VERSION ""

NS_ :

BS_:

BU_: Skylark_EV

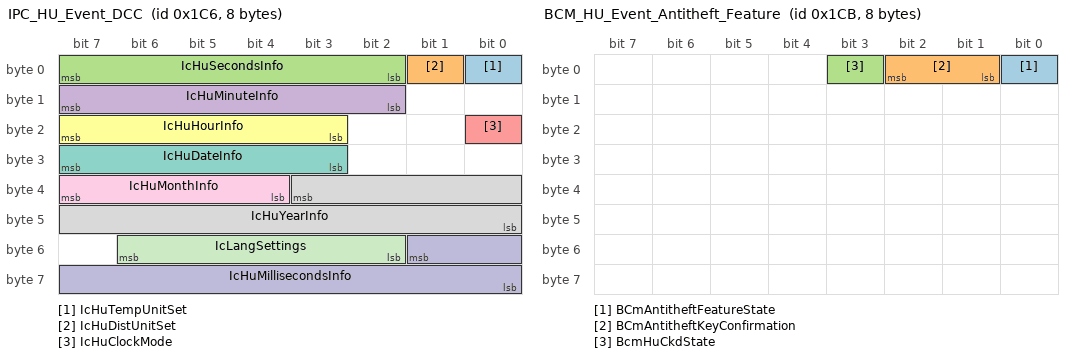
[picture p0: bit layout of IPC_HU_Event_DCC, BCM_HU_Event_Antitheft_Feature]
BO_ 454 IPC_HU_Event_DCC: 8 Vector__XXX
 SG_ IcHuTempUnitSet : 0|1@0+ (1,0) [0|1] ""  Skylark_EV
 SG_ IcHuDistUnitSet : 1|1@0+ (1,0) [0|1] ""  Skylark_EV
 SG_ IcHuSecondsInfo : 7|6@0+ (1,0) [0|59] "sec."  Skylark_EV
 SG_ IcHuMinuteInfo : 15|6@0+ (1,0) [0|59] "min"  Skylark_EV
 SG_ IcHuClockMode : 16|1@0+ (1,0) [0|1] ""  Skylark_EV
 SG_ IcHuHourInfo : 23|5@0+ (1,0) [0|23] "hr"  Skylark_EV
 SG_ IcHuDateInfo : 31|5@0+ (1,0) [0|31] ""  Skylark_EV
 SG_ IcHuYearInfo : 35|12@0+ (1,0) [0|4095] ""  Skylark_EV
 SG_ IcHuMonthInfo : 39|4@0+ (1,0) [0|15] ""  Skylark_EV
 SG_ IcHuMillisecondsInfo : 49|10@0+ (1,0) [0|999] "ms"  Skylark_EV
 SG_ IcLangSettings : 54|5@0+ (1,0) [0|31] ""  Skylark_EV

BO_ 459 BCM_HU_Event_Antitheft_Feature: 8 Vector__XXX
 SG_ BCmAntitheftFeatureState : 0|1@0+ (1,0) [0|1] ""  Skylark_EV
 SG_ BCmAntitheftKeyConfirmation : 2|2@0+ (1,0) [0|3] ""  Skylark_EV
 SG_ BcmHuCkdState : 3|1@0+ (1,0) [0|1] ""  Skylark_EV

BO_ 460 HU_BCM_Event_Antitheft_Feature: 8 Skylark_EV
 SG_ HuAntitheftFeatureState : 0|1@0+ (1,0) [0|1] "" Vector__XXX
 SG_ HuBcmQueryInfo : 2|2@0+ (1,0) [0|3] "" Vector__XXX

BO_ 462 BCM_HU_Event_Antitheft_Seed: 8 Vector__XXX
 SG_ BCmAntitheftSeed : 7|32@0+ (1,0) [0|4294967295] ""  Skylark_EV

BO_ 463 HU_BCM_Event_Antitheftkey: 8 Skylark_EV
 SG_ BCmAntitheftKey : 7|32@0+ (1,0) [0|4294967295] "" Vector__XXX

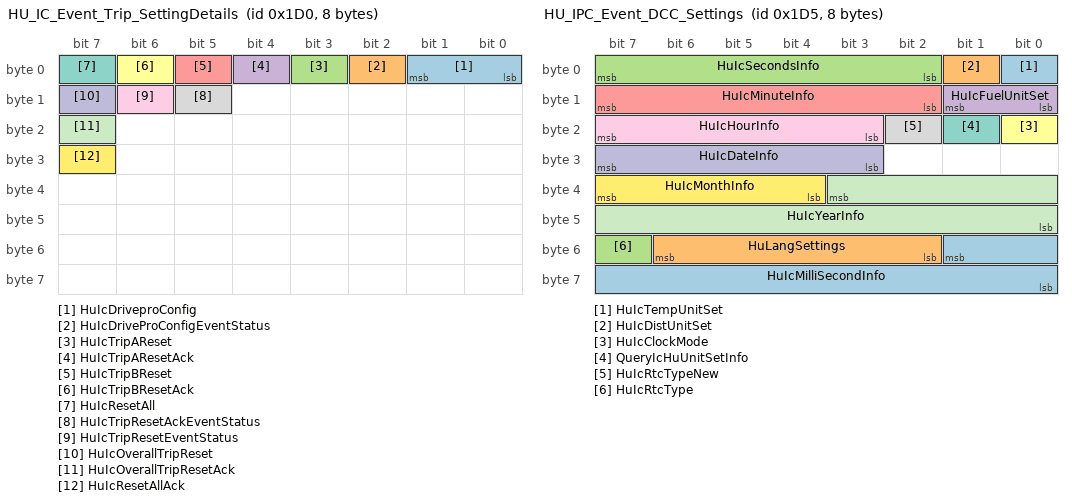
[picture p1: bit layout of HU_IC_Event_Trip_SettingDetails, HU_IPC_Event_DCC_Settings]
BO_ 464 HU_IC_Event_Trip_SettingDetails: 8 Skylark_EV
 SG_ HuIcDriveproConfig : 1|2@0+ (1,0) [0|3] "" Vector__XXX
 SG_ HuIcDriveProConfigEventStatus : 2|1@0+ (1,0) [0|1] "" Vector__XXX
 SG_ HuIcTripAReset : 3|1@0+ (1,0) [0|1] "" Vector__XXX
 SG_ HuIcTripAResetAck : 4|1@0+ (1,0) [0|1] "" Vector__XXX
 SG_ HuIcTripBReset : 5|1@0+ (1,0) [0|1] "" Vector__XXX
 SG_ HuIcTripBResetAck : 6|1@0+ (1,0) [0|1] "" Vector__XXX
 SG_ HuIcResetAll : 7|1@0+ (1,0) [0|1] "" Vector__XXX
 SG_ HuIcTripResetAckEventStatus : 13|1@0+ (1,0) [0|1] "" Vector__XXX
 SG_ HuIcTripResetEventStatus : 14|1@0+ (1,0) [0|1] "" Vector__XXX
 SG_ HuIcOverallTripReset : 15|1@0+ (1,0) [0|1] "" Vector__XXX
 SG_ HuIcOverallTripResetAck : 23|1@0+ (1,0) [0|1] "" Vector__XXX
 SG_ HuIcResetAllAck : 31|1@0+ (1,0) [0|1] "" Vector__XXX

BO_ 466 HU_PDC_Event: 8 Skylark_EV
 SG_ PDcOnDelayTimerReq : 7|8@0+ (1,0) [0|255] "sec" Vector__XXX
 SG_ HuPDcVehicleImageAck : 10|3@0+ (1,0) [0|7] "" Vector__XXX
 SG_ PDcLowSpeedActivationReq : 11|1@0+ (1,0) [0|1] "" Vector__XXX
 SG_ PDcRearToneReq : 15|4@0+ (1,0) [0|15] "" Vector__XXX
 SG_ HuPDcFrontAudioMuteStateAck : 16|1@0+ (1,0) [0|1] "" Vector__XXX
 SG_ HuPDcRearNoOfSensAck : 19|3@0+ (1,0) [0|7] "" Vector__XXX
 SG_ PDcToneVolumeReq : 23|4@0+ (1,0) [1|15] "" Vector__XXX
 SG_ HuPDcOnDelayTimerAck : 31|8@0+ (1,0) [0|255] "sec" Vector__XXX
 SG_ PDcFrontAudioMuteReq : 32|1@0+ (1,0) [0|1] "" Vector__XXX
 SG_ HuPDcReqType : 35|3@0+ (1,0) [0|7] "" Vector__XXX
 SG_ HuPDcRearToneAck : 39|4@0+ (1,0) [0|15] "" Vector__XXX
 SG_ HuPDcFrontToneAck : 43|4@0+ (1,0) [0|15] "" Vector__XXX
 SG_ HuPDcToneVolumeAck : 47|4@0+ (1,0) [0|15] "" Vector__XXX
 SG_ HuPDcFrontNoOfSensAck : 50|3@0+ (1,0) [0|7] "" Vector__XXX
 SG_ PDcFrontToneReq : 54|4@0+ (1,0) [0|15] "" Vector__XXX
 SG_ HuPDCFrontActivationStateAck : 55|1@0+ (1,0) [0|1] "" Vector__XXX
 SG_ PDcFrontActivationStateReq : 56|1@0+ (1,0) [0|1] "" Vector__XXX
 SG_ HuPDCLowSpeedActivationAck : 57|1@0+ (1,0) [0|1] "" Vector__XXX
 SG_ RVcOverlayTypeAck : 58|1@0+ (1,0) [0|1] "" Vector__XXX
 SG_ RVcImageRotationTypeAck : 59|1@0+ (1,0) [0|1] "" Vector__XXX

BO_ 469 HU_IPC_Event_DCC_Settings: 8 Skylark_EV
 SG_ HuIcTempUnitSet : 0|1@0+ (1,0) [0|1] "" Vector__XXX
 SG_ HuIcDistUnitSet : 1|1@0+ (1,0) [0|1] "" Vector__XXX
 SG_ HuIcSecondsInfo : 7|6@0+ (1,0) [0|59] "sec." Vector__XXX
 SG_ HuIcFuelUnitSet : 9|2@0+ (1,0) [0|3] "" Vector__XXX
 SG_ HuIcMinuteInfo : 15|6@0+ (1,0) [0|59] "min" Vector__XXX
 SG_ HuIcClockMode : 16|1@0+ (1,0) [0|1] "" Vector__XXX
 SG_ QueryIcHuUnitSetInfo : 17|1@0+ (1,0) [0|1] "" Vector__XXX
 SG_ HuIcRtcTypeNew : 18|1@0+ (1,0) [0|1] "" Vector__XXX
 SG_ HuIcHourInfo : 23|5@0+ (1,0) [0|23] "hr" Vector__XXX
 SG_ HuIcDateInfo : 31|5@0+ (1,0) [0|31] "" Vector__XXX
 SG_ HuIcYearInfo : 35|12@0+ (1,0) [0|4095] "" Vector__XXX
 SG_ HuIcMonthInfo : 39|4@0+ (1,0) [0|15] "" Vector__XXX
 SG_ HuIcMilliSecondInfo : 49|10@0+ (1,0) [0|999] "ms" Vector__XXX
 SG_ HuLangSettings : 54|5@0+ (1,0) [0|31] "" Vector__XXX
 SG_ HuIcRtcType : 55|1@0+ (1,0) [0|1] "" Vector__XXX

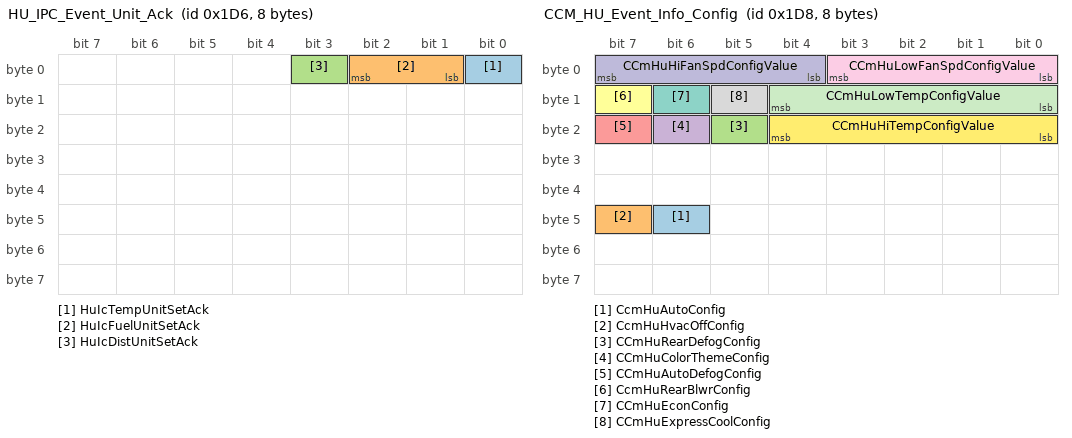
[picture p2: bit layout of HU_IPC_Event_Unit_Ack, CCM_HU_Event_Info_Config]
BO_ 470 HU_IPC_Event_Unit_Ack: 8 Skylark_EV
 SG_ HuIcTempUnitSetAck : 0|1@0+ (1,0) [0|1] "" Vector__XXX
 SG_ HuIcFuelUnitSetAck : 2|2@0+ (1,0) [0|3] "" Vector__XXX
 SG_ HuIcDistUnitSetAck : 3|1@0+ (1,0) [0|1] "" Vector__XXX

BO_ 472 CCM_HU_Event_Info_Config: 8 Vector__XXX
 SG_ CcmHuAutoConfig : 46|1@0+ (1,0) [0|1] ""  Skylark_EV
 SG_ CcmHuHvacOffConfig : 47|1@0+ (1,0) [0|1] ""  Skylark_EV
 SG_ CCmHuRearDefogConfig : 21|1@0+ (1,0) [0|1] ""  Skylark_EV
 SG_ CCmHuColorThemeConfig : 22|1@0+ (1,0) [0|1] ""  Skylark_EV
 SG_ CCmHuAutoDefogConfig : 23|1@0+ (1,0) [0|1] ""  Skylark_EV
 SG_ CcmHuRearBlwrConfig : 15|1@0+ (1,0) [0|1] ""  Skylark_EV
 SG_ CCmHuEconConfig : 14|1@0+ (1,0) [0|1] ""  Skylark_EV
 SG_ CCmHuExpressCoolConfig : 13|1@0+ (1,0) [0|1] ""  Skylark_EV
 SG_ CCmHuLowFanSpdConfigValue : 3|4@0+ (1,0) [0|15] ""  Skylark_EV
 SG_ CCmHuHiFanSpdConfigValue : 7|4@0+ (1,0) [0|15] ""  Skylark_EV
 SG_ CCmHuLowTempConfigValue : 12|5@0+ (0.5,0) [0|31] "Deg "  Skylark_EV
 SG_ CCmHuHiTempConfigValue : 20|5@0+ (0.5,0) [0|31] "Deg "  Skylark_EV

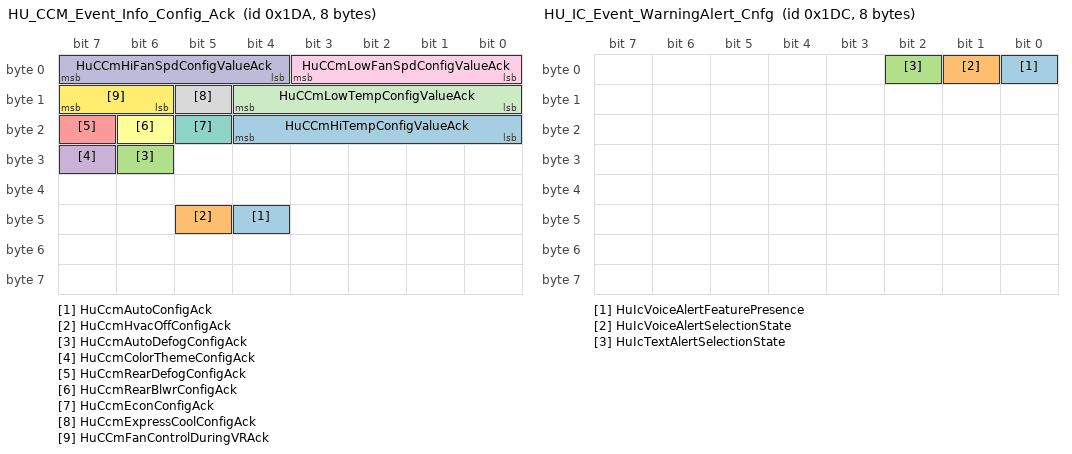
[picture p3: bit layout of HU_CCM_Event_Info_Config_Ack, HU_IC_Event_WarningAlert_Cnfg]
BO_ 474 HU_CCM_Event_Info_Config_Ack: 8 Skylark_EV
 SG_ HuCcmAutoConfigAck : 44|1@0+ (1,0) [0|1] "" Vector__XXX
 SG_ HuCcmHvacOffConfigAck : 45|1@0+ (1,0) [0|1] "" Vector__XXX
 SG_ HuCcmAutoDefogConfigAck : 30|1@0+ (1,0) [0|1] "" Vector__XXX
 SG_ HuCcmColorThemeConfigAck : 31|1@0+ (1,0) [0|1] "" Vector__XXX
 SG_ HuCcmRearDefogConfigAck : 23|1@0+ (1,0) [0|1] "" Vector__XXX
 SG_ HuCcmRearBlwrConfigAck : 22|1@0+ (1,0) [0|1] "" Vector__XXX
 SG_ HuCcmEconConfigAck : 21|1@0+ (1,0) [0|1] "" Vector__XXX
 SG_ HuCcmExpressCoolConfigAck : 13|1@0+ (1,0) [0|1] "" Vector__XXX
 SG_ HuCCmLowFanSpdConfigValueAck : 3|4@0+ (1,0) [0|15] "" Vector__XXX
 SG_ HuCCmHiFanSpdConfigValueAck : 7|4@0+ (1,0) [0|15] "" Vector__XXX
 SG_ HuCCmLowTempConfigValueAck : 12|5@0+ (0.5,0) [0|31] "Deg " Vector__XXX
 SG_ HuCCmFanControlDuringVRAck : 15|2@0+ (1,0) [0|3] "" Vector__XXX
 SG_ HuCCmHiTempConfigValueAck : 20|5@0+ (0.5,0) [0|31] "Deg " Vector__XXX

BO_ 475 HU_IC_Event_WarningAlert_Ack: 8 Skylark_EV
 SG_ HuIcAlertFeatureTypeAck : 5|2@0+ (1,0) [0|3] "" Vector__XXX
 SG_ HuIcAlertFeaturePresenceAck : 7|1@0+ (1,0) [0|1] "" Vector__XXX

BO_ 476 HU_IC_Event_WarningAlert_Cnfg: 8 Skylark_EV
 SG_ HuIcVoiceAlertFeaturePresence : 0|1@0+ (1,0) [0|1] "" Vector__XXX
 SG_ HuIcVoiceAlertSelectionState : 1|1@0+ (1,0) [0|1] "" Vector__XXX
 SG_ HuIcTextAlertSelectionState : 2|1@0+ (1,0) [0|1] "" Vector__XXX

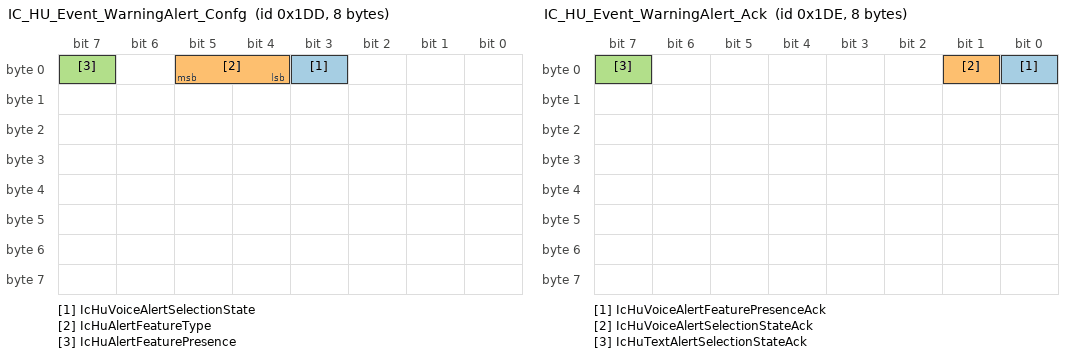
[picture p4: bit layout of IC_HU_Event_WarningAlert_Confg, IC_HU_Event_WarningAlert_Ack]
BO_ 477 IC_HU_Event_WarningAlert_Confg: 8 Vector__XXX
 SG_ IcHuVoiceAlertSelectionState : 3|1@0+ (1,0) [0|1] ""  Skylark_EV
 SG_ IcHuAlertFeatureType : 5|2@0+ (1,0) [0|3] ""  Skylark_EV
 SG_ IcHuAlertFeaturePresence : 7|1@0+ (1,0) [0|1] ""  Skylark_EV

BO_ 478 IC_HU_Event_WarningAlert_Ack: 8 Vector__XXX
 SG_ IcHuVoiceAlertFeaturePresenceAck : 0|1@0+ (1,0) [0|1] ""  Skylark_EV
 SG_ IcHuVoiceAlertSelectionStateAck : 1|1@0+ (1,0) [0|1] ""  Skylark_EV
 SG_ IcHuTextAlertSelectionStateAck : 7|1@0+ (1,0) [0|1] ""  Skylark_EV

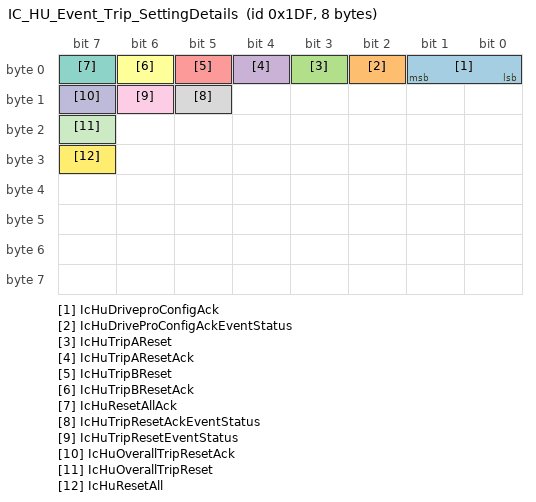
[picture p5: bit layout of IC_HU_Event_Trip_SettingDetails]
BO_ 479 IC_HU_Event_Trip_SettingDetails: 8 Vector__XXX
 SG_ IcHuDriveproConfigAck : 1|2@0+ (1,0) [0|3] ""  Skylark_EV
 SG_ IcHuDriveProConfigAckEventStatus : 2|1@0+ (1,0) [0|1] ""  Skylark_EV
 SG_ IcHuTripAReset : 3|1@0+ (1,0) [0|1] ""  Skylark_EV
 SG_ IcHuTripAResetAck : 4|1@0+ (1,0) [0|1] ""  Skylark_EV
 SG_ IcHuTripBReset : 5|1@0+ (1,0) [0|1] ""  Skylark_EV
 SG_ IcHuTripBResetAck : 6|1@0+ (1,0) [0|1] ""  Skylark_EV
 SG_ IcHuResetAllAck : 7|1@0+ (1,0) [0|1] ""  Skylark_EV
 SG_ IcHuTripResetAckEventStatus : 13|1@0+ (1,0) [0|1] ""  Skylark_EV
 SG_ IcHuTripResetEventStatus : 14|1@0+ (1,0) [0|1] ""  Skylark_EV
 SG_ IcHuOverallTripResetAck : 15|1@0+ (1,0) [0|1] ""  Skylark_EV
 SG_ IcHuOverallTripReset : 23|1@0+ (1,0) [0|1] ""  Skylark_EV
 SG_ IcHuResetAll : 31|1@0+ (1,0) [0|1] ""  Skylark_EV

BO_ 490 PEPSVIdeninfoEvent: 8 Vector__XXX
 SG_ VInInfoToIPC : 7|40@0+ (1,0) [0|0] ""  Skylark_EV

BO_ 497 HU_CCM_Event_Info: 8 Skylark_EV
 SG_ HuCcmRearBlwrOnOffReq : 39|1@0+ (1,0) [0|1] "" Vector__XXX
 SG_ HuCcmExpressCoolSwitchReq : 32|1@0+ (1,0) [0|1] "" Vector__XXX
 SG_ HuCCmFanSpdReq : 3|4@0+ (1,0) [0|15] "" Vector__XXX
 SG_ HuCCmDistribReq : 6|3@0+ (1,0) [0|7] "" Vector__XXX
 SG_ HuCCmDualModeReq : 7|1@0+ (1,0) [0|1] "" Vector__XXX
 SG_ HuCCmTempReqPass : 12|5@0+ (0.5,0) [0|31] "Deg " Vector__XXX
 SG_ HuCCmFreshAirRecircReq : 14|2@0+ (1,0) [0|3] "" Vector__XXX
 SG_ HuCCmAutoReq : 15|1@0+ (1,0) [0|1] "" Vector__XXX
 SG_ HuCCmTempReq : 20|5@0+ (0.5,0) [0|31] "Deg " Vector__XXX
 SG_ HuCCmEconModeReq : 21|1@0+ (1,0) [0|1] "" Vector__XXX
 SG_ HuCCmMaxDefrstReq : 22|1@0+ (1,0) [0|1] "" Vector__XXX
 SG_ HuCCmRearDefogReq : 23|1@0+ (1,0) [0|1] "" Vector__XXX
 SG_ HuCCmTempReqDrvr : 28|5@0+ (0.5,0) [0|31] "Deg " Vector__XXX
 SG_ HuCCmAirConCompReq : 29|1@0+ (1,0) [0|1] "" Vector__XXX
 SG_ HuCCmHVAcOFFReq : 30|1@0+ (1,0) [0|1] "" Vector__XXX
 SG_ HuCCmQueryFlag : 31|1@0+ (1,0) [0|1] "" Vector__XXX
 SG_ HuCCmUserInterventionStatusFlag : 37|5@0+ (1,0) [0|31] "" Vector__XXX

CM_ SG_ 454 IcHuTempUnitSet "Temp unit send by IC to HU.";
CM_ SG_ 454 IcHuDistUnitSet "Distance Unit send by IC to HU.";
CM_ SG_ 454 IcHuSecondsInfo "Status of Seconds Information";
CM_ SG_ 454 IcHuMinuteInfo "Minute Information on HU from IC";
CM_ SG_ 454 IcHuClockMode "Clock Mode Information on HU from IC.";
CM_ SG_ 454 IcHuHourInfo "Hour Information on HU from IC";
CM_ SG_ 454 IcHuDateInfo "Date Information on HU from IC.";
CM_ SG_ 454 IcHuYearInfo "Year Information on HU from IC";
CM_ SG_ 454 IcHuMonthInfo "Month Information on HU from IC.";
CM_ SG_ 454 IcHuMillisecondsInfo "MilliSeconds Information on HU from IC.";
CM_ SG_ 454 IcLangSettings "IC shall publish language settings information to HU.(Not to be implemented in D and E Variant ) ";
CM_ SG_ 459 BCmAntitheftFeatureState "This signal is output from BCM  to identify HU Anti-theft feature activation/ deactivation state.";
CM_ SG_ 459 BCmAntitheftKeyConfirmation "BCM send this signal to HU for key confirmation state.";
CM_ SG_ 459 BcmHuCkdState "BCM send the type of vehicle (i.e. CKD or Non-CKD) to HU.";
CM_ SG_ 460 HuAntitheftFeatureState "This signal is input to BCM  to identify HU Anti-theft feature activation / deactivation state.";
CM_ SG_ 460 HuBcmQueryInfo "On IGN ON, if HU doesnot get BcmAntitheftFeatureState from BCM, then HU sends the query to BCM to restart the pairing process.Also during pairing process, if HU doesn¿t receive SEED from BCM, then HU sends the query to BCM to restart the pairing process.";
CM_ BO_ 462 "This signal is output from BCM  to identify HU Anti-theft feature activation/ deactivation state.";
CM_ SG_ 462 BCmAntitheftSeed "BCM send this signal to Infotainment ECU for seed information state.";
CM_ SG_ 463 BCmAntitheftKey "BCM receives this signal from HU to know the key information state.";
CM_ SG_ 464 HuIcDriveproConfig "HU shall send Drive Pro Config to IC";
CM_ SG_ 464 HuIcDriveProConfigEventStatus "HU shall send Trip Config Event Status to IC";
CM_ SG_ 464 HuIcTripAReset "HU shall send Trip A Reset to IC";
CM_ SG_ 464 HuIcTripAResetAck "HU shall send Trip A Reset Ack to IC";
CM_ SG_ 464 HuIcTripBReset "HU shall send Trip B Reset to IC";
CM_ SG_ 464 HuIcTripBResetAck "HU shall send Trip B Reset Ack to IC";
CM_ SG_ 464 HuIcResetAll "HU shall send Reset All to IC";
CM_ SG_ 464 HuIcTripResetAckEventStatus "HU shall send Trip Reset Ack Event Status to IC";
CM_ SG_ 464 HuIcTripResetEventStatus "HU shall send Trip Reset Event Status to IC";
CM_ SG_ 464 HuIcOverallTripReset "HU shall send Overall trip Reset to IC";
CM_ SG_ 464 HuIcOverallTripResetAck "HU shall send overall Trip Reset Ack to IC";
CM_ SG_ 464 HuIcResetAllAck "HU shall send All Trip Reset Ack to IC";
CM_ SG_ 466 PDcOnDelayTimerReq "This input signal to PDC is to update PDC Delay Timer settings.
";
CM_ SG_ 466 HuPDcVehicleImageAck "On every IGN ON, HU shall acknowledge to  PDC's config info.";
CM_ SG_ 466 PDcLowSpeedActivationReq "This input signal to PDC is to update the low speed activation request";
CM_ SG_ 466 PDcRearToneReq "This input signal to PDC is to update PDC Tone selection settings.";
CM_ SG_ 466 HuPDcFrontAudioMuteStateAck "On every IGN ON, HU shall acknowledge to  front PDC's config info.";
CM_ SG_ 466 HuPDcRearNoOfSensAck "On every IGN ON, HU shall acknowledge to  PDC's config info.";
CM_ SG_ 466 PDcToneVolumeReq "This input signal to PDC is to update PDC Tone Volume settings.";
CM_ SG_ 466 HuPDcOnDelayTimerAck "On every IGN ON, HU shall acknowledge to  PDC's config info. .
";
CM_ SG_ 466 PDcFrontAudioMuteReq "This input signal to PDC is to update the front  mute status.";
CM_ SG_ 466 HuPDcReqType "this input signal is to PDC is to know the request type from HU";
CM_ SG_ 466 HuPDcRearToneAck "On every IGN ON, HU shall acknowledge to  PDC's config info.";
CM_ SG_ 466 HuPDcFrontToneAck "On every IGN ON, HU shall acknowledge to  front PDC's config info.";
CM_ SG_ 466 HuPDcToneVolumeAck "On every IGN ON, HU shall acknowledge to  PDC's config info.";
CM_ SG_ 466 HuPDcFrontNoOfSensAck "On every IGN ON, HU shall acknowledge to front PDC's config info.";
CM_ SG_ 466 PDcFrontToneReq "This input signal to BCM PDC fucntion is to update PDC Tone selection status.";
CM_ SG_ 466 HuPDCFrontActivationStateAck "This signal is used an input from HU shall to acknowledge front PDC activation state acknowledgement";
CM_ SG_ 466 PDcFrontActivationStateReq "This signal is used an input from HU shall to acknowledge front PDC activation state acknowledgement";
CM_ SG_ 466 HuPDCLowSpeedActivationAck "This signal is used an input from HU shall to acknowledge low speed activation acknowledgement";
CM_ SG_ 466 RVcOverlayTypeAck "This signal is used as an input from HU to acknowledge the RVC overlay";
CM_ SG_ 466 RVcImageRotationTypeAck "This signal is used as an input from HU to acknowledge image roation type";
CM_ SG_ 469 HuIcTempUnitSet "Temp unit send by HU to IC.";
CM_ SG_ 469 HuIcDistUnitSet "Distance Unit send by HU to IC.";
CM_ SG_ 469 HuIcSecondsInfo "Seconds Information on IC from HU.";
CM_ SG_ 469 HuIcFuelUnitSet "Fuel Unit send by HU to IC.";
CM_ SG_ 469 HuIcMinuteInfo "Minute Information on IC from HU";
CM_ SG_ 469 HuIcClockMode "Clock Mode Information on IC from HU.";
CM_ SG_ 469 QueryIcHuUnitSetInfo "Query by HU to IC.";
CM_ SG_ 469 HuIcRtcTypeNew "Clock Mode Information on IC from HU";
CM_ SG_ 469 HuIcHourInfo "Hour Information on IC from HU.";
CM_ SG_ 469 HuIcDateInfo "Date Information on IC from HU.";
CM_ SG_ 469 HuIcYearInfo "Year Information on IC from HU";
CM_ SG_ 469 HuIcMonthInfo "Month Information on HU from IC.";
CM_ SG_ 469 HuIcMilliSecondInfo "milliseconds Information on IC from HU.";
CM_ SG_ 469 HuLangSettings "HU shall publish language settings information to IPC.";
CM_ SG_ 469 HuIcRtcType "Clock Mode Information on IC from HU";
CM_ SG_ 470 HuIcTempUnitSetAck "Temp unit send by HU to IC.";
CM_ SG_ 470 HuIcFuelUnitSetAck "Fuel acknowledgement send by HU to IC.";
CM_ SG_ 470 HuIcDistUnitSetAck "Distance acknowledgement send by HU to IC";
CM_ SG_ 472 CcmHuAutoConfig "Indicates the availability of Auto switch in HU";
CM_ SG_ 472 CcmHuHvacOffConfig "Indicates the availability of HVAC OFF/ON switch  in HU";
CM_ SG_ 472 CCmHuRearDefogConfig "indicates the Rear Defogger feature availability";
CM_ SG_ 472 CCmHuColorThemeConfig "Indicates the availability of Color Theme feature.";
CM_ SG_ 472 CCmHuAutoDefogConfig "Indicates the availability of Auto Defog feature.";
CM_ SG_ 472 CcmHuRearBlwrConfig "Indicates the availability of Rear Blower feature.";
CM_ SG_ 472 CCmHuEconConfig "Indicates the availability of ECON feature for the ECU under consideration";
CM_ SG_ 472 CCmHuExpressCoolConfig "Indicates the availability of Express cooling feature for the ECU under consideration";
CM_ SG_ 472 CCmHuLowFanSpdConfigValue "Indicates the lower configuration fan speed value for the ECU under consideration";
CM_ SG_ 472 CCmHuHiFanSpdConfigValue "Indicates the higher configuration fan speed value for the ECU under consideration";
CM_ SG_ 472 CCmHuLowTempConfigValue "Indicates the lower configuration temperature value for the ECU under consideration(physical range shall be considered as LO,16 to 30,HI)";
CM_ SG_ 472 CCmHuHiTempConfigValue "Indicates the higher configuration temperature value for the ECU under consideration(physical range shall be considered as LO,16 to 30,HI)";
CM_ SG_ 474 HuCcmAutoConfigAck "HU Acknowledges the Auto Switch availability configuartion value for the ECU under consideration";
CM_ SG_ 474 HuCcmHvacOffConfigAck "HU Acknowledges the HVAC OFF Switch availability configuartion value for the ECU under consideration";
CM_ SG_ 474 HuCcmAutoDefogConfigAck "HU Acknowledges the Auto Defog feature availability configuartion value for the ECU under consideration";
CM_ SG_ 474 HuCcmColorThemeConfigAck "HU Acknowledges the Color Theme feature availability configuartion value for the ECU under consideration";
CM_ SG_ 474 HuCcmRearDefogConfigAck "HU Acknowledges the Rear Defogger feature availability configuartion value for the ECU under consideration";
CM_ SG_ 474 HuCcmRearBlwrConfigAck "HU Acknowledges the Rear Blower feature availability configuartion value for the ECU under consideration.";
CM_ SG_ 474 HuCcmEconConfigAck "HU Acknowledges the ECON feature availability configuartion value for the ECU under consideration";
CM_ SG_ 474 HuCcmExpressCoolConfigAck "HU Acknowledges the express cooling feature availability configuartion value for the ECU under consideration";
CM_ SG_ 474 HuCCmLowFanSpdConfigValueAck "Acknowledge  the lower configuration fan speed value for the ECU under consideration";
CM_ SG_ 474 HuCCmHiFanSpdConfigValueAck "Acknowledge the higher configuration fan speed value for the ECU under consideration";
CM_ SG_ 474 HuCCmLowTempConfigValueAck "Acknowledge  the lower configuration temperature value for the ECU under consideration";
CM_ SG_ 474 HuCCmFanControlDuringVRAck "Acknowledge from HU to CCM for FAN speed control";
CM_ SG_ 474 HuCCmHiTempConfigValueAck "Acknowledge  the higher configuration temperature value for the ECU under consideration";
CM_ SG_ 475 HuIcAlertFeatureTypeAck "This signal is transmitted to IC to acknowledge after HMI settings";
CM_ SG_ 475 HuIcAlertFeaturePresenceAck "Ack from HU for Alert feature presence";
CM_ SG_ 476 HuIcVoiceAlertFeaturePresence "This signal is transmitted to IC to know voice alert feature presence in vehicle.";
CM_ SG_ 476 HuIcVoiceAlertSelectionState "This signal is transmitted to IC to know selection state of voice alert feature..";
CM_ SG_ 476 HuIcTextAlertSelectionState "Informs Text alert selection state";
CM_ SG_ 477 IcHuVoiceAlertSelectionState "HU shall update the Voice Alert HMI selection state";
CM_ SG_ 477 IcHuAlertFeatureType "Informs the type of alert configured in cluster";
CM_ SG_ 477 IcHuAlertFeaturePresence "Informes whether Alert feature is enabled or not";
CM_ SG_ 478 IcHuVoiceAlertFeaturePresenceAck "This signal is transmitted to HU to know voice alert feature presence in vehicle";
CM_ SG_ 478 IcHuVoiceAlertSelectionStateAck "This signal is transmitted to HU to know selection state of voice alert feature.";
CM_ SG_ 478 IcHuTextAlertSelectionStateAck "Informes ack state of Text alert selection state";
CM_ SG_ 479 IcHuDriveproConfigAck "IC shall send drive pro config Ack to HU";
CM_ SG_ 479 IcHuDriveProConfigAckEventStatus "IC shall send Trip Config Ack Event Status to HU";
CM_ SG_ 479 IcHuTripAReset "IC shall send Trip A Reset to HU";
CM_ SG_ 479 IcHuTripAResetAck "IC shall send Trip A Reset Ack to HU";
CM_ SG_ 479 IcHuTripBReset "IC shall send Trip B Reset to HU";
CM_ SG_ 479 IcHuTripBResetAck "IC shall send Trip B Reset Ack to HU";
CM_ SG_ 479 IcHuResetAllAck "IC shall send Reset All Ack to HU";
CM_ SG_ 479 IcHuTripResetAckEventStatus "IC shall send Trip Reset Ack Event Status to HU";
CM_ SG_ 479 IcHuTripResetEventStatus "IC shall send Trip Reset Event Status to HU";
CM_ SG_ 479 IcHuOverallTripResetAck "IC shall send Overall trip Reset Ack to HU";
CM_ SG_ 479 IcHuOverallTripReset "IC shall send overall Trip Reset to HU";
CM_ SG_ 479 IcHuResetAll "IC shall send Trip A, B and Overall Reset to HU";
CM_ SG_ 497 HuCcmRearBlwrOnOffReq "Transmit Rear Blower ON/OFF Request to CCM.";
CM_ SG_ 497 HuCcmExpressCoolSwitchReq "Request/Acknowledgement for Express Cooling feature ON or OFF";
CM_ SG_ 497 HuCCmFanSpdReq "Indicates the speed of the fan";
CM_ SG_ 497 HuCCmDistribReq "Indicates different value of distribution mode";
CM_ SG_ 497 HuCCmDualModeReq "Indicates whether the dual mode is ON or OFF";
CM_ SG_ 497 HuCCmTempReqPass "Indicates the left temperature value in Deg";
CM_ SG_ 497 HuCCmFreshAirRecircReq "Indicates the different values of fresh air recirculation mode";
CM_ SG_ 497 HuCCmAutoReq "Request for Auto mode ON or OFF";
CM_ SG_ 497 HuCCmTempReq "Indicates the temperature value in OC";
CM_ SG_ 497 HuCCmEconModeReq "Request to set the Economy mode to ON or OFF";
CM_ SG_ 497 HuCCmMaxDefrstReq "Request for maximum defrost control ON or OFF";
CM_ SG_ 497 HuCCmRearDefogReq "Request to change the  defog control to ON or OFF";
CM_ SG_ 497 HuCCmTempReqDrvr "Indicates the right temperature value OC";
CM_ SG_ 497 HuCCmAirConCompReq "request to set the AC to ON or OFF";
CM_ SG_ 497 HuCCmHVAcOFFReq "Request to turn ON or OFF the HVAC control panel";
CM_ SG_ 497 HuCCmQueryFlag "Query the CCM to send the missing Ack frame";
CM_ SG_ 497 HuCCmUserInterventionStatusFlag "Indicates which HVAC control user has operated";
BA_DEF_ SG_  "Remarks" STRING ;
BA_DEF_ SG_  "NWM_WakeupAllowed" ENUM  "No","Yes";
BA_DEF_ SG_  "GenSigTimeoutTime_HU_Mid_X451" INT 0 65535;
BA_DEF_ SG_  "GenSigTimeoutTime_HU_High_X451" INT 0 65535;
BA_DEF_ SG_  "GenSigTimeoutTime_HU_B" INT 0 65535;
BA_DEF_ SG_  "GenSigTimeoutTime_HU_A" INT 0 65535;
BA_DEF_ SG_  "GenSigTimeoutTime_BCM_Mid" INT 0 65535;
BA_DEF_ SG_  "GenSigTimeoutMsg_HU_Mid_X451" INT 0 65535;
BA_DEF_ SG_  "GenSigTimeoutMsg_HU_High_X451" INT 0 65535;
BA_DEF_ SG_  "GenSigTimeoutMsg_HU_B" INT 0 65535;
BA_DEF_ SG_  "GenSigTimeoutMsg_HU_A" INT 0 65535;
BA_DEF_ SG_  "GenSigStartValue" INT 0 0;
BA_DEF_ SG_  "GenSigSendType" ENUM  "Cyclic","OnWrite","OnWriteWithRepetition","OnChange","OnChangeWithRepetition","IfActive","IfActiveWithRepetition","NoSigSendType","NotUsed","NotUsed","NotUsed","NotUsed","NotUsed";
BA_DEF_ SG_  "GenSigInactiveValue" INT 0 0;
BA_DEF_ SG_  "GenSigEnvVarType" ENUM  "int","float","undef";
BA_DEF_ SG_  "GenSigCycleTimeActive" INT 0 0;
BA_DEF_ SG_  "GenSigCycleTime" INT 0 0;
BA_DEF_ SG_  "GenSigTimeoutMsg_HU_High_X445" INT 0 65535;
BA_DEF_ SG_  "GenSigTimeoutMsg_HU_Mid_X445" INT 0 65535;
BA_DEF_ SG_  "GenSigTimeoutTime_HU_High_X445" INT 0 65535;
BA_DEF_ SG_  "GenSigTimeoutTime_HU_Mid_X445" INT 0 65535;
BA_DEF_ SG_  "GenSigTimeoutMsg_IVI" INT 0 65535;
BA_DEF_ SG_  "GenSigTimeoutTime_IVI" INT 0 65535;
BA_DEF_ BO_  "NmMessage" ENUM  "no","yes";
BA_DEF_ BO_  "NmAsrMessage" ENUM  "<n.a.>","No","Yes";
BA_DEF_ BO_  "MessageTimeout" INT 0 65535;
BA_DEF_ BO_  "GenMsgStartDelayTime" INT 0 0;
BA_DEF_ BO_  "GenMsgSendType" ENUM  "Cyclic","NotUsed","NotUsed","NotUsed","NotUsed","NotUsed","NotUsed","IfActive","NoMsgSendType","NotUsed";
BA_DEF_ BO_  "GenMsgNrOfRepetition" INT 0 0;
BA_DEF_ BO_  "GenMsgILSupport" ENUM  "No","Yes";
BA_DEF_ BO_  "GenMsgDelayTime" INT 0 0;
BA_DEF_ BO_  "GenMsgCycleTimeFast" INT 0 0;
BA_DEF_ BO_  "GenMsgCycleTime" INT 0 0;
BA_DEF_ BO_  "DiagUudtResponse" ENUM  "false","true";
BA_DEF_ BO_  "DiagUsdtResponse" ENUM  "false","true";
BA_DEF_ BO_  "DiagState" ENUM  "No","Yes";
BA_DEF_ BO_  "DiagResponse" ENUM  "No","Yes";
BA_DEF_ BO_  "DiagRequest" ENUM  "No","Yes";
BA_DEF_ BO_  "MsgType" ENUM  "Application","NM","NMH";
BA_DEF_ SG_  "SystemSignalLongSymbol" STRING ;
BA_DEF_DEF_  "Remarks" "null";
BA_DEF_DEF_  "NWM_WakeupAllowed" "No";
BA_DEF_DEF_  "GenSigTimeoutTime_HU_Mid_X451" 500;
BA_DEF_DEF_  "GenSigTimeoutTime_HU_High_X451" 500;
BA_DEF_DEF_  "GenSigTimeoutTime_HU_B" 500;
BA_DEF_DEF_  "GenSigTimeoutTime_HU_A" 500;
BA_DEF_DEF_  "GenSigTimeoutTime_BCM_Mid" 0;
BA_DEF_DEF_  "GenSigTimeoutMsg_HU_Mid_X451" 500;
BA_DEF_DEF_  "GenSigTimeoutMsg_HU_High_X451" 500;
BA_DEF_DEF_  "GenSigTimeoutMsg_HU_B" 500;
BA_DEF_DEF_  "GenSigTimeoutMsg_HU_A" 500;
BA_DEF_DEF_  "GenSigStartValue" 0;
BA_DEF_DEF_  "GenSigSendType" "Cyclic";
BA_DEF_DEF_  "GenSigInactiveValue" 0;
BA_DEF_DEF_  "GenSigEnvVarType" "undef";
BA_DEF_DEF_  "GenSigCycleTimeActive" 0;
BA_DEF_DEF_  "GenSigCycleTime" 0;
BA_DEF_DEF_  "GenSigTimeoutMsg_HU_High_X445" 500;
BA_DEF_DEF_  "GenSigTimeoutMsg_HU_Mid_X445" 500;
BA_DEF_DEF_  "GenSigTimeoutTime_HU_High_X445" 500;
BA_DEF_DEF_  "GenSigTimeoutTime_HU_Mid_X445" 500;
BA_DEF_DEF_  "GenSigTimeoutMsg_IVI" 500;
BA_DEF_DEF_  "GenSigTimeoutTime_IVI" 500;
BA_DEF_DEF_  "NmMessage" "no";
BA_DEF_DEF_  "NmAsrMessage" "<n.a.>";
BA_DEF_DEF_  "MessageTimeout" 500;
BA_DEF_DEF_  "GenMsgStartDelayTime" 0;
BA_DEF_DEF_  "GenMsgSendType" "Cyclic";
BA_DEF_DEF_  "GenMsgNrOfRepetition" 0;
BA_DEF_DEF_  "GenMsgILSupport" "Yes";
BA_DEF_DEF_  "GenMsgDelayTime" 0;
BA_DEF_DEF_  "GenMsgCycleTimeFast" 0;
BA_DEF_DEF_  "GenMsgCycleTime" 0;
BA_DEF_DEF_  "DiagUudtResponse" "false";
BA_DEF_DEF_  "DiagUsdtResponse" "false";
BA_DEF_DEF_  "DiagState" "No";
BA_DEF_DEF_  "DiagResponse" "No";
BA_DEF_DEF_  "DiagRequest" "No";
BA_DEF_DEF_  "MsgType" "Application";
BA_DEF_DEF_  "SystemSignalLongSymbol" "";
BA_ "MessageTimeout" BO_ 454 0;
BA_ "GenMsgSendType" BO_ 454 8;
BA_ "MessageTimeout" BO_ 459 0;
BA_ "GenMsgSendType" BO_ 459 8;
BA_ "MessageTimeout" BO_ 460 0;
BA_ "GenMsgSendType" BO_ 460 8;
BA_ "MessageTimeout" BO_ 462 0;
BA_ "GenMsgSendType" BO_ 462 8;
BA_ "MessageTimeout" BO_ 463 0;
BA_ "GenMsgSendType" BO_ 463 8;
BA_ "MessageTimeout" BO_ 464 0;
BA_ "GenMsgSendType" BO_ 464 8;
BA_ "MessageTimeout" BO_ 466 0;
BA_ "GenMsgSendType" BO_ 466 8;
BA_ "MessageTimeout" BO_ 469 0;
BA_ "GenMsgSendType" BO_ 469 8;
BA_ "MessageTimeout" BO_ 470 0;
BA_ "GenMsgSendType" BO_ 470 8;
BA_ "MessageTimeout" BO_ 472 0;
BA_ "GenMsgSendType" BO_ 472 8;
BA_ "MessageTimeout" BO_ 474 0;
BA_ "GenMsgSendType" BO_ 474 8;
BA_ "MessageTimeout" BO_ 475 0;
BA_ "GenMsgSendType" BO_ 475 8;
BA_ "MessageTimeout" BO_ 476 0;
BA_ "GenMsgSendType" BO_ 476 8;
BA_ "MessageTimeout" BO_ 477 0;
BA_ "GenMsgSendType" BO_ 477 8;
BA_ "MessageTimeout" BO_ 478 0;
BA_ "GenMsgSendType" BO_ 478 8;
BA_ "MessageTimeout" BO_ 479 0;
BA_ "GenMsgSendType" BO_ 479 8;
BA_ "MessageTimeout" BO_ 490 0;
BA_ "GenMsgSendType" BO_ 490 8;
BA_ "GenMsgNrOfRepetition" BO_ 490 1;
BA_ "MessageTimeout" BO_ 497 0;
BA_ "GenMsgSendType" BO_ 497 8;
BA_ "GenSigTimeoutTime_HU_Mid_X451" SG_ 454 IcHuTempUnitSet 0;
BA_ "GenSigTimeoutTime_HU_High_X451" SG_ 454 IcHuTempUnitSet 0;
BA_ "GenSigTimeoutTime_HU_B" SG_ 454 IcHuTempUnitSet 0;
BA_ "GenSigTimeoutTime_HU_A" SG_ 454 IcHuTempUnitSet 0;
BA_ "GenSigTimeoutMsg_HU_Mid_X451" SG_ 454 IcHuTempUnitSet 0;
BA_ "GenSigTimeoutMsg_HU_High_X451" SG_ 454 IcHuTempUnitSet 0;
BA_ "GenSigTimeoutMsg_HU_B" SG_ 454 IcHuTempUnitSet 0;
BA_ "GenSigTimeoutMsg_HU_A" SG_ 454 IcHuTempUnitSet 0;
BA_ "GenSigSendType" SG_ 454 IcHuTempUnitSet 1;
BA_ "GenSigTimeoutMsg_HU_High_X445" SG_ 454 IcHuTempUnitSet 0;
BA_ "GenSigTimeoutMsg_HU_Mid_X445" SG_ 454 IcHuTempUnitSet 0;
BA_ "GenSigTimeoutTime_HU_High_X445" SG_ 454 IcHuTempUnitSet 0;
BA_ "GenSigTimeoutTime_HU_Mid_X445" SG_ 454 IcHuTempUnitSet 0;
BA_ "GenSigTimeoutMsg_IVI" SG_ 454 IcHuTempUnitSet 0;
BA_ "GenSigTimeoutTime_IVI" SG_ 454 IcHuTempUnitSet 0;
BA_ "GenSigTimeoutTime_HU_Mid_X451" SG_ 454 IcHuDistUnitSet 0;
BA_ "GenSigTimeoutTime_HU_High_X451" SG_ 454 IcHuDistUnitSet 0;
BA_ "GenSigTimeoutTime_HU_B" SG_ 454 IcHuDistUnitSet 0;
BA_ "GenSigTimeoutTime_HU_A" SG_ 454 IcHuDistUnitSet 0;
BA_ "GenSigTimeoutMsg_HU_Mid_X451" SG_ 454 IcHuDistUnitSet 0;
BA_ "GenSigTimeoutMsg_HU_High_X451" SG_ 454 IcHuDistUnitSet 0;
BA_ "GenSigTimeoutMsg_HU_B" SG_ 454 IcHuDistUnitSet 0;
BA_ "GenSigTimeoutMsg_HU_A" SG_ 454 IcHuDistUnitSet 0;
BA_ "GenSigSendType" SG_ 454 IcHuDistUnitSet 1;
BA_ "GenSigTimeoutMsg_HU_High_X445" SG_ 454 IcHuDistUnitSet 0;
BA_ "GenSigTimeoutMsg_HU_Mid_X445" SG_ 454 IcHuDistUnitSet 0;
BA_ "GenSigTimeoutTime_HU_High_X445" SG_ 454 IcHuDistUnitSet 0;
BA_ "GenSigTimeoutTime_HU_Mid_X445" SG_ 454 IcHuDistUnitSet 0;
BA_ "GenSigTimeoutMsg_IVI" SG_ 454 IcHuDistUnitSet 0;
BA_ "GenSigTimeoutTime_IVI" SG_ 454 IcHuDistUnitSet 0;
BA_ "GenSigTimeoutTime_HU_Mid_X451" SG_ 454 IcHuSecondsInfo 0;
BA_ "GenSigTimeoutTime_HU_High_X451" SG_ 454 IcHuSecondsInfo 0;
BA_ "GenSigTimeoutTime_HU_B" SG_ 454 IcHuSecondsInfo 0;
BA_ "GenSigTimeoutTime_HU_A" SG_ 454 IcHuSecondsInfo 0;
BA_ "GenSigTimeoutMsg_HU_Mid_X451" SG_ 454 IcHuSecondsInfo 0;
BA_ "GenSigTimeoutMsg_HU_High_X451" SG_ 454 IcHuSecondsInfo 0;
BA_ "GenSigTimeoutMsg_HU_B" SG_ 454 IcHuSecondsInfo 0;
BA_ "GenSigTimeoutMsg_HU_A" SG_ 454 IcHuSecondsInfo 0;
BA_ "GenSigSendType" SG_ 454 IcHuSecondsInfo 1;
BA_ "GenSigTimeoutMsg_HU_High_X445" SG_ 454 IcHuSecondsInfo 0;
BA_ "GenSigTimeoutMsg_HU_Mid_X445" SG_ 454 IcHuSecondsInfo 0;
BA_ "GenSigTimeoutTime_HU_High_X445" SG_ 454 IcHuSecondsInfo 0;
BA_ "GenSigTimeoutTime_HU_Mid_X445" SG_ 454 IcHuSecondsInfo 0;
BA_ "GenSigTimeoutMsg_IVI" SG_ 454 IcHuSecondsInfo 0;
BA_ "GenSigTimeoutTime_IVI" SG_ 454 IcHuSecondsInfo 0;
BA_ "GenSigTimeoutTime_HU_Mid_X451" SG_ 454 IcHuMinuteInfo 0;
BA_ "GenSigTimeoutTime_HU_High_X451" SG_ 454 IcHuMinuteInfo 0;
BA_ "GenSigTimeoutTime_HU_B" SG_ 454 IcHuMinuteInfo 0;
BA_ "GenSigTimeoutTime_HU_A" SG_ 454 IcHuMinuteInfo 0;
BA_ "GenSigTimeoutMsg_HU_Mid_X451" SG_ 454 IcHuMinuteInfo 0;
BA_ "GenSigTimeoutMsg_HU_High_X451" SG_ 454 IcHuMinuteInfo 0;
BA_ "GenSigTimeoutMsg_HU_B" SG_ 454 IcHuMinuteInfo 0;
BA_ "GenSigTimeoutMsg_HU_A" SG_ 454 IcHuMinuteInfo 0;
BA_ "GenSigSendType" SG_ 454 IcHuMinuteInfo 1;
BA_ "GenSigTimeoutMsg_HU_High_X445" SG_ 454 IcHuMinuteInfo 0;
BA_ "GenSigTimeoutMsg_HU_Mid_X445" SG_ 454 IcHuMinuteInfo 0;
BA_ "GenSigTimeoutTime_HU_High_X445" SG_ 454 IcHuMinuteInfo 0;
BA_ "GenSigTimeoutTime_HU_Mid_X445" SG_ 454 IcHuMinuteInfo 0;
BA_ "GenSigTimeoutMsg_IVI" SG_ 454 IcHuMinuteInfo 0;
BA_ "GenSigTimeoutTime_IVI" SG_ 454 IcHuMinuteInfo 0;
BA_ "GenSigTimeoutTime_HU_Mid_X451" SG_ 454 IcHuClockMode 0;
BA_ "GenSigTimeoutTime_HU_High_X451" SG_ 454 IcHuClockMode 0;
BA_ "GenSigTimeoutTime_HU_B" SG_ 454 IcHuClockMode 0;
BA_ "GenSigTimeoutTime_HU_A" SG_ 454 IcHuClockMode 0;
BA_ "GenSigTimeoutMsg_HU_Mid_X451" SG_ 454 IcHuClockMode 0;
BA_ "GenSigTimeoutMsg_HU_High_X451" SG_ 454 IcHuClockMode 0;
BA_ "GenSigTimeoutMsg_HU_B" SG_ 454 IcHuClockMode 0;
BA_ "GenSigTimeoutMsg_HU_A" SG_ 454 IcHuClockMode 0;
BA_ "GenSigSendType" SG_ 454 IcHuClockMode 1;
BA_ "GenSigTimeoutMsg_HU_High_X445" SG_ 454 IcHuClockMode 0;
BA_ "GenSigTimeoutMsg_HU_Mid_X445" SG_ 454 IcHuClockMode 0;
BA_ "GenSigTimeoutTime_HU_High_X445" SG_ 454 IcHuClockMode 0;
BA_ "GenSigTimeoutTime_HU_Mid_X445" SG_ 454 IcHuClockMode 0;
BA_ "GenSigTimeoutMsg_IVI" SG_ 454 IcHuClockMode 0;
BA_ "GenSigTimeoutTime_IVI" SG_ 454 IcHuClockMode 0;
BA_ "GenSigTimeoutTime_HU_Mid_X451" SG_ 454 IcHuHourInfo 0;
BA_ "GenSigTimeoutTime_HU_High_X451" SG_ 454 IcHuHourInfo 0;
BA_ "GenSigTimeoutTime_HU_B" SG_ 454 IcHuHourInfo 0;
BA_ "GenSigTimeoutTime_HU_A" SG_ 454 IcHuHourInfo 0;
BA_ "GenSigTimeoutMsg_HU_Mid_X451" SG_ 454 IcHuHourInfo 0;
BA_ "GenSigTimeoutMsg_HU_High_X451" SG_ 454 IcHuHourInfo 0;
BA_ "GenSigTimeoutMsg_HU_B" SG_ 454 IcHuHourInfo 0;
BA_ "GenSigTimeoutMsg_HU_A" SG_ 454 IcHuHourInfo 0;
BA_ "GenSigSendType" SG_ 454 IcHuHourInfo 1;
BA_ "GenSigTimeoutMsg_HU_High_X445" SG_ 454 IcHuHourInfo 0;
BA_ "GenSigTimeoutMsg_HU_Mid_X445" SG_ 454 IcHuHourInfo 0;
BA_ "GenSigTimeoutTime_HU_High_X445" SG_ 454 IcHuHourInfo 0;
BA_ "GenSigTimeoutTime_HU_Mid_X445" SG_ 454 IcHuHourInfo 0;
BA_ "GenSigTimeoutMsg_IVI" SG_ 454 IcHuHourInfo 0;
BA_ "GenSigTimeoutTime_IVI" SG_ 454 IcHuHourInfo 0;
BA_ "GenSigTimeoutTime_HU_Mid_X451" SG_ 454 IcHuDateInfo 0;
BA_ "GenSigTimeoutTime_HU_High_X451" SG_ 454 IcHuDateInfo 0;
BA_ "GenSigTimeoutTime_HU_B" SG_ 454 IcHuDateInfo 0;
BA_ "GenSigTimeoutTime_HU_A" SG_ 454 IcHuDateInfo 0;
BA_ "GenSigTimeoutMsg_HU_Mid_X451" SG_ 454 IcHuDateInfo 0;
BA_ "GenSigTimeoutMsg_HU_High_X451" SG_ 454 IcHuDateInfo 0;
BA_ "GenSigTimeoutMsg_HU_B" SG_ 454 IcHuDateInfo 0;
BA_ "GenSigTimeoutMsg_HU_A" SG_ 454 IcHuDateInfo 0;
BA_ "GenSigSendType" SG_ 454 IcHuDateInfo 1;
BA_ "GenSigTimeoutMsg_HU_High_X445" SG_ 454 IcHuDateInfo 0;
BA_ "GenSigTimeoutMsg_HU_Mid_X445" SG_ 454 IcHuDateInfo 0;
BA_ "GenSigTimeoutTime_HU_High_X445" SG_ 454 IcHuDateInfo 0;
BA_ "GenSigTimeoutTime_HU_Mid_X445" SG_ 454 IcHuDateInfo 0;
BA_ "GenSigTimeoutMsg_IVI" SG_ 454 IcHuDateInfo 0;
BA_ "GenSigTimeoutTime_IVI" SG_ 454 IcHuDateInfo 0;
BA_ "GenSigTimeoutTime_HU_Mid_X451" SG_ 454 IcHuYearInfo 0;
BA_ "GenSigTimeoutTime_HU_High_X451" SG_ 454 IcHuYearInfo 0;
BA_ "GenSigTimeoutTime_HU_B" SG_ 454 IcHuYearInfo 0;
BA_ "GenSigTimeoutTime_HU_A" SG_ 454 IcHuYearInfo 0;
BA_ "GenSigTimeoutMsg_HU_Mid_X451" SG_ 454 IcHuYearInfo 0;
BA_ "GenSigTimeoutMsg_HU_High_X451" SG_ 454 IcHuYearInfo 0;
BA_ "GenSigTimeoutMsg_HU_B" SG_ 454 IcHuYearInfo 0;
BA_ "GenSigTimeoutMsg_HU_A" SG_ 454 IcHuYearInfo 0;
BA_ "GenSigSendType" SG_ 454 IcHuYearInfo 1;
BA_ "GenSigTimeoutMsg_HU_High_X445" SG_ 454 IcHuYearInfo 0;
BA_ "GenSigTimeoutMsg_HU_Mid_X445" SG_ 454 IcHuYearInfo 0;
BA_ "GenSigTimeoutTime_HU_High_X445" SG_ 454 IcHuYearInfo 0;
BA_ "GenSigTimeoutTime_HU_Mid_X445" SG_ 454 IcHuYearInfo 0;
BA_ "GenSigTimeoutMsg_IVI" SG_ 454 IcHuYearInfo 0;
BA_ "GenSigTimeoutTime_IVI" SG_ 454 IcHuYearInfo 0;
BA_ "GenSigTimeoutTime_HU_Mid_X451" SG_ 454 IcHuMonthInfo 0;
BA_ "GenSigTimeoutTime_HU_High_X451" SG_ 454 IcHuMonthInfo 0;
BA_ "GenSigTimeoutTime_HU_B" SG_ 454 IcHuMonthInfo 0;
BA_ "GenSigTimeoutTime_HU_A" SG_ 454 IcHuMonthInfo 0;
BA_ "GenSigTimeoutMsg_HU_Mid_X451" SG_ 454 IcHuMonthInfo 0;
BA_ "GenSigTimeoutMsg_HU_High_X451" SG_ 454 IcHuMonthInfo 0;
BA_ "GenSigTimeoutMsg_HU_B" SG_ 454 IcHuMonthInfo 0;
BA_ "GenSigTimeoutMsg_HU_A" SG_ 454 IcHuMonthInfo 0;
BA_ "GenSigSendType" SG_ 454 IcHuMonthInfo 1;
BA_ "GenSigTimeoutMsg_HU_High_X445" SG_ 454 IcHuMonthInfo 0;
BA_ "GenSigTimeoutMsg_HU_Mid_X445" SG_ 454 IcHuMonthInfo 0;
BA_ "GenSigTimeoutTime_HU_High_X445" SG_ 454 IcHuMonthInfo 0;
BA_ "GenSigTimeoutTime_HU_Mid_X445" SG_ 454 IcHuMonthInfo 0;
BA_ "GenSigTimeoutMsg_IVI" SG_ 454 IcHuMonthInfo 0;
BA_ "GenSigTimeoutTime_IVI" SG_ 454 IcHuMonthInfo 0;
BA_ "GenSigTimeoutTime_HU_Mid_X451" SG_ 454 IcHuMillisecondsInfo 0;
BA_ "GenSigTimeoutTime_HU_High_X451" SG_ 454 IcHuMillisecondsInfo 0;
BA_ "GenSigTimeoutTime_HU_B" SG_ 454 IcHuMillisecondsInfo 0;
BA_ "GenSigTimeoutTime_HU_A" SG_ 454 IcHuMillisecondsInfo 0;
BA_ "GenSigTimeoutMsg_HU_Mid_X451" SG_ 454 IcHuMillisecondsInfo 0;
BA_ "GenSigTimeoutMsg_HU_High_X451" SG_ 454 IcHuMillisecondsInfo 0;
BA_ "GenSigTimeoutMsg_HU_B" SG_ 454 IcHuMillisecondsInfo 0;
BA_ "GenSigTimeoutMsg_HU_A" SG_ 454 IcHuMillisecondsInfo 0;
BA_ "GenSigSendType" SG_ 454 IcHuMillisecondsInfo 1;
BA_ "GenSigTimeoutMsg_HU_High_X445" SG_ 454 IcHuMillisecondsInfo 0;
BA_ "GenSigTimeoutMsg_HU_Mid_X445" SG_ 454 IcHuMillisecondsInfo 0;
BA_ "GenSigTimeoutTime_HU_High_X445" SG_ 454 IcHuMillisecondsInfo 0;
BA_ "GenSigTimeoutTime_HU_Mid_X445" SG_ 454 IcHuMillisecondsInfo 0;
BA_ "GenSigTimeoutMsg_IVI" SG_ 454 IcHuMillisecondsInfo 0;
BA_ "GenSigTimeoutTime_IVI" SG_ 454 IcHuMillisecondsInfo 0;
BA_ "GenSigTimeoutTime_HU_Mid_X451" SG_ 454 IcLangSettings 0;
BA_ "GenSigTimeoutTime_HU_High_X451" SG_ 454 IcLangSettings 0;
BA_ "GenSigTimeoutTime_HU_B" SG_ 454 IcLangSettings 0;
BA_ "GenSigTimeoutTime_HU_A" SG_ 454 IcLangSettings 0;
BA_ "GenSigTimeoutMsg_HU_Mid_X451" SG_ 454 IcLangSettings 0;
BA_ "GenSigTimeoutMsg_HU_High_X451" SG_ 454 IcLangSettings 0;
BA_ "GenSigTimeoutMsg_HU_B" SG_ 454 IcLangSettings 0;
BA_ "GenSigTimeoutMsg_HU_A" SG_ 454 IcLangSettings 0;
BA_ "GenSigSendType" SG_ 454 IcLangSettings 1;
BA_ "GenSigTimeoutMsg_HU_High_X445" SG_ 454 IcLangSettings 0;
BA_ "GenSigTimeoutMsg_HU_Mid_X445" SG_ 454 IcLangSettings 0;
BA_ "GenSigTimeoutTime_HU_High_X445" SG_ 454 IcLangSettings 0;
BA_ "GenSigTimeoutTime_HU_Mid_X445" SG_ 454 IcLangSettings 0;
BA_ "GenSigTimeoutMsg_IVI" SG_ 454 IcLangSettings 0;
BA_ "GenSigTimeoutTime_IVI" SG_ 454 IcLangSettings 0;
BA_ "GenSigTimeoutTime_HU_Mid_X451" SG_ 459 BCmAntitheftFeatureState 0;
BA_ "GenSigTimeoutTime_HU_High_X451" SG_ 459 BCmAntitheftFeatureState 0;
BA_ "GenSigTimeoutTime_HU_B" SG_ 459 BCmAntitheftFeatureState 0;
BA_ "GenSigTimeoutTime_HU_A" SG_ 459 BCmAntitheftFeatureState 0;
BA_ "GenSigTimeoutMsg_HU_Mid_X451" SG_ 459 BCmAntitheftFeatureState 0;
BA_ "GenSigTimeoutMsg_HU_High_X451" SG_ 459 BCmAntitheftFeatureState 0;
BA_ "GenSigTimeoutMsg_HU_B" SG_ 459 BCmAntitheftFeatureState 0;
BA_ "GenSigTimeoutMsg_HU_A" SG_ 459 BCmAntitheftFeatureState 0;
BA_ "GenSigStartValue" SG_ 459 BCmAntitheftFeatureState 1;
BA_ "GenSigSendType" SG_ 459 BCmAntitheftFeatureState 1;
BA_ "GenSigTimeoutMsg_HU_High_X445" SG_ 459 BCmAntitheftFeatureState 0;
BA_ "GenSigTimeoutMsg_HU_Mid_X445" SG_ 459 BCmAntitheftFeatureState 0;
BA_ "GenSigTimeoutTime_HU_High_X445" SG_ 459 BCmAntitheftFeatureState 0;
BA_ "GenSigTimeoutTime_HU_Mid_X445" SG_ 459 BCmAntitheftFeatureState 0;
BA_ "GenSigTimeoutMsg_IVI" SG_ 459 BCmAntitheftFeatureState 0;
BA_ "GenSigTimeoutTime_IVI" SG_ 459 BCmAntitheftFeatureState 0;
BA_ "GenSigTimeoutTime_HU_Mid_X451" SG_ 459 BCmAntitheftKeyConfirmation 0;
BA_ "GenSigTimeoutTime_HU_High_X451" SG_ 459 BCmAntitheftKeyConfirmation 0;
BA_ "GenSigTimeoutTime_HU_B" SG_ 459 BCmAntitheftKeyConfirmation 0;
BA_ "GenSigTimeoutTime_HU_A" SG_ 459 BCmAntitheftKeyConfirmation 0;
BA_ "GenSigTimeoutMsg_HU_Mid_X451" SG_ 459 BCmAntitheftKeyConfirmation 0;
BA_ "GenSigTimeoutMsg_HU_High_X451" SG_ 459 BCmAntitheftKeyConfirmation 0;
BA_ "GenSigTimeoutMsg_HU_B" SG_ 459 BCmAntitheftKeyConfirmation 0;
BA_ "GenSigTimeoutMsg_HU_A" SG_ 459 BCmAntitheftKeyConfirmation 0;
BA_ "GenSigSendType" SG_ 459 BCmAntitheftKeyConfirmation 1;
BA_ "GenSigTimeoutMsg_HU_High_X445" SG_ 459 BCmAntitheftKeyConfirmation 0;
BA_ "GenSigTimeoutMsg_HU_Mid_X445" SG_ 459 BCmAntitheftKeyConfirmation 0;
BA_ "GenSigTimeoutTime_HU_High_X445" SG_ 459 BCmAntitheftKeyConfirmation 0;
BA_ "GenSigTimeoutTime_HU_Mid_X445" SG_ 459 BCmAntitheftKeyConfirmation 0;
BA_ "GenSigTimeoutMsg_IVI" SG_ 459 BCmAntitheftKeyConfirmation 0;
BA_ "GenSigTimeoutTime_IVI" SG_ 459 BCmAntitheftKeyConfirmation 0;
BA_ "GenSigTimeoutTime_HU_Mid_X451" SG_ 459 BcmHuCkdState 0;
BA_ "GenSigTimeoutTime_HU_High_X451" SG_ 459 BcmHuCkdState 0;
BA_ "GenSigTimeoutTime_HU_B" SG_ 459 BcmHuCkdState 0;
BA_ "GenSigTimeoutTime_HU_A" SG_ 459 BcmHuCkdState 0;
BA_ "GenSigTimeoutMsg_HU_Mid_X451" SG_ 459 BcmHuCkdState 0;
BA_ "GenSigTimeoutMsg_HU_High_X451" SG_ 459 BcmHuCkdState 0;
BA_ "GenSigTimeoutMsg_HU_B" SG_ 459 BcmHuCkdState 0;
BA_ "GenSigTimeoutMsg_HU_A" SG_ 459 BcmHuCkdState 0;
BA_ "GenSigSendType" SG_ 459 BcmHuCkdState 1;
BA_ "GenSigTimeoutMsg_HU_High_X445" SG_ 459 BcmHuCkdState 0;
BA_ "GenSigTimeoutMsg_HU_Mid_X445" SG_ 459 BcmHuCkdState 0;
BA_ "GenSigTimeoutTime_HU_High_X445" SG_ 459 BcmHuCkdState 0;
BA_ "GenSigTimeoutTime_HU_Mid_X445" SG_ 459 BcmHuCkdState 0;
BA_ "GenSigTimeoutMsg_IVI" SG_ 459 BcmHuCkdState 0;
BA_ "GenSigTimeoutTime_IVI" SG_ 459 BcmHuCkdState 0;
BA_ "GenSigTimeoutTime_HU_Mid_X451" SG_ 460 HuAntitheftFeatureState 0;
BA_ "GenSigTimeoutTime_HU_High_X451" SG_ 460 HuAntitheftFeatureState 0;
BA_ "GenSigTimeoutTime_HU_B" SG_ 460 HuAntitheftFeatureState 0;
BA_ "GenSigTimeoutTime_HU_A" SG_ 460 HuAntitheftFeatureState 0;
BA_ "GenSigTimeoutMsg_HU_Mid_X451" SG_ 460 HuAntitheftFeatureState 0;
BA_ "GenSigTimeoutMsg_HU_High_X451" SG_ 460 HuAntitheftFeatureState 0;
BA_ "GenSigTimeoutMsg_HU_B" SG_ 460 HuAntitheftFeatureState 0;
BA_ "GenSigTimeoutMsg_HU_A" SG_ 460 HuAntitheftFeatureState 0;
BA_ "GenSigStartValue" SG_ 460 HuAntitheftFeatureState 1;
BA_ "GenSigSendType" SG_ 460 HuAntitheftFeatureState 1;
BA_ "GenSigTimeoutMsg_HU_High_X445" SG_ 460 HuAntitheftFeatureState 0;
BA_ "GenSigTimeoutMsg_HU_Mid_X445" SG_ 460 HuAntitheftFeatureState 0;
BA_ "GenSigTimeoutTime_HU_High_X445" SG_ 460 HuAntitheftFeatureState 0;
BA_ "GenSigTimeoutTime_HU_Mid_X445" SG_ 460 HuAntitheftFeatureState 0;
BA_ "GenSigTimeoutMsg_IVI" SG_ 460 HuAntitheftFeatureState 0;
BA_ "GenSigTimeoutTime_IVI" SG_ 460 HuAntitheftFeatureState 0;
BA_ "GenSigTimeoutTime_HU_Mid_X451" SG_ 460 HuBcmQueryInfo 0;
BA_ "GenSigTimeoutTime_HU_High_X451" SG_ 460 HuBcmQueryInfo 0;
BA_ "GenSigTimeoutTime_HU_B" SG_ 460 HuBcmQueryInfo 0;
BA_ "GenSigTimeoutTime_HU_A" SG_ 460 HuBcmQueryInfo 0;
BA_ "GenSigTimeoutMsg_HU_Mid_X451" SG_ 460 HuBcmQueryInfo 0;
BA_ "GenSigTimeoutMsg_HU_High_X451" SG_ 460 HuBcmQueryInfo 0;
BA_ "GenSigTimeoutMsg_HU_B" SG_ 460 HuBcmQueryInfo 0;
BA_ "GenSigTimeoutMsg_HU_A" SG_ 460 HuBcmQueryInfo 0;
BA_ "GenSigSendType" SG_ 460 HuBcmQueryInfo 1;
BA_ "GenSigTimeoutMsg_HU_High_X445" SG_ 460 HuBcmQueryInfo 0;
BA_ "GenSigTimeoutMsg_HU_Mid_X445" SG_ 460 HuBcmQueryInfo 0;
BA_ "GenSigTimeoutTime_HU_High_X445" SG_ 460 HuBcmQueryInfo 0;
BA_ "GenSigTimeoutTime_HU_Mid_X445" SG_ 460 HuBcmQueryInfo 0;
BA_ "GenSigTimeoutMsg_IVI" SG_ 460 HuBcmQueryInfo 0;
BA_ "GenSigTimeoutTime_IVI" SG_ 460 HuBcmQueryInfo 0;
BA_ "GenSigTimeoutTime_HU_Mid_X451" SG_ 462 BCmAntitheftSeed 0;
BA_ "GenSigTimeoutTime_HU_High_X451" SG_ 462 BCmAntitheftSeed 0;
BA_ "GenSigTimeoutTime_HU_B" SG_ 462 BCmAntitheftSeed 0;
BA_ "GenSigTimeoutTime_HU_A" SG_ 462 BCmAntitheftSeed 0;
BA_ "GenSigTimeoutMsg_HU_Mid_X451" SG_ 462 BCmAntitheftSeed 0;
BA_ "GenSigTimeoutMsg_HU_High_X451" SG_ 462 BCmAntitheftSeed 0;
BA_ "GenSigTimeoutMsg_HU_B" SG_ 462 BCmAntitheftSeed 0;
BA_ "GenSigTimeoutMsg_HU_A" SG_ 462 BCmAntitheftSeed 0;
BA_ "GenSigSendType" SG_ 462 BCmAntitheftSeed 1;
BA_ "GenSigTimeoutMsg_HU_High_X445" SG_ 462 BCmAntitheftSeed 0;
BA_ "GenSigTimeoutMsg_HU_Mid_X445" SG_ 462 BCmAntitheftSeed 0;
BA_ "GenSigTimeoutTime_HU_High_X445" SG_ 462 BCmAntitheftSeed 0;
BA_ "GenSigTimeoutTime_HU_Mid_X445" SG_ 462 BCmAntitheftSeed 0;
BA_ "GenSigTimeoutMsg_IVI" SG_ 462 BCmAntitheftSeed 0;
BA_ "GenSigTimeoutTime_IVI" SG_ 462 BCmAntitheftSeed 0;
BA_ "GenSigTimeoutTime_HU_Mid_X451" SG_ 463 BCmAntitheftKey 0;
BA_ "GenSigTimeoutTime_HU_High_X451" SG_ 463 BCmAntitheftKey 0;
BA_ "GenSigTimeoutTime_HU_B" SG_ 463 BCmAntitheftKey 0;
BA_ "GenSigTimeoutTime_HU_A" SG_ 463 BCmAntitheftKey 0;
BA_ "GenSigTimeoutMsg_HU_Mid_X451" SG_ 463 BCmAntitheftKey 0;
BA_ "GenSigTimeoutMsg_HU_High_X451" SG_ 463 BCmAntitheftKey 0;
BA_ "GenSigTimeoutMsg_HU_B" SG_ 463 BCmAntitheftKey 0;
BA_ "GenSigTimeoutMsg_HU_A" SG_ 463 BCmAntitheftKey 0;
BA_ "GenSigSendType" SG_ 463 BCmAntitheftKey 1;
BA_ "GenSigTimeoutMsg_HU_High_X445" SG_ 463 BCmAntitheftKey 0;
BA_ "GenSigTimeoutMsg_HU_Mid_X445" SG_ 463 BCmAntitheftKey 0;
BA_ "GenSigTimeoutTime_HU_High_X445" SG_ 463 BCmAntitheftKey 0;
BA_ "GenSigTimeoutTime_HU_Mid_X445" SG_ 463 BCmAntitheftKey 0;
BA_ "GenSigTimeoutMsg_IVI" SG_ 463 BCmAntitheftKey 0;
BA_ "GenSigTimeoutTime_IVI" SG_ 463 BCmAntitheftKey 0;
BA_ "GenSigTimeoutTime_HU_Mid_X451" SG_ 464 HuIcDriveproConfig 0;
BA_ "GenSigTimeoutTime_HU_High_X451" SG_ 464 HuIcDriveproConfig 0;
BA_ "GenSigTimeoutTime_HU_B" SG_ 464 HuIcDriveproConfig 0;
BA_ "GenSigTimeoutTime_HU_A" SG_ 464 HuIcDriveproConfig 0;
BA_ "GenSigTimeoutMsg_HU_Mid_X451" SG_ 464 HuIcDriveproConfig 0;
BA_ "GenSigTimeoutMsg_HU_High_X451" SG_ 464 HuIcDriveproConfig 0;
BA_ "GenSigTimeoutMsg_HU_B" SG_ 464 HuIcDriveproConfig 0;
BA_ "GenSigTimeoutMsg_HU_A" SG_ 464 HuIcDriveproConfig 0;
BA_ "GenSigSendType" SG_ 464 HuIcDriveproConfig 1;
BA_ "GenSigTimeoutMsg_HU_High_X445" SG_ 464 HuIcDriveproConfig 0;
BA_ "GenSigTimeoutMsg_HU_Mid_X445" SG_ 464 HuIcDriveproConfig 0;
BA_ "GenSigTimeoutTime_HU_High_X445" SG_ 464 HuIcDriveproConfig 0;
BA_ "GenSigTimeoutTime_HU_Mid_X445" SG_ 464 HuIcDriveproConfig 0;
BA_ "GenSigTimeoutMsg_IVI" SG_ 464 HuIcDriveproConfig 0;
BA_ "GenSigTimeoutTime_IVI" SG_ 464 HuIcDriveproConfig 0;
BA_ "GenSigTimeoutTime_HU_Mid_X451" SG_ 464 HuIcDriveProConfigEventStatus 0;
BA_ "GenSigTimeoutTime_HU_High_X451" SG_ 464 HuIcDriveProConfigEventStatus 0;
BA_ "GenSigTimeoutTime_HU_B" SG_ 464 HuIcDriveProConfigEventStatus 0;
BA_ "GenSigTimeoutTime_HU_A" SG_ 464 HuIcDriveProConfigEventStatus 0;
BA_ "GenSigTimeoutMsg_HU_Mid_X451" SG_ 464 HuIcDriveProConfigEventStatus 0;
BA_ "GenSigTimeoutMsg_HU_High_X451" SG_ 464 HuIcDriveProConfigEventStatus 0;
BA_ "GenSigTimeoutMsg_HU_B" SG_ 464 HuIcDriveProConfigEventStatus 0;
BA_ "GenSigTimeoutMsg_HU_A" SG_ 464 HuIcDriveProConfigEventStatus 0;
BA_ "GenSigSendType" SG_ 464 HuIcDriveProConfigEventStatus 1;
BA_ "GenSigTimeoutMsg_HU_High_X445" SG_ 464 HuIcDriveProConfigEventStatus 0;
BA_ "GenSigTimeoutMsg_HU_Mid_X445" SG_ 464 HuIcDriveProConfigEventStatus 0;
BA_ "GenSigTimeoutTime_HU_High_X445" SG_ 464 HuIcDriveProConfigEventStatus 0;
BA_ "GenSigTimeoutTime_HU_Mid_X445" SG_ 464 HuIcDriveProConfigEventStatus 0;
BA_ "GenSigTimeoutMsg_IVI" SG_ 464 HuIcDriveProConfigEventStatus 0;
BA_ "GenSigTimeoutTime_IVI" SG_ 464 HuIcDriveProConfigEventStatus 0;
BA_ "GenSigTimeoutTime_HU_Mid_X451" SG_ 464 HuIcTripAReset 0;
BA_ "GenSigTimeoutTime_HU_High_X451" SG_ 464 HuIcTripAReset 0;
BA_ "GenSigTimeoutTime_HU_B" SG_ 464 HuIcTripAReset 0;
BA_ "GenSigTimeoutTime_HU_A" SG_ 464 HuIcTripAReset 0;
BA_ "GenSigTimeoutMsg_HU_Mid_X451" SG_ 464 HuIcTripAReset 0;
BA_ "GenSigTimeoutMsg_HU_High_X451" SG_ 464 HuIcTripAReset 0;
BA_ "GenSigTimeoutMsg_HU_B" SG_ 464 HuIcTripAReset 0;
BA_ "GenSigTimeoutMsg_HU_A" SG_ 464 HuIcTripAReset 0;
BA_ "GenSigSendType" SG_ 464 HuIcTripAReset 1;
BA_ "GenSigTimeoutMsg_HU_High_X445" SG_ 464 HuIcTripAReset 0;
BA_ "GenSigTimeoutMsg_HU_Mid_X445" SG_ 464 HuIcTripAReset 0;
BA_ "GenSigTimeoutTime_HU_High_X445" SG_ 464 HuIcTripAReset 0;
BA_ "GenSigTimeoutTime_HU_Mid_X445" SG_ 464 HuIcTripAReset 0;
BA_ "GenSigTimeoutMsg_IVI" SG_ 464 HuIcTripAReset 0;
BA_ "GenSigTimeoutTime_IVI" SG_ 464 HuIcTripAReset 0;
BA_ "GenSigTimeoutTime_HU_Mid_X451" SG_ 464 HuIcTripAResetAck 0;
BA_ "GenSigTimeoutTime_HU_High_X451" SG_ 464 HuIcTripAResetAck 0;
BA_ "GenSigTimeoutTime_HU_B" SG_ 464 HuIcTripAResetAck 0;
BA_ "GenSigTimeoutTime_HU_A" SG_ 464 HuIcTripAResetAck 0;
BA_ "GenSigTimeoutMsg_HU_Mid_X451" SG_ 464 HuIcTripAResetAck 0;
BA_ "GenSigTimeoutMsg_HU_High_X451" SG_ 464 HuIcTripAResetAck 0;
BA_ "GenSigTimeoutMsg_HU_B" SG_ 464 HuIcTripAResetAck 0;
BA_ "GenSigTimeoutMsg_HU_A" SG_ 464 HuIcTripAResetAck 0;
BA_ "GenSigSendType" SG_ 464 HuIcTripAResetAck 1;
BA_ "GenSigTimeoutMsg_HU_High_X445" SG_ 464 HuIcTripAResetAck 0;
BA_ "GenSigTimeoutMsg_HU_Mid_X445" SG_ 464 HuIcTripAResetAck 0;
BA_ "GenSigTimeoutTime_HU_High_X445" SG_ 464 HuIcTripAResetAck 0;
BA_ "GenSigTimeoutTime_HU_Mid_X445" SG_ 464 HuIcTripAResetAck 0;
BA_ "GenSigTimeoutMsg_IVI" SG_ 464 HuIcTripAResetAck 0;
BA_ "GenSigTimeoutTime_IVI" SG_ 464 HuIcTripAResetAck 0;
BA_ "GenSigTimeoutTime_HU_Mid_X451" SG_ 464 HuIcTripBReset 0;
BA_ "GenSigTimeoutTime_HU_High_X451" SG_ 464 HuIcTripBReset 0;
BA_ "GenSigTimeoutTime_HU_B" SG_ 464 HuIcTripBReset 0;
BA_ "GenSigTimeoutTime_HU_A" SG_ 464 HuIcTripBReset 0;
BA_ "GenSigTimeoutMsg_HU_Mid_X451" SG_ 464 HuIcTripBReset 0;
BA_ "GenSigTimeoutMsg_HU_High_X451" SG_ 464 HuIcTripBReset 0;
BA_ "GenSigTimeoutMsg_HU_B" SG_ 464 HuIcTripBReset 0;
BA_ "GenSigTimeoutMsg_HU_A" SG_ 464 HuIcTripBReset 0;
BA_ "GenSigSendType" SG_ 464 HuIcTripBReset 1;
BA_ "GenSigTimeoutMsg_HU_High_X445" SG_ 464 HuIcTripBReset 0;
BA_ "GenSigTimeoutMsg_HU_Mid_X445" SG_ 464 HuIcTripBReset 0;
BA_ "GenSigTimeoutTime_HU_High_X445" SG_ 464 HuIcTripBReset 0;
BA_ "GenSigTimeoutTime_HU_Mid_X445" SG_ 464 HuIcTripBReset 0;
BA_ "GenSigTimeoutMsg_IVI" SG_ 464 HuIcTripBReset 0;
BA_ "GenSigTimeoutTime_IVI" SG_ 464 HuIcTripBReset 0;
BA_ "GenSigTimeoutTime_HU_Mid_X451" SG_ 464 HuIcTripBResetAck 0;
BA_ "GenSigTimeoutTime_HU_High_X451" SG_ 464 HuIcTripBResetAck 0;
BA_ "GenSigTimeoutTime_HU_B" SG_ 464 HuIcTripBResetAck 0;
BA_ "GenSigTimeoutTime_HU_A" SG_ 464 HuIcTripBResetAck 0;
BA_ "GenSigTimeoutMsg_HU_Mid_X451" SG_ 464 HuIcTripBResetAck 0;
BA_ "GenSigTimeoutMsg_HU_High_X451" SG_ 464 HuIcTripBResetAck 0;
BA_ "GenSigTimeoutMsg_HU_B" SG_ 464 HuIcTripBResetAck 0;
BA_ "GenSigTimeoutMsg_HU_A" SG_ 464 HuIcTripBResetAck 0;
BA_ "GenSigSendType" SG_ 464 HuIcTripBResetAck 1;
BA_ "GenSigTimeoutMsg_HU_High_X445" SG_ 464 HuIcTripBResetAck 0;
BA_ "GenSigTimeoutMsg_HU_Mid_X445" SG_ 464 HuIcTripBResetAck 0;
BA_ "GenSigTimeoutTime_HU_High_X445" SG_ 464 HuIcTripBResetAck 0;
BA_ "GenSigTimeoutTime_HU_Mid_X445" SG_ 464 HuIcTripBResetAck 0;
BA_ "GenSigTimeoutMsg_IVI" SG_ 464 HuIcTripBResetAck 0;
BA_ "GenSigTimeoutTime_IVI" SG_ 464 HuIcTripBResetAck 0;
BA_ "GenSigTimeoutTime_HU_Mid_X451" SG_ 464 HuIcResetAll 0;
BA_ "GenSigTimeoutTime_HU_High_X451" SG_ 464 HuIcResetAll 0;
BA_ "GenSigTimeoutTime_HU_B" SG_ 464 HuIcResetAll 0;
BA_ "GenSigTimeoutTime_HU_A" SG_ 464 HuIcResetAll 0;
BA_ "GenSigTimeoutMsg_HU_Mid_X451" SG_ 464 HuIcResetAll 0;
BA_ "GenSigTimeoutMsg_HU_High_X451" SG_ 464 HuIcResetAll 0;
BA_ "GenSigTimeoutMsg_HU_B" SG_ 464 HuIcResetAll 0;
BA_ "GenSigTimeoutMsg_HU_A" SG_ 464 HuIcResetAll 0;
BA_ "GenSigSendType" SG_ 464 HuIcResetAll 1;
BA_ "GenSigTimeoutMsg_HU_High_X445" SG_ 464 HuIcResetAll 0;
BA_ "GenSigTimeoutMsg_HU_Mid_X445" SG_ 464 HuIcResetAll 0;
BA_ "GenSigTimeoutTime_HU_High_X445" SG_ 464 HuIcResetAll 0;
BA_ "GenSigTimeoutTime_HU_Mid_X445" SG_ 464 HuIcResetAll 0;
BA_ "GenSigTimeoutMsg_IVI" SG_ 464 HuIcResetAll 0;
BA_ "GenSigTimeoutTime_IVI" SG_ 464 HuIcResetAll 0;
BA_ "GenSigTimeoutTime_HU_Mid_X451" SG_ 464 HuIcTripResetAckEventStatus 0;
BA_ "GenSigTimeoutTime_HU_High_X451" SG_ 464 HuIcTripResetAckEventStatus 0;
BA_ "GenSigTimeoutTime_HU_B" SG_ 464 HuIcTripResetAckEventStatus 0;
BA_ "GenSigTimeoutTime_HU_A" SG_ 464 HuIcTripResetAckEventStatus 0;
BA_ "GenSigTimeoutMsg_HU_Mid_X451" SG_ 464 HuIcTripResetAckEventStatus 0;
BA_ "GenSigTimeoutMsg_HU_High_X451" SG_ 464 HuIcTripResetAckEventStatus 0;
BA_ "GenSigTimeoutMsg_HU_B" SG_ 464 HuIcTripResetAckEventStatus 0;
BA_ "GenSigTimeoutMsg_HU_A" SG_ 464 HuIcTripResetAckEventStatus 0;
BA_ "GenSigSendType" SG_ 464 HuIcTripResetAckEventStatus 1;
BA_ "GenSigTimeoutMsg_HU_High_X445" SG_ 464 HuIcTripResetAckEventStatus 0;
BA_ "GenSigTimeoutMsg_HU_Mid_X445" SG_ 464 HuIcTripResetAckEventStatus 0;
BA_ "GenSigTimeoutTime_HU_High_X445" SG_ 464 HuIcTripResetAckEventStatus 0;
BA_ "GenSigTimeoutTime_HU_Mid_X445" SG_ 464 HuIcTripResetAckEventStatus 0;
BA_ "GenSigTimeoutMsg_IVI" SG_ 464 HuIcTripResetAckEventStatus 0;
BA_ "GenSigTimeoutTime_IVI" SG_ 464 HuIcTripResetAckEventStatus 0;
BA_ "GenSigTimeoutTime_HU_Mid_X451" SG_ 464 HuIcTripResetEventStatus 0;
BA_ "GenSigTimeoutTime_HU_High_X451" SG_ 464 HuIcTripResetEventStatus 0;
BA_ "GenSigTimeoutTime_HU_B" SG_ 464 HuIcTripResetEventStatus 0;
BA_ "GenSigTimeoutTime_HU_A" SG_ 464 HuIcTripResetEventStatus 0;
BA_ "GenSigTimeoutMsg_HU_Mid_X451" SG_ 464 HuIcTripResetEventStatus 0;
BA_ "GenSigTimeoutMsg_HU_High_X451" SG_ 464 HuIcTripResetEventStatus 0;
BA_ "GenSigTimeoutMsg_HU_B" SG_ 464 HuIcTripResetEventStatus 0;
BA_ "GenSigTimeoutMsg_HU_A" SG_ 464 HuIcTripResetEventStatus 0;
BA_ "GenSigSendType" SG_ 464 HuIcTripResetEventStatus 1;
BA_ "GenSigTimeoutMsg_HU_High_X445" SG_ 464 HuIcTripResetEventStatus 0;
BA_ "GenSigTimeoutMsg_HU_Mid_X445" SG_ 464 HuIcTripResetEventStatus 0;
BA_ "GenSigTimeoutTime_HU_High_X445" SG_ 464 HuIcTripResetEventStatus 0;
BA_ "GenSigTimeoutTime_HU_Mid_X445" SG_ 464 HuIcTripResetEventStatus 0;
BA_ "GenSigTimeoutMsg_IVI" SG_ 464 HuIcTripResetEventStatus 0;
BA_ "GenSigTimeoutTime_IVI" SG_ 464 HuIcTripResetEventStatus 0;
BA_ "GenSigTimeoutTime_HU_Mid_X451" SG_ 464 HuIcOverallTripReset 0;
BA_ "GenSigTimeoutTime_HU_High_X451" SG_ 464 HuIcOverallTripReset 0;
BA_ "GenSigTimeoutTime_HU_B" SG_ 464 HuIcOverallTripReset 0;
BA_ "GenSigTimeoutTime_HU_A" SG_ 464 HuIcOverallTripReset 0;
BA_ "GenSigTimeoutMsg_HU_Mid_X451" SG_ 464 HuIcOverallTripReset 0;
BA_ "GenSigTimeoutMsg_HU_High_X451" SG_ 464 HuIcOverallTripReset 0;
BA_ "GenSigTimeoutMsg_HU_B" SG_ 464 HuIcOverallTripReset 0;
BA_ "GenSigTimeoutMsg_HU_A" SG_ 464 HuIcOverallTripReset 0;
BA_ "GenSigSendType" SG_ 464 HuIcOverallTripReset 1;
BA_ "GenSigTimeoutMsg_HU_High_X445" SG_ 464 HuIcOverallTripReset 0;
BA_ "GenSigTimeoutMsg_HU_Mid_X445" SG_ 464 HuIcOverallTripReset 0;
BA_ "GenSigTimeoutTime_HU_High_X445" SG_ 464 HuIcOverallTripReset 0;
BA_ "GenSigTimeoutTime_HU_Mid_X445" SG_ 464 HuIcOverallTripReset 0;
BA_ "GenSigTimeoutMsg_IVI" SG_ 464 HuIcOverallTripReset 0;
BA_ "GenSigTimeoutTime_IVI" SG_ 464 HuIcOverallTripReset 0;
BA_ "GenSigTimeoutTime_HU_Mid_X451" SG_ 464 HuIcOverallTripResetAck 0;
BA_ "GenSigTimeoutTime_HU_High_X451" SG_ 464 HuIcOverallTripResetAck 0;
BA_ "GenSigTimeoutTime_HU_B" SG_ 464 HuIcOverallTripResetAck 0;
BA_ "GenSigTimeoutTime_HU_A" SG_ 464 HuIcOverallTripResetAck 0;
BA_ "GenSigTimeoutMsg_HU_Mid_X451" SG_ 464 HuIcOverallTripResetAck 0;
BA_ "GenSigTimeoutMsg_HU_High_X451" SG_ 464 HuIcOverallTripResetAck 0;
BA_ "GenSigTimeoutMsg_HU_B" SG_ 464 HuIcOverallTripResetAck 0;
BA_ "GenSigTimeoutMsg_HU_A" SG_ 464 HuIcOverallTripResetAck 0;
BA_ "GenSigSendType" SG_ 464 HuIcOverallTripResetAck 1;
BA_ "GenSigTimeoutMsg_HU_High_X445" SG_ 464 HuIcOverallTripResetAck 0;
BA_ "GenSigTimeoutMsg_HU_Mid_X445" SG_ 464 HuIcOverallTripResetAck 0;
BA_ "GenSigTimeoutTime_HU_High_X445" SG_ 464 HuIcOverallTripResetAck 0;
BA_ "GenSigTimeoutTime_HU_Mid_X445" SG_ 464 HuIcOverallTripResetAck 0;
BA_ "GenSigTimeoutMsg_IVI" SG_ 464 HuIcOverallTripResetAck 0;
BA_ "GenSigTimeoutTime_IVI" SG_ 464 HuIcOverallTripResetAck 0;
BA_ "GenSigTimeoutTime_HU_Mid_X451" SG_ 464 HuIcResetAllAck 0;
BA_ "GenSigTimeoutTime_HU_High_X451" SG_ 464 HuIcResetAllAck 0;
BA_ "GenSigTimeoutTime_HU_B" SG_ 464 HuIcResetAllAck 0;
BA_ "GenSigTimeoutTime_HU_A" SG_ 464 HuIcResetAllAck 0;
BA_ "GenSigTimeoutMsg_HU_Mid_X451" SG_ 464 HuIcResetAllAck 0;
BA_ "GenSigTimeoutMsg_HU_High_X451" SG_ 464 HuIcResetAllAck 0;
BA_ "GenSigTimeoutMsg_HU_B" SG_ 464 HuIcResetAllAck 0;
BA_ "GenSigTimeoutMsg_HU_A" SG_ 464 HuIcResetAllAck 0;
BA_ "GenSigSendType" SG_ 464 HuIcResetAllAck 1;
BA_ "GenSigTimeoutMsg_HU_High_X445" SG_ 464 HuIcResetAllAck 0;
BA_ "GenSigTimeoutMsg_HU_Mid_X445" SG_ 464 HuIcResetAllAck 0;
BA_ "GenSigTimeoutTime_HU_High_X445" SG_ 464 HuIcResetAllAck 0;
BA_ "GenSigTimeoutTime_HU_Mid_X445" SG_ 464 HuIcResetAllAck 0;
BA_ "GenSigTimeoutMsg_IVI" SG_ 464 HuIcResetAllAck 0;
BA_ "GenSigTimeoutTime_IVI" SG_ 464 HuIcResetAllAck 0;
BA_ "GenSigTimeoutTime_HU_Mid_X451" SG_ 466 PDcOnDelayTimerReq 0;
BA_ "GenSigTimeoutTime_HU_High_X451" SG_ 466 PDcOnDelayTimerReq 0;
BA_ "GenSigTimeoutTime_HU_B" SG_ 466 PDcOnDelayTimerReq 0;
BA_ "GenSigTimeoutTime_HU_A" SG_ 466 PDcOnDelayTimerReq 0;
BA_ "GenSigTimeoutMsg_HU_Mid_X451" SG_ 466 PDcOnDelayTimerReq 0;
BA_ "GenSigTimeoutMsg_HU_High_X451" SG_ 466 PDcOnDelayTimerReq 0;
BA_ "GenSigTimeoutMsg_HU_B" SG_ 466 PDcOnDelayTimerReq 0;
BA_ "GenSigTimeoutMsg_HU_A" SG_ 466 PDcOnDelayTimerReq 0;
BA_ "GenSigSendType" SG_ 466 PDcOnDelayTimerReq 1;
BA_ "GenSigTimeoutMsg_HU_High_X445" SG_ 466 PDcOnDelayTimerReq 0;
BA_ "GenSigTimeoutMsg_HU_Mid_X445" SG_ 466 PDcOnDelayTimerReq 0;
BA_ "GenSigTimeoutTime_HU_High_X445" SG_ 466 PDcOnDelayTimerReq 0;
BA_ "GenSigTimeoutTime_HU_Mid_X445" SG_ 466 PDcOnDelayTimerReq 0;
BA_ "GenSigTimeoutMsg_IVI" SG_ 466 PDcOnDelayTimerReq 0;
BA_ "GenSigTimeoutTime_IVI" SG_ 466 PDcOnDelayTimerReq 0;
BA_ "GenSigTimeoutTime_HU_Mid_X451" SG_ 466 HuPDcVehicleImageAck 0;
BA_ "GenSigTimeoutTime_HU_High_X451" SG_ 466 HuPDcVehicleImageAck 0;
BA_ "GenSigTimeoutTime_HU_B" SG_ 466 HuPDcVehicleImageAck 0;
BA_ "GenSigTimeoutTime_HU_A" SG_ 466 HuPDcVehicleImageAck 0;
BA_ "GenSigTimeoutMsg_HU_Mid_X451" SG_ 466 HuPDcVehicleImageAck 0;
BA_ "GenSigTimeoutMsg_HU_High_X451" SG_ 466 HuPDcVehicleImageAck 0;
BA_ "GenSigTimeoutMsg_HU_B" SG_ 466 HuPDcVehicleImageAck 0;
BA_ "GenSigTimeoutMsg_HU_A" SG_ 466 HuPDcVehicleImageAck 0;
BA_ "GenSigSendType" SG_ 466 HuPDcVehicleImageAck 1;
BA_ "GenSigTimeoutMsg_HU_High_X445" SG_ 466 HuPDcVehicleImageAck 0;
BA_ "GenSigTimeoutMsg_HU_Mid_X445" SG_ 466 HuPDcVehicleImageAck 0;
BA_ "GenSigTimeoutTime_HU_High_X445" SG_ 466 HuPDcVehicleImageAck 0;
BA_ "GenSigTimeoutTime_HU_Mid_X445" SG_ 466 HuPDcVehicleImageAck 0;
BA_ "GenSigTimeoutMsg_IVI" SG_ 466 HuPDcVehicleImageAck 0;
BA_ "GenSigTimeoutTime_IVI" SG_ 466 HuPDcVehicleImageAck 0;
BA_ "GenSigTimeoutTime_HU_Mid_X451" SG_ 466 PDcLowSpeedActivationReq 0;
BA_ "GenSigTimeoutTime_HU_High_X451" SG_ 466 PDcLowSpeedActivationReq 0;
BA_ "GenSigTimeoutTime_HU_B" SG_ 466 PDcLowSpeedActivationReq 0;
BA_ "GenSigTimeoutTime_HU_A" SG_ 466 PDcLowSpeedActivationReq 0;
BA_ "GenSigTimeoutMsg_HU_Mid_X451" SG_ 466 PDcLowSpeedActivationReq 0;
BA_ "GenSigTimeoutMsg_HU_High_X451" SG_ 466 PDcLowSpeedActivationReq 0;
BA_ "GenSigTimeoutMsg_HU_B" SG_ 466 PDcLowSpeedActivationReq 0;
BA_ "GenSigTimeoutMsg_HU_A" SG_ 466 PDcLowSpeedActivationReq 0;
BA_ "GenSigSendType" SG_ 466 PDcLowSpeedActivationReq 1;
BA_ "GenSigTimeoutMsg_HU_High_X445" SG_ 466 PDcLowSpeedActivationReq 0;
BA_ "GenSigTimeoutMsg_HU_Mid_X445" SG_ 466 PDcLowSpeedActivationReq 0;
BA_ "GenSigTimeoutTime_HU_High_X445" SG_ 466 PDcLowSpeedActivationReq 0;
BA_ "GenSigTimeoutTime_HU_Mid_X445" SG_ 466 PDcLowSpeedActivationReq 0;
BA_ "GenSigTimeoutMsg_IVI" SG_ 466 PDcLowSpeedActivationReq 0;
BA_ "GenSigTimeoutTime_IVI" SG_ 466 PDcLowSpeedActivationReq 0;
BA_ "GenSigTimeoutTime_HU_Mid_X451" SG_ 466 PDcRearToneReq 0;
BA_ "GenSigTimeoutTime_HU_High_X451" SG_ 466 PDcRearToneReq 0;
BA_ "GenSigTimeoutTime_HU_B" SG_ 466 PDcRearToneReq 0;
BA_ "GenSigTimeoutTime_HU_A" SG_ 466 PDcRearToneReq 0;
BA_ "GenSigTimeoutMsg_HU_Mid_X451" SG_ 466 PDcRearToneReq 0;
BA_ "GenSigTimeoutMsg_HU_High_X451" SG_ 466 PDcRearToneReq 0;
BA_ "GenSigTimeoutMsg_HU_B" SG_ 466 PDcRearToneReq 0;
BA_ "GenSigTimeoutMsg_HU_A" SG_ 466 PDcRearToneReq 0;
BA_ "GenSigSendType" SG_ 466 PDcRearToneReq 1;
BA_ "GenSigTimeoutMsg_HU_High_X445" SG_ 466 PDcRearToneReq 0;
BA_ "GenSigTimeoutMsg_HU_Mid_X445" SG_ 466 PDcRearToneReq 0;
BA_ "GenSigTimeoutTime_HU_High_X445" SG_ 466 PDcRearToneReq 0;
BA_ "GenSigTimeoutTime_HU_Mid_X445" SG_ 466 PDcRearToneReq 0;
BA_ "GenSigTimeoutMsg_IVI" SG_ 466 PDcRearToneReq 0;
BA_ "GenSigTimeoutTime_IVI" SG_ 466 PDcRearToneReq 0;
BA_ "GenSigTimeoutTime_HU_Mid_X451" SG_ 466 HuPDcFrontAudioMuteStateAck 0;
BA_ "GenSigTimeoutTime_HU_High_X451" SG_ 466 HuPDcFrontAudioMuteStateAck 0;
BA_ "GenSigTimeoutTime_HU_B" SG_ 466 HuPDcFrontAudioMuteStateAck 0;
BA_ "GenSigTimeoutTime_HU_A" SG_ 466 HuPDcFrontAudioMuteStateAck 0;
BA_ "GenSigTimeoutMsg_HU_Mid_X451" SG_ 466 HuPDcFrontAudioMuteStateAck 0;
BA_ "GenSigTimeoutMsg_HU_High_X451" SG_ 466 HuPDcFrontAudioMuteStateAck 0;
BA_ "GenSigTimeoutMsg_HU_B" SG_ 466 HuPDcFrontAudioMuteStateAck 0;
BA_ "GenSigTimeoutMsg_HU_A" SG_ 466 HuPDcFrontAudioMuteStateAck 0;
BA_ "GenSigSendType" SG_ 466 HuPDcFrontAudioMuteStateAck 1;
BA_ "GenSigTimeoutMsg_HU_High_X445" SG_ 466 HuPDcFrontAudioMuteStateAck 0;
BA_ "GenSigTimeoutMsg_HU_Mid_X445" SG_ 466 HuPDcFrontAudioMuteStateAck 0;
BA_ "GenSigTimeoutTime_HU_High_X445" SG_ 466 HuPDcFrontAudioMuteStateAck 0;
BA_ "GenSigTimeoutTime_HU_Mid_X445" SG_ 466 HuPDcFrontAudioMuteStateAck 0;
BA_ "GenSigTimeoutMsg_IVI" SG_ 466 HuPDcFrontAudioMuteStateAck 0;
BA_ "GenSigTimeoutTime_IVI" SG_ 466 HuPDcFrontAudioMuteStateAck 0;
BA_ "GenSigTimeoutTime_HU_Mid_X451" SG_ 466 HuPDcRearNoOfSensAck 0;
BA_ "GenSigTimeoutTime_HU_High_X451" SG_ 466 HuPDcRearNoOfSensAck 0;
BA_ "GenSigTimeoutTime_HU_B" SG_ 466 HuPDcRearNoOfSensAck 0;
BA_ "GenSigTimeoutTime_HU_A" SG_ 466 HuPDcRearNoOfSensAck 0;
BA_ "GenSigTimeoutMsg_HU_Mid_X451" SG_ 466 HuPDcRearNoOfSensAck 0;
BA_ "GenSigTimeoutMsg_HU_High_X451" SG_ 466 HuPDcRearNoOfSensAck 0;
BA_ "GenSigTimeoutMsg_HU_B" SG_ 466 HuPDcRearNoOfSensAck 0;
BA_ "GenSigTimeoutMsg_HU_A" SG_ 466 HuPDcRearNoOfSensAck 0;
BA_ "GenSigSendType" SG_ 466 HuPDcRearNoOfSensAck 1;
BA_ "GenSigTimeoutMsg_HU_High_X445" SG_ 466 HuPDcRearNoOfSensAck 0;
BA_ "GenSigTimeoutMsg_HU_Mid_X445" SG_ 466 HuPDcRearNoOfSensAck 0;
BA_ "GenSigTimeoutTime_HU_High_X445" SG_ 466 HuPDcRearNoOfSensAck 0;
BA_ "GenSigTimeoutTime_HU_Mid_X445" SG_ 466 HuPDcRearNoOfSensAck 0;
BA_ "GenSigTimeoutMsg_IVI" SG_ 466 HuPDcRearNoOfSensAck 0;
BA_ "GenSigTimeoutTime_IVI" SG_ 466 HuPDcRearNoOfSensAck 0;
BA_ "GenSigTimeoutTime_HU_Mid_X451" SG_ 466 PDcToneVolumeReq 0;
BA_ "GenSigTimeoutTime_HU_High_X451" SG_ 466 PDcToneVolumeReq 0;
BA_ "GenSigTimeoutTime_HU_B" SG_ 466 PDcToneVolumeReq 0;
BA_ "GenSigTimeoutTime_HU_A" SG_ 466 PDcToneVolumeReq 0;
BA_ "GenSigTimeoutMsg_HU_Mid_X451" SG_ 466 PDcToneVolumeReq 0;
BA_ "GenSigTimeoutMsg_HU_High_X451" SG_ 466 PDcToneVolumeReq 0;
BA_ "GenSigTimeoutMsg_HU_B" SG_ 466 PDcToneVolumeReq 0;
BA_ "GenSigTimeoutMsg_HU_A" SG_ 466 PDcToneVolumeReq 0;
BA_ "GenSigStartValue" SG_ 466 PDcToneVolumeReq 1;
BA_ "GenSigSendType" SG_ 466 PDcToneVolumeReq 1;
BA_ "GenSigTimeoutMsg_HU_High_X445" SG_ 466 PDcToneVolumeReq 0;
BA_ "GenSigTimeoutMsg_HU_Mid_X445" SG_ 466 PDcToneVolumeReq 0;
BA_ "GenSigTimeoutTime_HU_High_X445" SG_ 466 PDcToneVolumeReq 0;
BA_ "GenSigTimeoutTime_HU_Mid_X445" SG_ 466 PDcToneVolumeReq 0;
BA_ "GenSigTimeoutMsg_IVI" SG_ 466 PDcToneVolumeReq 0;
BA_ "GenSigTimeoutTime_IVI" SG_ 466 PDcToneVolumeReq 0;
BA_ "GenSigTimeoutTime_HU_Mid_X451" SG_ 466 HuPDcOnDelayTimerAck 0;
BA_ "GenSigTimeoutTime_HU_High_X451" SG_ 466 HuPDcOnDelayTimerAck 0;
BA_ "GenSigTimeoutTime_HU_B" SG_ 466 HuPDcOnDelayTimerAck 0;
BA_ "GenSigTimeoutTime_HU_A" SG_ 466 HuPDcOnDelayTimerAck 0;
BA_ "GenSigTimeoutMsg_HU_Mid_X451" SG_ 466 HuPDcOnDelayTimerAck 0;
BA_ "GenSigTimeoutMsg_HU_High_X451" SG_ 466 HuPDcOnDelayTimerAck 0;
BA_ "GenSigTimeoutMsg_HU_B" SG_ 466 HuPDcOnDelayTimerAck 0;
BA_ "GenSigTimeoutMsg_HU_A" SG_ 466 HuPDcOnDelayTimerAck 0;
BA_ "GenSigStartValue" SG_ 466 HuPDcOnDelayTimerAck 1;
BA_ "GenSigSendType" SG_ 466 HuPDcOnDelayTimerAck 1;
BA_ "GenSigTimeoutMsg_HU_High_X445" SG_ 466 HuPDcOnDelayTimerAck 0;
BA_ "GenSigTimeoutMsg_HU_Mid_X445" SG_ 466 HuPDcOnDelayTimerAck 0;
BA_ "GenSigTimeoutTime_HU_High_X445" SG_ 466 HuPDcOnDelayTimerAck 0;
BA_ "GenSigTimeoutTime_HU_Mid_X445" SG_ 466 HuPDcOnDelayTimerAck 0;
BA_ "GenSigTimeoutMsg_IVI" SG_ 466 HuPDcOnDelayTimerAck 0;
BA_ "GenSigTimeoutTime_IVI" SG_ 466 HuPDcOnDelayTimerAck 0;
BA_ "GenSigTimeoutTime_HU_Mid_X451" SG_ 466 PDcFrontAudioMuteReq 0;
BA_ "GenSigTimeoutTime_HU_High_X451" SG_ 466 PDcFrontAudioMuteReq 0;
BA_ "GenSigTimeoutTime_HU_B" SG_ 466 PDcFrontAudioMuteReq 0;
BA_ "GenSigTimeoutTime_HU_A" SG_ 466 PDcFrontAudioMuteReq 0;
BA_ "GenSigTimeoutMsg_HU_Mid_X451" SG_ 466 PDcFrontAudioMuteReq 0;
BA_ "GenSigTimeoutMsg_HU_High_X451" SG_ 466 PDcFrontAudioMuteReq 0;
BA_ "GenSigTimeoutMsg_HU_B" SG_ 466 PDcFrontAudioMuteReq 0;
BA_ "GenSigTimeoutMsg_HU_A" SG_ 466 PDcFrontAudioMuteReq 0;
BA_ "GenSigSendType" SG_ 466 PDcFrontAudioMuteReq 1;
BA_ "GenSigTimeoutMsg_HU_High_X445" SG_ 466 PDcFrontAudioMuteReq 0;
BA_ "GenSigTimeoutMsg_HU_Mid_X445" SG_ 466 PDcFrontAudioMuteReq 0;
BA_ "GenSigTimeoutTime_HU_High_X445" SG_ 466 PDcFrontAudioMuteReq 0;
BA_ "GenSigTimeoutTime_HU_Mid_X445" SG_ 466 PDcFrontAudioMuteReq 0;
BA_ "GenSigTimeoutMsg_IVI" SG_ 466 PDcFrontAudioMuteReq 0;
BA_ "GenSigTimeoutTime_IVI" SG_ 466 PDcFrontAudioMuteReq 0;
BA_ "GenSigTimeoutTime_HU_Mid_X451" SG_ 466 HuPDcReqType 0;
BA_ "GenSigTimeoutTime_HU_High_X451" SG_ 466 HuPDcReqType 0;
BA_ "GenSigTimeoutTime_HU_B" SG_ 466 HuPDcReqType 0;
BA_ "GenSigTimeoutTime_HU_A" SG_ 466 HuPDcReqType 0;
BA_ "GenSigTimeoutMsg_HU_Mid_X451" SG_ 466 HuPDcReqType 0;
BA_ "GenSigTimeoutMsg_HU_High_X451" SG_ 466 HuPDcReqType 0;
BA_ "GenSigTimeoutMsg_HU_B" SG_ 466 HuPDcReqType 0;
BA_ "GenSigTimeoutMsg_HU_A" SG_ 466 HuPDcReqType 0;
BA_ "GenSigSendType" SG_ 466 HuPDcReqType 1;
BA_ "GenSigTimeoutMsg_HU_High_X445" SG_ 466 HuPDcReqType 0;
BA_ "GenSigTimeoutMsg_HU_Mid_X445" SG_ 466 HuPDcReqType 0;
BA_ "GenSigTimeoutTime_HU_High_X445" SG_ 466 HuPDcReqType 0;
BA_ "GenSigTimeoutTime_HU_Mid_X445" SG_ 466 HuPDcReqType 0;
BA_ "GenSigTimeoutMsg_IVI" SG_ 466 HuPDcReqType 0;
BA_ "GenSigTimeoutTime_IVI" SG_ 466 HuPDcReqType 0;
BA_ "GenSigTimeoutTime_HU_Mid_X451" SG_ 466 HuPDcRearToneAck 0;
BA_ "GenSigTimeoutTime_HU_High_X451" SG_ 466 HuPDcRearToneAck 0;
BA_ "GenSigTimeoutTime_HU_B" SG_ 466 HuPDcRearToneAck 0;
BA_ "GenSigTimeoutTime_HU_A" SG_ 466 HuPDcRearToneAck 0;
BA_ "GenSigTimeoutMsg_HU_Mid_X451" SG_ 466 HuPDcRearToneAck 0;
BA_ "GenSigTimeoutMsg_HU_High_X451" SG_ 466 HuPDcRearToneAck 0;
BA_ "GenSigTimeoutMsg_HU_B" SG_ 466 HuPDcRearToneAck 0;
BA_ "GenSigTimeoutMsg_HU_A" SG_ 466 HuPDcRearToneAck 0;
BA_ "GenSigSendType" SG_ 466 HuPDcRearToneAck 1;
BA_ "GenSigTimeoutMsg_HU_High_X445" SG_ 466 HuPDcRearToneAck 0;
BA_ "GenSigTimeoutMsg_HU_Mid_X445" SG_ 466 HuPDcRearToneAck 0;
BA_ "GenSigTimeoutTime_HU_High_X445" SG_ 466 HuPDcRearToneAck 0;
BA_ "GenSigTimeoutTime_HU_Mid_X445" SG_ 466 HuPDcRearToneAck 0;
BA_ "GenSigTimeoutMsg_IVI" SG_ 466 HuPDcRearToneAck 0;
BA_ "GenSigTimeoutTime_IVI" SG_ 466 HuPDcRearToneAck 0;
BA_ "GenSigTimeoutTime_HU_Mid_X451" SG_ 466 HuPDcFrontToneAck 0;
BA_ "GenSigTimeoutTime_HU_High_X451" SG_ 466 HuPDcFrontToneAck 0;
BA_ "GenSigTimeoutTime_HU_B" SG_ 466 HuPDcFrontToneAck 0;
BA_ "GenSigTimeoutTime_HU_A" SG_ 466 HuPDcFrontToneAck 0;
BA_ "GenSigTimeoutMsg_HU_Mid_X451" SG_ 466 HuPDcFrontToneAck 0;
BA_ "GenSigTimeoutMsg_HU_High_X451" SG_ 466 HuPDcFrontToneAck 0;
BA_ "GenSigTimeoutMsg_HU_B" SG_ 466 HuPDcFrontToneAck 0;
BA_ "GenSigTimeoutMsg_HU_A" SG_ 466 HuPDcFrontToneAck 0;
BA_ "GenSigSendType" SG_ 466 HuPDcFrontToneAck 1;
BA_ "GenSigTimeoutMsg_HU_High_X445" SG_ 466 HuPDcFrontToneAck 0;
BA_ "GenSigTimeoutMsg_HU_Mid_X445" SG_ 466 HuPDcFrontToneAck 0;
BA_ "GenSigTimeoutTime_HU_High_X445" SG_ 466 HuPDcFrontToneAck 0;
BA_ "GenSigTimeoutTime_HU_Mid_X445" SG_ 466 HuPDcFrontToneAck 0;
BA_ "GenSigTimeoutMsg_IVI" SG_ 466 HuPDcFrontToneAck 0;
BA_ "GenSigTimeoutTime_IVI" SG_ 466 HuPDcFrontToneAck 0;
BA_ "GenSigTimeoutTime_HU_Mid_X451" SG_ 466 HuPDcToneVolumeAck 0;
BA_ "GenSigTimeoutTime_HU_High_X451" SG_ 466 HuPDcToneVolumeAck 0;
BA_ "GenSigTimeoutTime_HU_B" SG_ 466 HuPDcToneVolumeAck 0;
BA_ "GenSigTimeoutTime_HU_A" SG_ 466 HuPDcToneVolumeAck 0;
BA_ "GenSigTimeoutMsg_HU_Mid_X451" SG_ 466 HuPDcToneVolumeAck 0;
BA_ "GenSigTimeoutMsg_HU_High_X451" SG_ 466 HuPDcToneVolumeAck 0;
BA_ "GenSigTimeoutMsg_HU_B" SG_ 466 HuPDcToneVolumeAck 0;
BA_ "GenSigTimeoutMsg_HU_A" SG_ 466 HuPDcToneVolumeAck 0;
BA_ "GenSigSendType" SG_ 466 HuPDcToneVolumeAck 1;
BA_ "GenSigTimeoutMsg_HU_High_X445" SG_ 466 HuPDcToneVolumeAck 0;
BA_ "GenSigTimeoutMsg_HU_Mid_X445" SG_ 466 HuPDcToneVolumeAck 0;
BA_ "GenSigTimeoutTime_HU_High_X445" SG_ 466 HuPDcToneVolumeAck 0;
BA_ "GenSigTimeoutTime_HU_Mid_X445" SG_ 466 HuPDcToneVolumeAck 0;
BA_ "GenSigTimeoutMsg_IVI" SG_ 466 HuPDcToneVolumeAck 0;
BA_ "GenSigTimeoutTime_IVI" SG_ 466 HuPDcToneVolumeAck 0;
BA_ "GenSigTimeoutTime_HU_Mid_X451" SG_ 466 HuPDcFrontNoOfSensAck 0;
BA_ "GenSigTimeoutTime_HU_High_X451" SG_ 466 HuPDcFrontNoOfSensAck 0;
BA_ "GenSigTimeoutTime_HU_B" SG_ 466 HuPDcFrontNoOfSensAck 0;
BA_ "GenSigTimeoutTime_HU_A" SG_ 466 HuPDcFrontNoOfSensAck 0;
BA_ "GenSigTimeoutMsg_HU_Mid_X451" SG_ 466 HuPDcFrontNoOfSensAck 0;
BA_ "GenSigTimeoutMsg_HU_High_X451" SG_ 466 HuPDcFrontNoOfSensAck 0;
BA_ "GenSigTimeoutMsg_HU_B" SG_ 466 HuPDcFrontNoOfSensAck 0;
BA_ "GenSigTimeoutMsg_HU_A" SG_ 466 HuPDcFrontNoOfSensAck 0;
BA_ "GenSigSendType" SG_ 466 HuPDcFrontNoOfSensAck 1;
BA_ "GenSigTimeoutMsg_HU_High_X445" SG_ 466 HuPDcFrontNoOfSensAck 0;
BA_ "GenSigTimeoutMsg_HU_Mid_X445" SG_ 466 HuPDcFrontNoOfSensAck 0;
BA_ "GenSigTimeoutTime_HU_High_X445" SG_ 466 HuPDcFrontNoOfSensAck 0;
BA_ "GenSigTimeoutTime_HU_Mid_X445" SG_ 466 HuPDcFrontNoOfSensAck 0;
BA_ "GenSigTimeoutMsg_IVI" SG_ 466 HuPDcFrontNoOfSensAck 0;
BA_ "GenSigTimeoutTime_IVI" SG_ 466 HuPDcFrontNoOfSensAck 0;
BA_ "GenSigTimeoutTime_HU_Mid_X451" SG_ 466 PDcFrontToneReq 0;
BA_ "GenSigTimeoutTime_HU_High_X451" SG_ 466 PDcFrontToneReq 0;
BA_ "GenSigTimeoutTime_HU_B" SG_ 466 PDcFrontToneReq 0;
BA_ "GenSigTimeoutTime_HU_A" SG_ 466 PDcFrontToneReq 0;
BA_ "GenSigTimeoutMsg_HU_Mid_X451" SG_ 466 PDcFrontToneReq 0;
BA_ "GenSigTimeoutMsg_HU_High_X451" SG_ 466 PDcFrontToneReq 0;
BA_ "GenSigTimeoutMsg_HU_B" SG_ 466 PDcFrontToneReq 0;
BA_ "GenSigTimeoutMsg_HU_A" SG_ 466 PDcFrontToneReq 0;
BA_ "GenSigSendType" SG_ 466 PDcFrontToneReq 1;
BA_ "GenSigTimeoutMsg_HU_High_X445" SG_ 466 PDcFrontToneReq 0;
BA_ "GenSigTimeoutMsg_HU_Mid_X445" SG_ 466 PDcFrontToneReq 0;
BA_ "GenSigTimeoutTime_HU_High_X445" SG_ 466 PDcFrontToneReq 0;
BA_ "GenSigTimeoutTime_HU_Mid_X445" SG_ 466 PDcFrontToneReq 0;
BA_ "GenSigTimeoutMsg_IVI" SG_ 466 PDcFrontToneReq 0;
BA_ "GenSigTimeoutTime_IVI" SG_ 466 PDcFrontToneReq 0;
BA_ "GenSigTimeoutTime_HU_Mid_X451" SG_ 466 HuPDCFrontActivationStateAck 0;
BA_ "GenSigTimeoutTime_HU_High_X451" SG_ 466 HuPDCFrontActivationStateAck 0;
BA_ "GenSigTimeoutTime_HU_B" SG_ 466 HuPDCFrontActivationStateAck 0;
BA_ "GenSigTimeoutTime_HU_A" SG_ 466 HuPDCFrontActivationStateAck 0;
BA_ "GenSigTimeoutMsg_HU_Mid_X451" SG_ 466 HuPDCFrontActivationStateAck 0;
BA_ "GenSigTimeoutMsg_HU_High_X451" SG_ 466 HuPDCFrontActivationStateAck 0;
BA_ "GenSigTimeoutMsg_HU_B" SG_ 466 HuPDCFrontActivationStateAck 0;
BA_ "GenSigTimeoutMsg_HU_A" SG_ 466 HuPDCFrontActivationStateAck 0;
BA_ "GenSigSendType" SG_ 466 HuPDCFrontActivationStateAck 1;
BA_ "GenSigTimeoutMsg_HU_High_X445" SG_ 466 HuPDCFrontActivationStateAck 0;
BA_ "GenSigTimeoutMsg_HU_Mid_X445" SG_ 466 HuPDCFrontActivationStateAck 0;
BA_ "GenSigTimeoutTime_HU_High_X445" SG_ 466 HuPDCFrontActivationStateAck 0;
BA_ "GenSigTimeoutTime_HU_Mid_X445" SG_ 466 HuPDCFrontActivationStateAck 0;
BA_ "GenSigTimeoutMsg_IVI" SG_ 466 HuPDCFrontActivationStateAck 0;
BA_ "GenSigTimeoutTime_IVI" SG_ 466 HuPDCFrontActivationStateAck 0;
BA_ "GenSigTimeoutTime_HU_Mid_X451" SG_ 466 PDcFrontActivationStateReq 0;
BA_ "GenSigTimeoutTime_HU_High_X451" SG_ 466 PDcFrontActivationStateReq 0;
BA_ "GenSigTimeoutTime_HU_B" SG_ 466 PDcFrontActivationStateReq 0;
BA_ "GenSigTimeoutTime_HU_A" SG_ 466 PDcFrontActivationStateReq 0;
BA_ "GenSigTimeoutMsg_HU_Mid_X451" SG_ 466 PDcFrontActivationStateReq 0;
BA_ "GenSigTimeoutMsg_HU_High_X451" SG_ 466 PDcFrontActivationStateReq 0;
BA_ "GenSigTimeoutMsg_HU_B" SG_ 466 PDcFrontActivationStateReq 0;
BA_ "GenSigTimeoutMsg_HU_A" SG_ 466 PDcFrontActivationStateReq 0;
BA_ "GenSigSendType" SG_ 466 PDcFrontActivationStateReq 1;
BA_ "GenSigTimeoutMsg_HU_High_X445" SG_ 466 PDcFrontActivationStateReq 0;
BA_ "GenSigTimeoutMsg_HU_Mid_X445" SG_ 466 PDcFrontActivationStateReq 0;
BA_ "GenSigTimeoutTime_HU_High_X445" SG_ 466 PDcFrontActivationStateReq 0;
BA_ "GenSigTimeoutTime_HU_Mid_X445" SG_ 466 PDcFrontActivationStateReq 0;
BA_ "GenSigTimeoutMsg_IVI" SG_ 466 PDcFrontActivationStateReq 0;
BA_ "GenSigTimeoutTime_IVI" SG_ 466 PDcFrontActivationStateReq 0;
BA_ "GenSigTimeoutTime_HU_Mid_X451" SG_ 466 HuPDCLowSpeedActivationAck 0;
BA_ "GenSigTimeoutTime_HU_High_X451" SG_ 466 HuPDCLowSpeedActivationAck 0;
BA_ "GenSigTimeoutTime_HU_B" SG_ 466 HuPDCLowSpeedActivationAck 0;
BA_ "GenSigTimeoutTime_HU_A" SG_ 466 HuPDCLowSpeedActivationAck 0;
BA_ "GenSigTimeoutMsg_HU_Mid_X451" SG_ 466 HuPDCLowSpeedActivationAck 0;
BA_ "GenSigTimeoutMsg_HU_High_X451" SG_ 466 HuPDCLowSpeedActivationAck 0;
BA_ "GenSigTimeoutMsg_HU_B" SG_ 466 HuPDCLowSpeedActivationAck 0;
BA_ "GenSigTimeoutMsg_HU_A" SG_ 466 HuPDCLowSpeedActivationAck 0;
BA_ "GenSigSendType" SG_ 466 HuPDCLowSpeedActivationAck 1;
BA_ "GenSigTimeoutMsg_HU_High_X445" SG_ 466 HuPDCLowSpeedActivationAck 0;
BA_ "GenSigTimeoutMsg_HU_Mid_X445" SG_ 466 HuPDCLowSpeedActivationAck 0;
BA_ "GenSigTimeoutTime_HU_High_X445" SG_ 466 HuPDCLowSpeedActivationAck 0;
BA_ "GenSigTimeoutTime_HU_Mid_X445" SG_ 466 HuPDCLowSpeedActivationAck 0;
BA_ "GenSigTimeoutMsg_IVI" SG_ 466 HuPDCLowSpeedActivationAck 0;
BA_ "GenSigTimeoutTime_IVI" SG_ 466 HuPDCLowSpeedActivationAck 0;
BA_ "GenSigTimeoutTime_HU_Mid_X451" SG_ 466 RVcOverlayTypeAck 0;
BA_ "GenSigTimeoutTime_HU_High_X451" SG_ 466 RVcOverlayTypeAck 0;
BA_ "GenSigTimeoutTime_HU_B" SG_ 466 RVcOverlayTypeAck 0;
BA_ "GenSigTimeoutTime_HU_A" SG_ 466 RVcOverlayTypeAck 0;
BA_ "GenSigTimeoutMsg_HU_Mid_X451" SG_ 466 RVcOverlayTypeAck 0;
BA_ "GenSigTimeoutMsg_HU_High_X451" SG_ 466 RVcOverlayTypeAck 0;
BA_ "GenSigTimeoutMsg_HU_B" SG_ 466 RVcOverlayTypeAck 0;
BA_ "GenSigTimeoutMsg_HU_A" SG_ 466 RVcOverlayTypeAck 0;
BA_ "GenSigSendType" SG_ 466 RVcOverlayTypeAck 1;
BA_ "GenSigTimeoutMsg_HU_High_X445" SG_ 466 RVcOverlayTypeAck 0;
BA_ "GenSigTimeoutMsg_HU_Mid_X445" SG_ 466 RVcOverlayTypeAck 0;
BA_ "GenSigTimeoutTime_HU_High_X445" SG_ 466 RVcOverlayTypeAck 0;
BA_ "GenSigTimeoutTime_HU_Mid_X445" SG_ 466 RVcOverlayTypeAck 0;
BA_ "GenSigTimeoutMsg_IVI" SG_ 466 RVcOverlayTypeAck 0;
BA_ "GenSigTimeoutTime_IVI" SG_ 466 RVcOverlayTypeAck 0;
BA_ "GenSigTimeoutTime_HU_Mid_X451" SG_ 466 RVcImageRotationTypeAck 0;
BA_ "GenSigTimeoutTime_HU_High_X451" SG_ 466 RVcImageRotationTypeAck 0;
BA_ "GenSigTimeoutTime_HU_B" SG_ 466 RVcImageRotationTypeAck 0;
BA_ "GenSigTimeoutTime_HU_A" SG_ 466 RVcImageRotationTypeAck 0;
BA_ "GenSigTimeoutMsg_HU_Mid_X451" SG_ 466 RVcImageRotationTypeAck 0;
BA_ "GenSigTimeoutMsg_HU_High_X451" SG_ 466 RVcImageRotationTypeAck 0;
BA_ "GenSigTimeoutMsg_HU_B" SG_ 466 RVcImageRotationTypeAck 0;
BA_ "GenSigTimeoutMsg_HU_A" SG_ 466 RVcImageRotationTypeAck 0;
BA_ "GenSigSendType" SG_ 466 RVcImageRotationTypeAck 1;
BA_ "GenSigTimeoutMsg_HU_High_X445" SG_ 466 RVcImageRotationTypeAck 0;
BA_ "GenSigTimeoutMsg_HU_Mid_X445" SG_ 466 RVcImageRotationTypeAck 0;
BA_ "GenSigTimeoutTime_HU_High_X445" SG_ 466 RVcImageRotationTypeAck 0;
BA_ "GenSigTimeoutTime_HU_Mid_X445" SG_ 466 RVcImageRotationTypeAck 0;
BA_ "GenSigTimeoutMsg_IVI" SG_ 466 RVcImageRotationTypeAck 0;
BA_ "GenSigTimeoutTime_IVI" SG_ 466 RVcImageRotationTypeAck 0;
BA_ "GenSigTimeoutTime_HU_Mid_X451" SG_ 469 HuIcTempUnitSet 0;
BA_ "GenSigTimeoutTime_HU_High_X451" SG_ 469 HuIcTempUnitSet 0;
BA_ "GenSigTimeoutTime_HU_B" SG_ 469 HuIcTempUnitSet 0;
BA_ "GenSigTimeoutTime_HU_A" SG_ 469 HuIcTempUnitSet 0;
BA_ "GenSigTimeoutMsg_HU_Mid_X451" SG_ 469 HuIcTempUnitSet 0;
BA_ "GenSigTimeoutMsg_HU_High_X451" SG_ 469 HuIcTempUnitSet 0;
BA_ "GenSigTimeoutMsg_HU_B" SG_ 469 HuIcTempUnitSet 0;
BA_ "GenSigTimeoutMsg_HU_A" SG_ 469 HuIcTempUnitSet 0;
BA_ "GenSigSendType" SG_ 469 HuIcTempUnitSet 1;
BA_ "GenSigTimeoutMsg_HU_High_X445" SG_ 469 HuIcTempUnitSet 0;
BA_ "GenSigTimeoutMsg_HU_Mid_X445" SG_ 469 HuIcTempUnitSet 0;
BA_ "GenSigTimeoutTime_HU_High_X445" SG_ 469 HuIcTempUnitSet 0;
BA_ "GenSigTimeoutTime_HU_Mid_X445" SG_ 469 HuIcTempUnitSet 0;
BA_ "GenSigTimeoutMsg_IVI" SG_ 469 HuIcTempUnitSet 0;
BA_ "GenSigTimeoutTime_IVI" SG_ 469 HuIcTempUnitSet 0;
BA_ "GenSigTimeoutTime_HU_Mid_X451" SG_ 469 HuIcDistUnitSet 0;
BA_ "GenSigTimeoutTime_HU_High_X451" SG_ 469 HuIcDistUnitSet 0;
BA_ "GenSigTimeoutTime_HU_B" SG_ 469 HuIcDistUnitSet 0;
BA_ "GenSigTimeoutTime_HU_A" SG_ 469 HuIcDistUnitSet 0;
BA_ "GenSigTimeoutMsg_HU_Mid_X451" SG_ 469 HuIcDistUnitSet 0;
BA_ "GenSigTimeoutMsg_HU_High_X451" SG_ 469 HuIcDistUnitSet 0;
BA_ "GenSigTimeoutMsg_HU_B" SG_ 469 HuIcDistUnitSet 0;
BA_ "GenSigTimeoutMsg_HU_A" SG_ 469 HuIcDistUnitSet 0;
BA_ "GenSigSendType" SG_ 469 HuIcDistUnitSet 1;
BA_ "GenSigTimeoutMsg_HU_High_X445" SG_ 469 HuIcDistUnitSet 0;
BA_ "GenSigTimeoutMsg_HU_Mid_X445" SG_ 469 HuIcDistUnitSet 0;
BA_ "GenSigTimeoutTime_HU_High_X445" SG_ 469 HuIcDistUnitSet 0;
BA_ "GenSigTimeoutTime_HU_Mid_X445" SG_ 469 HuIcDistUnitSet 0;
BA_ "GenSigTimeoutMsg_IVI" SG_ 469 HuIcDistUnitSet 0;
BA_ "GenSigTimeoutTime_IVI" SG_ 469 HuIcDistUnitSet 0;
BA_ "GenSigTimeoutTime_HU_Mid_X451" SG_ 469 HuIcSecondsInfo 0;
BA_ "GenSigTimeoutTime_HU_High_X451" SG_ 469 HuIcSecondsInfo 0;
BA_ "GenSigTimeoutTime_HU_B" SG_ 469 HuIcSecondsInfo 0;
BA_ "GenSigTimeoutTime_HU_A" SG_ 469 HuIcSecondsInfo 0;
BA_ "GenSigTimeoutMsg_HU_Mid_X451" SG_ 469 HuIcSecondsInfo 0;
BA_ "GenSigTimeoutMsg_HU_High_X451" SG_ 469 HuIcSecondsInfo 0;
BA_ "GenSigTimeoutMsg_HU_B" SG_ 469 HuIcSecondsInfo 0;
BA_ "GenSigTimeoutMsg_HU_A" SG_ 469 HuIcSecondsInfo 0;
BA_ "GenSigSendType" SG_ 469 HuIcSecondsInfo 1;
BA_ "GenSigTimeoutMsg_HU_High_X445" SG_ 469 HuIcSecondsInfo 0;
BA_ "GenSigTimeoutMsg_HU_Mid_X445" SG_ 469 HuIcSecondsInfo 0;
BA_ "GenSigTimeoutTime_HU_High_X445" SG_ 469 HuIcSecondsInfo 0;
BA_ "GenSigTimeoutTime_HU_Mid_X445" SG_ 469 HuIcSecondsInfo 0;
BA_ "GenSigTimeoutMsg_IVI" SG_ 469 HuIcSecondsInfo 0;
BA_ "GenSigTimeoutTime_IVI" SG_ 469 HuIcSecondsInfo 0;
BA_ "GenSigTimeoutTime_HU_Mid_X451" SG_ 469 HuIcFuelUnitSet 0;
BA_ "GenSigTimeoutTime_HU_High_X451" SG_ 469 HuIcFuelUnitSet 0;
BA_ "GenSigTimeoutTime_HU_B" SG_ 469 HuIcFuelUnitSet 0;
BA_ "GenSigTimeoutTime_HU_A" SG_ 469 HuIcFuelUnitSet 0;
BA_ "GenSigTimeoutMsg_HU_Mid_X451" SG_ 469 HuIcFuelUnitSet 0;
BA_ "GenSigTimeoutMsg_HU_High_X451" SG_ 469 HuIcFuelUnitSet 0;
BA_ "GenSigTimeoutMsg_HU_B" SG_ 469 HuIcFuelUnitSet 0;
BA_ "GenSigTimeoutMsg_HU_A" SG_ 469 HuIcFuelUnitSet 0;
BA_ "GenSigSendType" SG_ 469 HuIcFuelUnitSet 1;
BA_ "GenSigTimeoutMsg_HU_High_X445" SG_ 469 HuIcFuelUnitSet 0;
BA_ "GenSigTimeoutMsg_HU_Mid_X445" SG_ 469 HuIcFuelUnitSet 0;
BA_ "GenSigTimeoutTime_HU_High_X445" SG_ 469 HuIcFuelUnitSet 0;
BA_ "GenSigTimeoutTime_HU_Mid_X445" SG_ 469 HuIcFuelUnitSet 0;
BA_ "GenSigTimeoutMsg_IVI" SG_ 469 HuIcFuelUnitSet 0;
BA_ "GenSigTimeoutTime_IVI" SG_ 469 HuIcFuelUnitSet 0;
BA_ "GenSigTimeoutTime_HU_Mid_X451" SG_ 469 HuIcMinuteInfo 0;
BA_ "GenSigTimeoutTime_HU_High_X451" SG_ 469 HuIcMinuteInfo 0;
BA_ "GenSigTimeoutTime_HU_B" SG_ 469 HuIcMinuteInfo 0;
BA_ "GenSigTimeoutTime_HU_A" SG_ 469 HuIcMinuteInfo 0;
BA_ "GenSigTimeoutMsg_HU_Mid_X451" SG_ 469 HuIcMinuteInfo 0;
BA_ "GenSigTimeoutMsg_HU_High_X451" SG_ 469 HuIcMinuteInfo 0;
BA_ "GenSigTimeoutMsg_HU_B" SG_ 469 HuIcMinuteInfo 0;
BA_ "GenSigTimeoutMsg_HU_A" SG_ 469 HuIcMinuteInfo 0;
BA_ "GenSigSendType" SG_ 469 HuIcMinuteInfo 1;
BA_ "GenSigTimeoutMsg_HU_High_X445" SG_ 469 HuIcMinuteInfo 0;
BA_ "GenSigTimeoutMsg_HU_Mid_X445" SG_ 469 HuIcMinuteInfo 0;
BA_ "GenSigTimeoutTime_HU_High_X445" SG_ 469 HuIcMinuteInfo 0;
BA_ "GenSigTimeoutTime_HU_Mid_X445" SG_ 469 HuIcMinuteInfo 0;
BA_ "GenSigTimeoutMsg_IVI" SG_ 469 HuIcMinuteInfo 0;
BA_ "GenSigTimeoutTime_IVI" SG_ 469 HuIcMinuteInfo 0;
BA_ "GenSigTimeoutTime_HU_Mid_X451" SG_ 469 HuIcClockMode 0;
BA_ "GenSigTimeoutTime_HU_High_X451" SG_ 469 HuIcClockMode 0;
BA_ "GenSigTimeoutTime_HU_B" SG_ 469 HuIcClockMode 0;
BA_ "GenSigTimeoutTime_HU_A" SG_ 469 HuIcClockMode 0;
BA_ "GenSigTimeoutMsg_HU_Mid_X451" SG_ 469 HuIcClockMode 0;
BA_ "GenSigTimeoutMsg_HU_High_X451" SG_ 469 HuIcClockMode 0;
BA_ "GenSigTimeoutMsg_HU_B" SG_ 469 HuIcClockMode 0;
BA_ "GenSigTimeoutMsg_HU_A" SG_ 469 HuIcClockMode 0;
BA_ "GenSigSendType" SG_ 469 HuIcClockMode 1;
BA_ "GenSigTimeoutMsg_HU_High_X445" SG_ 469 HuIcClockMode 0;
BA_ "GenSigTimeoutMsg_HU_Mid_X445" SG_ 469 HuIcClockMode 0;
BA_ "GenSigTimeoutTime_HU_High_X445" SG_ 469 HuIcClockMode 0;
BA_ "GenSigTimeoutTime_HU_Mid_X445" SG_ 469 HuIcClockMode 0;
BA_ "GenSigTimeoutMsg_IVI" SG_ 469 HuIcClockMode 0;
BA_ "GenSigTimeoutTime_IVI" SG_ 469 HuIcClockMode 0;
BA_ "GenSigTimeoutTime_HU_Mid_X451" SG_ 469 QueryIcHuUnitSetInfo 0;
BA_ "GenSigTimeoutTime_HU_High_X451" SG_ 469 QueryIcHuUnitSetInfo 0;
BA_ "GenSigTimeoutTime_HU_B" SG_ 469 QueryIcHuUnitSetInfo 0;
BA_ "GenSigTimeoutTime_HU_A" SG_ 469 QueryIcHuUnitSetInfo 0;
BA_ "GenSigTimeoutMsg_HU_Mid_X451" SG_ 469 QueryIcHuUnitSetInfo 0;
BA_ "GenSigTimeoutMsg_HU_High_X451" SG_ 469 QueryIcHuUnitSetInfo 0;
BA_ "GenSigTimeoutMsg_HU_B" SG_ 469 QueryIcHuUnitSetInfo 0;
BA_ "GenSigTimeoutMsg_HU_A" SG_ 469 QueryIcHuUnitSetInfo 0;
BA_ "GenSigSendType" SG_ 469 QueryIcHuUnitSetInfo 1;
BA_ "GenSigTimeoutMsg_HU_High_X445" SG_ 469 QueryIcHuUnitSetInfo 0;
BA_ "GenSigTimeoutMsg_HU_Mid_X445" SG_ 469 QueryIcHuUnitSetInfo 0;
BA_ "GenSigTimeoutTime_HU_High_X445" SG_ 469 QueryIcHuUnitSetInfo 0;
BA_ "GenSigTimeoutTime_HU_Mid_X445" SG_ 469 QueryIcHuUnitSetInfo 0;
BA_ "GenSigTimeoutMsg_IVI" SG_ 469 QueryIcHuUnitSetInfo 0;
BA_ "GenSigTimeoutTime_IVI" SG_ 469 QueryIcHuUnitSetInfo 0;
BA_ "GenSigTimeoutTime_HU_Mid_X451" SG_ 469 HuIcRtcTypeNew 0;
BA_ "GenSigTimeoutTime_HU_High_X451" SG_ 469 HuIcRtcTypeNew 0;
BA_ "GenSigTimeoutTime_HU_B" SG_ 469 HuIcRtcTypeNew 0;
BA_ "GenSigTimeoutTime_HU_A" SG_ 469 HuIcRtcTypeNew 0;
BA_ "GenSigTimeoutMsg_HU_Mid_X451" SG_ 469 HuIcRtcTypeNew 0;
BA_ "GenSigTimeoutMsg_HU_High_X451" SG_ 469 HuIcRtcTypeNew 0;
BA_ "GenSigTimeoutMsg_HU_B" SG_ 469 HuIcRtcTypeNew 0;
BA_ "GenSigTimeoutMsg_HU_A" SG_ 469 HuIcRtcTypeNew 0;
BA_ "GenSigSendType" SG_ 469 HuIcRtcTypeNew 1;
BA_ "GenSigTimeoutMsg_HU_High_X445" SG_ 469 HuIcRtcTypeNew 0;
BA_ "GenSigTimeoutMsg_HU_Mid_X445" SG_ 469 HuIcRtcTypeNew 0;
BA_ "GenSigTimeoutTime_HU_High_X445" SG_ 469 HuIcRtcTypeNew 0;
BA_ "GenSigTimeoutTime_HU_Mid_X445" SG_ 469 HuIcRtcTypeNew 0;
BA_ "GenSigTimeoutMsg_IVI" SG_ 469 HuIcRtcTypeNew 0;
BA_ "GenSigTimeoutTime_IVI" SG_ 469 HuIcRtcTypeNew 0;
BA_ "GenSigTimeoutTime_HU_Mid_X451" SG_ 469 HuIcHourInfo 0;
BA_ "GenSigTimeoutTime_HU_High_X451" SG_ 469 HuIcHourInfo 0;
BA_ "GenSigTimeoutTime_HU_B" SG_ 469 HuIcHourInfo 0;
BA_ "GenSigTimeoutTime_HU_A" SG_ 469 HuIcHourInfo 0;
BA_ "GenSigTimeoutMsg_HU_Mid_X451" SG_ 469 HuIcHourInfo 0;
BA_ "GenSigTimeoutMsg_HU_High_X451" SG_ 469 HuIcHourInfo 0;
BA_ "GenSigTimeoutMsg_HU_B" SG_ 469 HuIcHourInfo 0;
BA_ "GenSigTimeoutMsg_HU_A" SG_ 469 HuIcHourInfo 0;
BA_ "GenSigSendType" SG_ 469 HuIcHourInfo 1;
BA_ "GenSigTimeoutMsg_HU_High_X445" SG_ 469 HuIcHourInfo 0;
BA_ "GenSigTimeoutMsg_HU_Mid_X445" SG_ 469 HuIcHourInfo 0;
BA_ "GenSigTimeoutTime_HU_High_X445" SG_ 469 HuIcHourInfo 0;
BA_ "GenSigTimeoutTime_HU_Mid_X445" SG_ 469 HuIcHourInfo 0;
BA_ "GenSigTimeoutMsg_IVI" SG_ 469 HuIcHourInfo 0;
BA_ "GenSigTimeoutTime_IVI" SG_ 469 HuIcHourInfo 0;
BA_ "GenSigTimeoutTime_HU_Mid_X451" SG_ 469 HuIcDateInfo 0;
BA_ "GenSigTimeoutTime_HU_High_X451" SG_ 469 HuIcDateInfo 0;
BA_ "GenSigTimeoutTime_HU_B" SG_ 469 HuIcDateInfo 0;
BA_ "GenSigTimeoutTime_HU_A" SG_ 469 HuIcDateInfo 0;
BA_ "GenSigTimeoutMsg_HU_Mid_X451" SG_ 469 HuIcDateInfo 0;
BA_ "GenSigTimeoutMsg_HU_High_X451" SG_ 469 HuIcDateInfo 0;
BA_ "GenSigTimeoutMsg_HU_B" SG_ 469 HuIcDateInfo 0;
BA_ "GenSigTimeoutMsg_HU_A" SG_ 469 HuIcDateInfo 0;
BA_ "GenSigSendType" SG_ 469 HuIcDateInfo 1;
BA_ "GenSigTimeoutMsg_HU_High_X445" SG_ 469 HuIcDateInfo 0;
BA_ "GenSigTimeoutMsg_HU_Mid_X445" SG_ 469 HuIcDateInfo 0;
BA_ "GenSigTimeoutTime_HU_High_X445" SG_ 469 HuIcDateInfo 0;
BA_ "GenSigTimeoutTime_HU_Mid_X445" SG_ 469 HuIcDateInfo 0;
BA_ "GenSigTimeoutMsg_IVI" SG_ 469 HuIcDateInfo 0;
BA_ "GenSigTimeoutTime_IVI" SG_ 469 HuIcDateInfo 0;
BA_ "GenSigTimeoutTime_HU_Mid_X451" SG_ 469 HuIcYearInfo 0;
BA_ "GenSigTimeoutTime_HU_High_X451" SG_ 469 HuIcYearInfo 0;
BA_ "GenSigTimeoutTime_HU_B" SG_ 469 HuIcYearInfo 0;
BA_ "GenSigTimeoutTime_HU_A" SG_ 469 HuIcYearInfo 0;
BA_ "GenSigTimeoutMsg_HU_Mid_X451" SG_ 469 HuIcYearInfo 0;
BA_ "GenSigTimeoutMsg_HU_High_X451" SG_ 469 HuIcYearInfo 0;
BA_ "GenSigTimeoutMsg_HU_B" SG_ 469 HuIcYearInfo 0;
BA_ "GenSigTimeoutMsg_HU_A" SG_ 469 HuIcYearInfo 0;
BA_ "GenSigSendType" SG_ 469 HuIcYearInfo 1;
BA_ "GenSigTimeoutMsg_HU_High_X445" SG_ 469 HuIcYearInfo 0;
BA_ "GenSigTimeoutMsg_HU_Mid_X445" SG_ 469 HuIcYearInfo 0;
BA_ "GenSigTimeoutTime_HU_High_X445" SG_ 469 HuIcYearInfo 0;
BA_ "GenSigTimeoutTime_HU_Mid_X445" SG_ 469 HuIcYearInfo 0;
BA_ "GenSigTimeoutMsg_IVI" SG_ 469 HuIcYearInfo 0;
BA_ "GenSigTimeoutTime_IVI" SG_ 469 HuIcYearInfo 0;
BA_ "GenSigTimeoutTime_HU_Mid_X451" SG_ 469 HuIcMonthInfo 0;
BA_ "GenSigTimeoutTime_HU_High_X451" SG_ 469 HuIcMonthInfo 0;
BA_ "GenSigTimeoutTime_HU_B" SG_ 469 HuIcMonthInfo 0;
BA_ "GenSigTimeoutTime_HU_A" SG_ 469 HuIcMonthInfo 0;
BA_ "GenSigTimeoutMsg_HU_Mid_X451" SG_ 469 HuIcMonthInfo 0;
BA_ "GenSigTimeoutMsg_HU_High_X451" SG_ 469 HuIcMonthInfo 0;
BA_ "GenSigTimeoutMsg_HU_B" SG_ 469 HuIcMonthInfo 0;
BA_ "GenSigTimeoutMsg_HU_A" SG_ 469 HuIcMonthInfo 0;
BA_ "GenSigSendType" SG_ 469 HuIcMonthInfo 1;
BA_ "GenSigTimeoutMsg_HU_High_X445" SG_ 469 HuIcMonthInfo 0;
BA_ "GenSigTimeoutMsg_HU_Mid_X445" SG_ 469 HuIcMonthInfo 0;
BA_ "GenSigTimeoutTime_HU_High_X445" SG_ 469 HuIcMonthInfo 0;
BA_ "GenSigTimeoutTime_HU_Mid_X445" SG_ 469 HuIcMonthInfo 0;
BA_ "GenSigTimeoutMsg_IVI" SG_ 469 HuIcMonthInfo 0;
BA_ "GenSigTimeoutTime_IVI" SG_ 469 HuIcMonthInfo 0;
BA_ "GenSigTimeoutTime_HU_Mid_X451" SG_ 469 HuIcMilliSecondInfo 0;
BA_ "GenSigTimeoutTime_HU_High_X451" SG_ 469 HuIcMilliSecondInfo 0;
BA_ "GenSigTimeoutTime_HU_B" SG_ 469 HuIcMilliSecondInfo 0;
BA_ "GenSigTimeoutTime_HU_A" SG_ 469 HuIcMilliSecondInfo 0;
BA_ "GenSigTimeoutMsg_HU_Mid_X451" SG_ 469 HuIcMilliSecondInfo 0;
BA_ "GenSigTimeoutMsg_HU_High_X451" SG_ 469 HuIcMilliSecondInfo 0;
BA_ "GenSigTimeoutMsg_HU_B" SG_ 469 HuIcMilliSecondInfo 0;
BA_ "GenSigTimeoutMsg_HU_A" SG_ 469 HuIcMilliSecondInfo 0;
BA_ "GenSigSendType" SG_ 469 HuIcMilliSecondInfo 1;
BA_ "GenSigTimeoutMsg_HU_High_X445" SG_ 469 HuIcMilliSecondInfo 0;
BA_ "GenSigTimeoutMsg_HU_Mid_X445" SG_ 469 HuIcMilliSecondInfo 0;
BA_ "GenSigTimeoutTime_HU_High_X445" SG_ 469 HuIcMilliSecondInfo 0;
BA_ "GenSigTimeoutTime_HU_Mid_X445" SG_ 469 HuIcMilliSecondInfo 0;
BA_ "GenSigTimeoutMsg_IVI" SG_ 469 HuIcMilliSecondInfo 0;
BA_ "GenSigTimeoutTime_IVI" SG_ 469 HuIcMilliSecondInfo 0;
BA_ "GenSigTimeoutTime_HU_Mid_X451" SG_ 469 HuLangSettings 0;
BA_ "GenSigTimeoutTime_HU_High_X451" SG_ 469 HuLangSettings 0;
BA_ "GenSigTimeoutTime_HU_B" SG_ 469 HuLangSettings 0;
BA_ "GenSigTimeoutTime_HU_A" SG_ 469 HuLangSettings 0;
BA_ "GenSigTimeoutMsg_HU_Mid_X451" SG_ 469 HuLangSettings 0;
BA_ "GenSigTimeoutMsg_HU_High_X451" SG_ 469 HuLangSettings 0;
BA_ "GenSigTimeoutMsg_HU_B" SG_ 469 HuLangSettings 0;
BA_ "GenSigTimeoutMsg_HU_A" SG_ 469 HuLangSettings 0;
BA_ "GenSigSendType" SG_ 469 HuLangSettings 1;
BA_ "GenSigTimeoutMsg_HU_High_X445" SG_ 469 HuLangSettings 0;
BA_ "GenSigTimeoutMsg_HU_Mid_X445" SG_ 469 HuLangSettings 0;
BA_ "GenSigTimeoutTime_HU_High_X445" SG_ 469 HuLangSettings 0;
BA_ "GenSigTimeoutTime_HU_Mid_X445" SG_ 469 HuLangSettings 0;
BA_ "GenSigTimeoutMsg_IVI" SG_ 469 HuLangSettings 0;
BA_ "GenSigTimeoutTime_IVI" SG_ 469 HuLangSettings 0;
BA_ "GenSigTimeoutTime_HU_Mid_X451" SG_ 469 HuIcRtcType 0;
BA_ "GenSigTimeoutTime_HU_High_X451" SG_ 469 HuIcRtcType 0;
BA_ "GenSigTimeoutTime_HU_B" SG_ 469 HuIcRtcType 0;
BA_ "GenSigTimeoutTime_HU_A" SG_ 469 HuIcRtcType 0;
BA_ "GenSigTimeoutMsg_HU_Mid_X451" SG_ 469 HuIcRtcType 0;
BA_ "GenSigTimeoutMsg_HU_High_X451" SG_ 469 HuIcRtcType 0;
BA_ "GenSigTimeoutMsg_HU_B" SG_ 469 HuIcRtcType 0;
BA_ "GenSigTimeoutMsg_HU_A" SG_ 469 HuIcRtcType 0;
BA_ "GenSigSendType" SG_ 469 HuIcRtcType 1;
BA_ "GenSigTimeoutMsg_HU_High_X445" SG_ 469 HuIcRtcType 0;
BA_ "GenSigTimeoutMsg_HU_Mid_X445" SG_ 469 HuIcRtcType 0;
BA_ "GenSigTimeoutTime_HU_High_X445" SG_ 469 HuIcRtcType 0;
BA_ "GenSigTimeoutTime_HU_Mid_X445" SG_ 469 HuIcRtcType 0;
BA_ "GenSigTimeoutMsg_IVI" SG_ 469 HuIcRtcType 0;
BA_ "GenSigTimeoutTime_IVI" SG_ 469 HuIcRtcType 0;
BA_ "GenSigTimeoutTime_HU_Mid_X451" SG_ 470 HuIcTempUnitSetAck 0;
BA_ "GenSigTimeoutTime_HU_High_X451" SG_ 470 HuIcTempUnitSetAck 0;
BA_ "GenSigTimeoutTime_HU_B" SG_ 470 HuIcTempUnitSetAck 0;
BA_ "GenSigTimeoutTime_HU_A" SG_ 470 HuIcTempUnitSetAck 0;
BA_ "GenSigTimeoutMsg_HU_Mid_X451" SG_ 470 HuIcTempUnitSetAck 0;
BA_ "GenSigTimeoutMsg_HU_High_X451" SG_ 470 HuIcTempUnitSetAck 0;
BA_ "GenSigTimeoutMsg_HU_B" SG_ 470 HuIcTempUnitSetAck 0;
BA_ "GenSigTimeoutMsg_HU_A" SG_ 470 HuIcTempUnitSetAck 0;
BA_ "GenSigSendType" SG_ 470 HuIcTempUnitSetAck 1;
BA_ "GenSigTimeoutMsg_HU_High_X445" SG_ 470 HuIcTempUnitSetAck 0;
BA_ "GenSigTimeoutMsg_HU_Mid_X445" SG_ 470 HuIcTempUnitSetAck 0;
BA_ "GenSigTimeoutTime_HU_High_X445" SG_ 470 HuIcTempUnitSetAck 0;
BA_ "GenSigTimeoutTime_HU_Mid_X445" SG_ 470 HuIcTempUnitSetAck 0;
BA_ "GenSigTimeoutMsg_IVI" SG_ 470 HuIcTempUnitSetAck 0;
BA_ "GenSigTimeoutTime_IVI" SG_ 470 HuIcTempUnitSetAck 0;
BA_ "GenSigTimeoutTime_HU_Mid_X451" SG_ 470 HuIcFuelUnitSetAck 0;
BA_ "GenSigTimeoutTime_HU_High_X451" SG_ 470 HuIcFuelUnitSetAck 0;
BA_ "GenSigTimeoutTime_HU_B" SG_ 470 HuIcFuelUnitSetAck 0;
BA_ "GenSigTimeoutTime_HU_A" SG_ 470 HuIcFuelUnitSetAck 0;
BA_ "GenSigTimeoutMsg_HU_Mid_X451" SG_ 470 HuIcFuelUnitSetAck 0;
BA_ "GenSigTimeoutMsg_HU_High_X451" SG_ 470 HuIcFuelUnitSetAck 0;
BA_ "GenSigTimeoutMsg_HU_B" SG_ 470 HuIcFuelUnitSetAck 0;
BA_ "GenSigTimeoutMsg_HU_A" SG_ 470 HuIcFuelUnitSetAck 0;
BA_ "GenSigSendType" SG_ 470 HuIcFuelUnitSetAck 1;
BA_ "GenSigTimeoutMsg_HU_High_X445" SG_ 470 HuIcFuelUnitSetAck 0;
BA_ "GenSigTimeoutMsg_HU_Mid_X445" SG_ 470 HuIcFuelUnitSetAck 0;
BA_ "GenSigTimeoutTime_HU_High_X445" SG_ 470 HuIcFuelUnitSetAck 0;
BA_ "GenSigTimeoutTime_HU_Mid_X445" SG_ 470 HuIcFuelUnitSetAck 0;
BA_ "GenSigTimeoutMsg_IVI" SG_ 470 HuIcFuelUnitSetAck 0;
BA_ "GenSigTimeoutTime_IVI" SG_ 470 HuIcFuelUnitSetAck 0;
BA_ "GenSigTimeoutTime_HU_Mid_X451" SG_ 470 HuIcDistUnitSetAck 0;
BA_ "GenSigTimeoutTime_HU_High_X451" SG_ 470 HuIcDistUnitSetAck 0;
BA_ "GenSigTimeoutTime_HU_B" SG_ 470 HuIcDistUnitSetAck 0;
BA_ "GenSigTimeoutTime_HU_A" SG_ 470 HuIcDistUnitSetAck 0;
BA_ "GenSigTimeoutMsg_HU_Mid_X451" SG_ 470 HuIcDistUnitSetAck 0;
BA_ "GenSigTimeoutMsg_HU_High_X451" SG_ 470 HuIcDistUnitSetAck 0;
BA_ "GenSigTimeoutMsg_HU_B" SG_ 470 HuIcDistUnitSetAck 0;
BA_ "GenSigTimeoutMsg_HU_A" SG_ 470 HuIcDistUnitSetAck 0;
BA_ "GenSigSendType" SG_ 470 HuIcDistUnitSetAck 1;
BA_ "GenSigTimeoutMsg_HU_High_X445" SG_ 470 HuIcDistUnitSetAck 0;
BA_ "GenSigTimeoutMsg_HU_Mid_X445" SG_ 470 HuIcDistUnitSetAck 0;
BA_ "GenSigTimeoutTime_HU_High_X445" SG_ 470 HuIcDistUnitSetAck 0;
BA_ "GenSigTimeoutTime_HU_Mid_X445" SG_ 470 HuIcDistUnitSetAck 0;
BA_ "GenSigTimeoutMsg_IVI" SG_ 470 HuIcDistUnitSetAck 0;
BA_ "GenSigTimeoutTime_IVI" SG_ 470 HuIcDistUnitSetAck 0;
BA_ "GenSigTimeoutTime_HU_Mid_X451" SG_ 472 CcmHuAutoConfig 0;
BA_ "GenSigTimeoutTime_HU_High_X451" SG_ 472 CcmHuAutoConfig 0;
BA_ "GenSigTimeoutTime_HU_B" SG_ 472 CcmHuAutoConfig 0;
BA_ "GenSigTimeoutTime_HU_A" SG_ 472 CcmHuAutoConfig 0;
BA_ "GenSigTimeoutMsg_HU_Mid_X451" SG_ 472 CcmHuAutoConfig 0;
BA_ "GenSigTimeoutMsg_HU_High_X451" SG_ 472 CcmHuAutoConfig 0;
BA_ "GenSigTimeoutMsg_HU_B" SG_ 472 CcmHuAutoConfig 0;
BA_ "GenSigTimeoutMsg_HU_A" SG_ 472 CcmHuAutoConfig 0;
BA_ "GenSigSendType" SG_ 472 CcmHuAutoConfig 1;
BA_ "GenSigTimeoutMsg_HU_High_X445" SG_ 472 CcmHuAutoConfig 0;
BA_ "GenSigTimeoutMsg_HU_Mid_X445" SG_ 472 CcmHuAutoConfig 0;
BA_ "GenSigTimeoutTime_HU_High_X445" SG_ 472 CcmHuAutoConfig 0;
BA_ "GenSigTimeoutTime_HU_Mid_X445" SG_ 472 CcmHuAutoConfig 0;
BA_ "GenSigTimeoutMsg_IVI" SG_ 472 CcmHuAutoConfig 0;
BA_ "GenSigTimeoutTime_IVI" SG_ 472 CcmHuAutoConfig 0;
BA_ "GenSigTimeoutTime_HU_Mid_X451" SG_ 472 CcmHuHvacOffConfig 0;
BA_ "GenSigTimeoutTime_HU_High_X451" SG_ 472 CcmHuHvacOffConfig 0;
BA_ "GenSigTimeoutTime_HU_B" SG_ 472 CcmHuHvacOffConfig 0;
BA_ "GenSigTimeoutTime_HU_A" SG_ 472 CcmHuHvacOffConfig 0;
BA_ "GenSigTimeoutMsg_HU_Mid_X451" SG_ 472 CcmHuHvacOffConfig 0;
BA_ "GenSigTimeoutMsg_HU_High_X451" SG_ 472 CcmHuHvacOffConfig 0;
BA_ "GenSigTimeoutMsg_HU_B" SG_ 472 CcmHuHvacOffConfig 0;
BA_ "GenSigTimeoutMsg_HU_A" SG_ 472 CcmHuHvacOffConfig 0;
BA_ "GenSigSendType" SG_ 472 CcmHuHvacOffConfig 1;
BA_ "GenSigTimeoutMsg_HU_High_X445" SG_ 472 CcmHuHvacOffConfig 0;
BA_ "GenSigTimeoutMsg_HU_Mid_X445" SG_ 472 CcmHuHvacOffConfig 0;
BA_ "GenSigTimeoutTime_HU_High_X445" SG_ 472 CcmHuHvacOffConfig 0;
BA_ "GenSigTimeoutTime_HU_Mid_X445" SG_ 472 CcmHuHvacOffConfig 0;
BA_ "GenSigTimeoutMsg_IVI" SG_ 472 CcmHuHvacOffConfig 0;
BA_ "GenSigTimeoutTime_IVI" SG_ 472 CcmHuHvacOffConfig 0;
BA_ "GenSigTimeoutTime_HU_Mid_X451" SG_ 472 CCmHuRearDefogConfig 0;
BA_ "GenSigTimeoutTime_HU_High_X451" SG_ 472 CCmHuRearDefogConfig 0;
BA_ "GenSigTimeoutTime_HU_B" SG_ 472 CCmHuRearDefogConfig 0;
BA_ "GenSigTimeoutTime_HU_A" SG_ 472 CCmHuRearDefogConfig 0;
BA_ "GenSigTimeoutMsg_HU_Mid_X451" SG_ 472 CCmHuRearDefogConfig 0;
BA_ "GenSigTimeoutMsg_HU_High_X451" SG_ 472 CCmHuRearDefogConfig 0;
BA_ "GenSigTimeoutMsg_HU_B" SG_ 472 CCmHuRearDefogConfig 0;
BA_ "GenSigTimeoutMsg_HU_A" SG_ 472 CCmHuRearDefogConfig 0;
BA_ "GenSigSendType" SG_ 472 CCmHuRearDefogConfig 1;
BA_ "GenSigTimeoutMsg_HU_High_X445" SG_ 472 CCmHuRearDefogConfig 0;
BA_ "GenSigTimeoutMsg_HU_Mid_X445" SG_ 472 CCmHuRearDefogConfig 0;
BA_ "GenSigTimeoutTime_HU_High_X445" SG_ 472 CCmHuRearDefogConfig 0;
BA_ "GenSigTimeoutTime_HU_Mid_X445" SG_ 472 CCmHuRearDefogConfig 0;
BA_ "GenSigTimeoutMsg_IVI" SG_ 472 CCmHuRearDefogConfig 0;
BA_ "GenSigTimeoutTime_IVI" SG_ 472 CCmHuRearDefogConfig 0;
BA_ "GenSigTimeoutTime_HU_Mid_X451" SG_ 472 CCmHuColorThemeConfig 0;
BA_ "GenSigTimeoutTime_HU_High_X451" SG_ 472 CCmHuColorThemeConfig 0;
BA_ "GenSigTimeoutTime_HU_B" SG_ 472 CCmHuColorThemeConfig 0;
BA_ "GenSigTimeoutTime_HU_A" SG_ 472 CCmHuColorThemeConfig 0;
BA_ "GenSigTimeoutMsg_HU_Mid_X451" SG_ 472 CCmHuColorThemeConfig 0;
BA_ "GenSigTimeoutMsg_HU_High_X451" SG_ 472 CCmHuColorThemeConfig 0;
BA_ "GenSigTimeoutMsg_HU_B" SG_ 472 CCmHuColorThemeConfig 0;
BA_ "GenSigTimeoutMsg_HU_A" SG_ 472 CCmHuColorThemeConfig 0;
BA_ "GenSigSendType" SG_ 472 CCmHuColorThemeConfig 1;
BA_ "GenSigTimeoutMsg_HU_High_X445" SG_ 472 CCmHuColorThemeConfig 0;
BA_ "GenSigTimeoutMsg_HU_Mid_X445" SG_ 472 CCmHuColorThemeConfig 0;
BA_ "GenSigTimeoutTime_HU_High_X445" SG_ 472 CCmHuColorThemeConfig 0;
BA_ "GenSigTimeoutTime_HU_Mid_X445" SG_ 472 CCmHuColorThemeConfig 0;
BA_ "GenSigTimeoutMsg_IVI" SG_ 472 CCmHuColorThemeConfig 0;
BA_ "GenSigTimeoutTime_IVI" SG_ 472 CCmHuColorThemeConfig 0;
BA_ "GenSigTimeoutTime_HU_Mid_X451" SG_ 472 CCmHuAutoDefogConfig 0;
BA_ "GenSigTimeoutTime_HU_High_X451" SG_ 472 CCmHuAutoDefogConfig 0;
BA_ "GenSigTimeoutTime_HU_B" SG_ 472 CCmHuAutoDefogConfig 0;
BA_ "GenSigTimeoutTime_HU_A" SG_ 472 CCmHuAutoDefogConfig 0;
BA_ "GenSigTimeoutMsg_HU_Mid_X451" SG_ 472 CCmHuAutoDefogConfig 0;
BA_ "GenSigTimeoutMsg_HU_High_X451" SG_ 472 CCmHuAutoDefogConfig 0;
BA_ "GenSigTimeoutMsg_HU_B" SG_ 472 CCmHuAutoDefogConfig 0;
BA_ "GenSigTimeoutMsg_HU_A" SG_ 472 CCmHuAutoDefogConfig 0;
BA_ "GenSigSendType" SG_ 472 CCmHuAutoDefogConfig 1;
BA_ "GenSigTimeoutMsg_HU_High_X445" SG_ 472 CCmHuAutoDefogConfig 0;
BA_ "GenSigTimeoutMsg_HU_Mid_X445" SG_ 472 CCmHuAutoDefogConfig 0;
BA_ "GenSigTimeoutTime_HU_High_X445" SG_ 472 CCmHuAutoDefogConfig 0;
BA_ "GenSigTimeoutTime_HU_Mid_X445" SG_ 472 CCmHuAutoDefogConfig 0;
BA_ "GenSigTimeoutMsg_IVI" SG_ 472 CCmHuAutoDefogConfig 0;
BA_ "GenSigTimeoutTime_IVI" SG_ 472 CCmHuAutoDefogConfig 0;
BA_ "GenSigTimeoutTime_HU_Mid_X451" SG_ 472 CcmHuRearBlwrConfig 0;
BA_ "GenSigTimeoutTime_HU_High_X451" SG_ 472 CcmHuRearBlwrConfig 0;
BA_ "GenSigTimeoutTime_HU_B" SG_ 472 CcmHuRearBlwrConfig 0;
BA_ "GenSigTimeoutTime_HU_A" SG_ 472 CcmHuRearBlwrConfig 0;
BA_ "GenSigTimeoutMsg_HU_Mid_X451" SG_ 472 CcmHuRearBlwrConfig 0;
BA_ "GenSigTimeoutMsg_HU_High_X451" SG_ 472 CcmHuRearBlwrConfig 0;
BA_ "GenSigTimeoutMsg_HU_B" SG_ 472 CcmHuRearBlwrConfig 0;
BA_ "GenSigTimeoutMsg_HU_A" SG_ 472 CcmHuRearBlwrConfig 0;
BA_ "GenSigSendType" SG_ 472 CcmHuRearBlwrConfig 1;
BA_ "GenSigTimeoutMsg_HU_High_X445" SG_ 472 CcmHuRearBlwrConfig 0;
BA_ "GenSigTimeoutMsg_HU_Mid_X445" SG_ 472 CcmHuRearBlwrConfig 0;
BA_ "GenSigTimeoutTime_HU_High_X445" SG_ 472 CcmHuRearBlwrConfig 0;
BA_ "GenSigTimeoutTime_HU_Mid_X445" SG_ 472 CcmHuRearBlwrConfig 0;
BA_ "GenSigTimeoutMsg_IVI" SG_ 472 CcmHuRearBlwrConfig 0;
BA_ "GenSigTimeoutTime_IVI" SG_ 472 CcmHuRearBlwrConfig 0;
BA_ "GenSigTimeoutTime_HU_Mid_X451" SG_ 472 CCmHuEconConfig 0;
BA_ "GenSigTimeoutTime_HU_High_X451" SG_ 472 CCmHuEconConfig 0;
BA_ "GenSigTimeoutTime_HU_B" SG_ 472 CCmHuEconConfig 0;
BA_ "GenSigTimeoutTime_HU_A" SG_ 472 CCmHuEconConfig 0;
BA_ "GenSigTimeoutMsg_HU_Mid_X451" SG_ 472 CCmHuEconConfig 0;
BA_ "GenSigTimeoutMsg_HU_High_X451" SG_ 472 CCmHuEconConfig 0;
BA_ "GenSigTimeoutMsg_HU_B" SG_ 472 CCmHuEconConfig 0;
BA_ "GenSigTimeoutMsg_HU_A" SG_ 472 CCmHuEconConfig 0;
BA_ "GenSigSendType" SG_ 472 CCmHuEconConfig 1;
BA_ "GenSigTimeoutMsg_HU_High_X445" SG_ 472 CCmHuEconConfig 0;
BA_ "GenSigTimeoutMsg_HU_Mid_X445" SG_ 472 CCmHuEconConfig 0;
BA_ "GenSigTimeoutTime_HU_High_X445" SG_ 472 CCmHuEconConfig 0;
BA_ "GenSigTimeoutTime_HU_Mid_X445" SG_ 472 CCmHuEconConfig 0;
BA_ "GenSigTimeoutMsg_IVI" SG_ 472 CCmHuEconConfig 0;
BA_ "GenSigTimeoutTime_IVI" SG_ 472 CCmHuEconConfig 0;
BA_ "GenSigTimeoutTime_HU_Mid_X451" SG_ 472 CCmHuExpressCoolConfig 0;
BA_ "GenSigTimeoutTime_HU_High_X451" SG_ 472 CCmHuExpressCoolConfig 0;
BA_ "GenSigTimeoutTime_HU_B" SG_ 472 CCmHuExpressCoolConfig 0;
BA_ "GenSigTimeoutTime_HU_A" SG_ 472 CCmHuExpressCoolConfig 0;
BA_ "GenSigTimeoutMsg_HU_Mid_X451" SG_ 472 CCmHuExpressCoolConfig 0;
BA_ "GenSigTimeoutMsg_HU_High_X451" SG_ 472 CCmHuExpressCoolConfig 0;
BA_ "GenSigTimeoutMsg_HU_B" SG_ 472 CCmHuExpressCoolConfig 0;
BA_ "GenSigTimeoutMsg_HU_A" SG_ 472 CCmHuExpressCoolConfig 0;
BA_ "GenSigSendType" SG_ 472 CCmHuExpressCoolConfig 1;
BA_ "GenSigTimeoutMsg_HU_High_X445" SG_ 472 CCmHuExpressCoolConfig 0;
BA_ "GenSigTimeoutMsg_HU_Mid_X445" SG_ 472 CCmHuExpressCoolConfig 0;
BA_ "GenSigTimeoutTime_HU_High_X445" SG_ 472 CCmHuExpressCoolConfig 0;
BA_ "GenSigTimeoutTime_HU_Mid_X445" SG_ 472 CCmHuExpressCoolConfig 0;
BA_ "GenSigTimeoutMsg_IVI" SG_ 472 CCmHuExpressCoolConfig 0;
BA_ "GenSigTimeoutTime_IVI" SG_ 472 CCmHuExpressCoolConfig 0;
BA_ "GenSigTimeoutTime_HU_Mid_X451" SG_ 472 CCmHuLowFanSpdConfigValue 0;
BA_ "GenSigTimeoutTime_HU_High_X451" SG_ 472 CCmHuLowFanSpdConfigValue 0;
BA_ "GenSigTimeoutTime_HU_B" SG_ 472 CCmHuLowFanSpdConfigValue 0;
BA_ "GenSigTimeoutTime_HU_A" SG_ 472 CCmHuLowFanSpdConfigValue 0;
BA_ "GenSigTimeoutMsg_HU_Mid_X451" SG_ 472 CCmHuLowFanSpdConfigValue 0;
BA_ "GenSigTimeoutMsg_HU_High_X451" SG_ 472 CCmHuLowFanSpdConfigValue 0;
BA_ "GenSigTimeoutMsg_HU_B" SG_ 472 CCmHuLowFanSpdConfigValue 0;
BA_ "GenSigTimeoutMsg_HU_A" SG_ 472 CCmHuLowFanSpdConfigValue 0;
BA_ "GenSigSendType" SG_ 472 CCmHuLowFanSpdConfigValue 1;
BA_ "GenSigTimeoutMsg_HU_High_X445" SG_ 472 CCmHuLowFanSpdConfigValue 0;
BA_ "GenSigTimeoutMsg_HU_Mid_X445" SG_ 472 CCmHuLowFanSpdConfigValue 0;
BA_ "GenSigTimeoutTime_HU_High_X445" SG_ 472 CCmHuLowFanSpdConfigValue 0;
BA_ "GenSigTimeoutTime_HU_Mid_X445" SG_ 472 CCmHuLowFanSpdConfigValue 0;
BA_ "GenSigTimeoutMsg_IVI" SG_ 472 CCmHuLowFanSpdConfigValue 0;
BA_ "GenSigTimeoutTime_IVI" SG_ 472 CCmHuLowFanSpdConfigValue 0;
BA_ "GenSigTimeoutTime_HU_Mid_X451" SG_ 472 CCmHuHiFanSpdConfigValue 0;
BA_ "GenSigTimeoutTime_HU_High_X451" SG_ 472 CCmHuHiFanSpdConfigValue 0;
BA_ "GenSigTimeoutTime_HU_B" SG_ 472 CCmHuHiFanSpdConfigValue 0;
BA_ "GenSigTimeoutTime_HU_A" SG_ 472 CCmHuHiFanSpdConfigValue 0;
BA_ "GenSigTimeoutMsg_HU_Mid_X451" SG_ 472 CCmHuHiFanSpdConfigValue 0;
BA_ "GenSigTimeoutMsg_HU_High_X451" SG_ 472 CCmHuHiFanSpdConfigValue 0;
BA_ "GenSigTimeoutMsg_HU_B" SG_ 472 CCmHuHiFanSpdConfigValue 0;
BA_ "GenSigTimeoutMsg_HU_A" SG_ 472 CCmHuHiFanSpdConfigValue 0;
BA_ "GenSigSendType" SG_ 472 CCmHuHiFanSpdConfigValue 1;
BA_ "GenSigTimeoutMsg_HU_High_X445" SG_ 472 CCmHuHiFanSpdConfigValue 0;
BA_ "GenSigTimeoutMsg_HU_Mid_X445" SG_ 472 CCmHuHiFanSpdConfigValue 0;
BA_ "GenSigTimeoutTime_HU_High_X445" SG_ 472 CCmHuHiFanSpdConfigValue 0;
BA_ "GenSigTimeoutTime_HU_Mid_X445" SG_ 472 CCmHuHiFanSpdConfigValue 0;
BA_ "GenSigTimeoutMsg_IVI" SG_ 472 CCmHuHiFanSpdConfigValue 0;
BA_ "GenSigTimeoutTime_IVI" SG_ 472 CCmHuHiFanSpdConfigValue 0;
BA_ "GenSigTimeoutTime_HU_Mid_X451" SG_ 472 CCmHuLowTempConfigValue 0;
BA_ "GenSigTimeoutTime_HU_High_X451" SG_ 472 CCmHuLowTempConfigValue 0;
BA_ "GenSigTimeoutTime_HU_B" SG_ 472 CCmHuLowTempConfigValue 0;
BA_ "GenSigTimeoutTime_HU_A" SG_ 472 CCmHuLowTempConfigValue 0;
BA_ "GenSigTimeoutMsg_HU_Mid_X451" SG_ 472 CCmHuLowTempConfigValue 0;
BA_ "GenSigTimeoutMsg_HU_High_X451" SG_ 472 CCmHuLowTempConfigValue 0;
BA_ "GenSigTimeoutMsg_HU_B" SG_ 472 CCmHuLowTempConfigValue 0;
BA_ "GenSigTimeoutMsg_HU_A" SG_ 472 CCmHuLowTempConfigValue 0;
BA_ "GenSigSendType" SG_ 472 CCmHuLowTempConfigValue 1;
BA_ "GenSigTimeoutMsg_HU_High_X445" SG_ 472 CCmHuLowTempConfigValue 0;
BA_ "GenSigTimeoutMsg_HU_Mid_X445" SG_ 472 CCmHuLowTempConfigValue 0;
BA_ "GenSigTimeoutTime_HU_High_X445" SG_ 472 CCmHuLowTempConfigValue 0;
BA_ "GenSigTimeoutTime_HU_Mid_X445" SG_ 472 CCmHuLowTempConfigValue 0;
BA_ "GenSigTimeoutMsg_IVI" SG_ 472 CCmHuLowTempConfigValue 0;
BA_ "GenSigTimeoutTime_IVI" SG_ 472 CCmHuLowTempConfigValue 0;
BA_ "GenSigTimeoutTime_HU_Mid_X451" SG_ 472 CCmHuHiTempConfigValue 0;
BA_ "GenSigTimeoutTime_HU_High_X451" SG_ 472 CCmHuHiTempConfigValue 0;
BA_ "GenSigTimeoutTime_HU_B" SG_ 472 CCmHuHiTempConfigValue 0;
BA_ "GenSigTimeoutTime_HU_A" SG_ 472 CCmHuHiTempConfigValue 0;
BA_ "GenSigTimeoutMsg_HU_Mid_X451" SG_ 472 CCmHuHiTempConfigValue 0;
BA_ "GenSigTimeoutMsg_HU_High_X451" SG_ 472 CCmHuHiTempConfigValue 0;
BA_ "GenSigTimeoutMsg_HU_B" SG_ 472 CCmHuHiTempConfigValue 0;
BA_ "GenSigTimeoutMsg_HU_A" SG_ 472 CCmHuHiTempConfigValue 0;
BA_ "GenSigSendType" SG_ 472 CCmHuHiTempConfigValue 1;
BA_ "GenSigTimeoutMsg_HU_High_X445" SG_ 472 CCmHuHiTempConfigValue 0;
BA_ "GenSigTimeoutMsg_HU_Mid_X445" SG_ 472 CCmHuHiTempConfigValue 0;
BA_ "GenSigTimeoutTime_HU_High_X445" SG_ 472 CCmHuHiTempConfigValue 0;
BA_ "GenSigTimeoutTime_HU_Mid_X445" SG_ 472 CCmHuHiTempConfigValue 0;
BA_ "GenSigTimeoutMsg_IVI" SG_ 472 CCmHuHiTempConfigValue 0;
BA_ "GenSigTimeoutTime_IVI" SG_ 472 CCmHuHiTempConfigValue 0;
BA_ "GenSigTimeoutTime_HU_Mid_X451" SG_ 474 HuCcmAutoConfigAck 0;
BA_ "GenSigTimeoutTime_HU_High_X451" SG_ 474 HuCcmAutoConfigAck 0;
BA_ "GenSigTimeoutTime_HU_B" SG_ 474 HuCcmAutoConfigAck 0;
BA_ "GenSigTimeoutTime_HU_A" SG_ 474 HuCcmAutoConfigAck 0;
BA_ "GenSigTimeoutMsg_HU_Mid_X451" SG_ 474 HuCcmAutoConfigAck 0;
BA_ "GenSigTimeoutMsg_HU_High_X451" SG_ 474 HuCcmAutoConfigAck 0;
BA_ "GenSigTimeoutMsg_HU_B" SG_ 474 HuCcmAutoConfigAck 0;
BA_ "GenSigTimeoutMsg_HU_A" SG_ 474 HuCcmAutoConfigAck 0;
BA_ "GenSigSendType" SG_ 474 HuCcmAutoConfigAck 1;
BA_ "GenSigTimeoutMsg_HU_High_X445" SG_ 474 HuCcmAutoConfigAck 0;
BA_ "GenSigTimeoutMsg_HU_Mid_X445" SG_ 474 HuCcmAutoConfigAck 0;
BA_ "GenSigTimeoutTime_HU_High_X445" SG_ 474 HuCcmAutoConfigAck 0;
BA_ "GenSigTimeoutTime_HU_Mid_X445" SG_ 474 HuCcmAutoConfigAck 0;
BA_ "GenSigTimeoutMsg_IVI" SG_ 474 HuCcmAutoConfigAck 0;
BA_ "GenSigTimeoutTime_IVI" SG_ 474 HuCcmAutoConfigAck 0;
BA_ "GenSigTimeoutTime_HU_Mid_X451" SG_ 474 HuCcmHvacOffConfigAck 0;
BA_ "GenSigTimeoutTime_HU_High_X451" SG_ 474 HuCcmHvacOffConfigAck 0;
BA_ "GenSigTimeoutTime_HU_B" SG_ 474 HuCcmHvacOffConfigAck 0;
BA_ "GenSigTimeoutTime_HU_A" SG_ 474 HuCcmHvacOffConfigAck 0;
BA_ "GenSigTimeoutMsg_HU_Mid_X451" SG_ 474 HuCcmHvacOffConfigAck 0;
BA_ "GenSigTimeoutMsg_HU_High_X451" SG_ 474 HuCcmHvacOffConfigAck 0;
BA_ "GenSigTimeoutMsg_HU_B" SG_ 474 HuCcmHvacOffConfigAck 0;
BA_ "GenSigTimeoutMsg_HU_A" SG_ 474 HuCcmHvacOffConfigAck 0;
BA_ "GenSigSendType" SG_ 474 HuCcmHvacOffConfigAck 1;
BA_ "GenSigTimeoutMsg_HU_High_X445" SG_ 474 HuCcmHvacOffConfigAck 0;
BA_ "GenSigTimeoutMsg_HU_Mid_X445" SG_ 474 HuCcmHvacOffConfigAck 0;
BA_ "GenSigTimeoutTime_HU_High_X445" SG_ 474 HuCcmHvacOffConfigAck 0;
BA_ "GenSigTimeoutTime_HU_Mid_X445" SG_ 474 HuCcmHvacOffConfigAck 0;
BA_ "GenSigTimeoutMsg_IVI" SG_ 474 HuCcmHvacOffConfigAck 0;
BA_ "GenSigTimeoutTime_IVI" SG_ 474 HuCcmHvacOffConfigAck 0;
BA_ "GenSigTimeoutTime_HU_Mid_X451" SG_ 474 HuCcmAutoDefogConfigAck 0;
BA_ "GenSigTimeoutTime_HU_High_X451" SG_ 474 HuCcmAutoDefogConfigAck 0;
BA_ "GenSigTimeoutTime_HU_B" SG_ 474 HuCcmAutoDefogConfigAck 0;
BA_ "GenSigTimeoutTime_HU_A" SG_ 474 HuCcmAutoDefogConfigAck 0;
BA_ "GenSigTimeoutMsg_HU_Mid_X451" SG_ 474 HuCcmAutoDefogConfigAck 0;
BA_ "GenSigTimeoutMsg_HU_High_X451" SG_ 474 HuCcmAutoDefogConfigAck 0;
BA_ "GenSigTimeoutMsg_HU_B" SG_ 474 HuCcmAutoDefogConfigAck 0;
BA_ "GenSigTimeoutMsg_HU_A" SG_ 474 HuCcmAutoDefogConfigAck 0;
BA_ "GenSigSendType" SG_ 474 HuCcmAutoDefogConfigAck 1;
BA_ "GenSigTimeoutMsg_HU_High_X445" SG_ 474 HuCcmAutoDefogConfigAck 0;
BA_ "GenSigTimeoutMsg_HU_Mid_X445" SG_ 474 HuCcmAutoDefogConfigAck 0;
BA_ "GenSigTimeoutTime_HU_High_X445" SG_ 474 HuCcmAutoDefogConfigAck 0;
BA_ "GenSigTimeoutTime_HU_Mid_X445" SG_ 474 HuCcmAutoDefogConfigAck 0;
BA_ "GenSigTimeoutMsg_IVI" SG_ 474 HuCcmAutoDefogConfigAck 0;
BA_ "GenSigTimeoutTime_IVI" SG_ 474 HuCcmAutoDefogConfigAck 0;
BA_ "GenSigTimeoutTime_HU_Mid_X451" SG_ 474 HuCcmColorThemeConfigAck 0;
BA_ "GenSigTimeoutTime_HU_High_X451" SG_ 474 HuCcmColorThemeConfigAck 0;
BA_ "GenSigTimeoutTime_HU_B" SG_ 474 HuCcmColorThemeConfigAck 0;
BA_ "GenSigTimeoutTime_HU_A" SG_ 474 HuCcmColorThemeConfigAck 0;
BA_ "GenSigTimeoutMsg_HU_Mid_X451" SG_ 474 HuCcmColorThemeConfigAck 0;
BA_ "GenSigTimeoutMsg_HU_High_X451" SG_ 474 HuCcmColorThemeConfigAck 0;
BA_ "GenSigTimeoutMsg_HU_B" SG_ 474 HuCcmColorThemeConfigAck 0;
BA_ "GenSigTimeoutMsg_HU_A" SG_ 474 HuCcmColorThemeConfigAck 0;
BA_ "GenSigSendType" SG_ 474 HuCcmColorThemeConfigAck 1;
BA_ "GenSigTimeoutMsg_HU_High_X445" SG_ 474 HuCcmColorThemeConfigAck 0;
BA_ "GenSigTimeoutMsg_HU_Mid_X445" SG_ 474 HuCcmColorThemeConfigAck 0;
BA_ "GenSigTimeoutTime_HU_High_X445" SG_ 474 HuCcmColorThemeConfigAck 0;
BA_ "GenSigTimeoutTime_HU_Mid_X445" SG_ 474 HuCcmColorThemeConfigAck 0;
BA_ "GenSigTimeoutMsg_IVI" SG_ 474 HuCcmColorThemeConfigAck 0;
BA_ "GenSigTimeoutTime_IVI" SG_ 474 HuCcmColorThemeConfigAck 0;
BA_ "GenSigTimeoutTime_HU_Mid_X451" SG_ 474 HuCcmRearDefogConfigAck 0;
BA_ "GenSigTimeoutTime_HU_High_X451" SG_ 474 HuCcmRearDefogConfigAck 0;
BA_ "GenSigTimeoutTime_HU_B" SG_ 474 HuCcmRearDefogConfigAck 0;
BA_ "GenSigTimeoutTime_HU_A" SG_ 474 HuCcmRearDefogConfigAck 0;
BA_ "GenSigTimeoutMsg_HU_Mid_X451" SG_ 474 HuCcmRearDefogConfigAck 0;
BA_ "GenSigTimeoutMsg_HU_High_X451" SG_ 474 HuCcmRearDefogConfigAck 0;
BA_ "GenSigTimeoutMsg_HU_B" SG_ 474 HuCcmRearDefogConfigAck 0;
BA_ "GenSigTimeoutMsg_HU_A" SG_ 474 HuCcmRearDefogConfigAck 0;
BA_ "GenSigSendType" SG_ 474 HuCcmRearDefogConfigAck 1;
BA_ "GenSigTimeoutMsg_HU_High_X445" SG_ 474 HuCcmRearDefogConfigAck 0;
BA_ "GenSigTimeoutMsg_HU_Mid_X445" SG_ 474 HuCcmRearDefogConfigAck 0;
BA_ "GenSigTimeoutTime_HU_High_X445" SG_ 474 HuCcmRearDefogConfigAck 0;
BA_ "GenSigTimeoutTime_HU_Mid_X445" SG_ 474 HuCcmRearDefogConfigAck 0;
BA_ "GenSigTimeoutMsg_IVI" SG_ 474 HuCcmRearDefogConfigAck 0;
BA_ "GenSigTimeoutTime_IVI" SG_ 474 HuCcmRearDefogConfigAck 0;
BA_ "GenSigTimeoutTime_HU_Mid_X451" SG_ 474 HuCcmRearBlwrConfigAck 0;
BA_ "GenSigTimeoutTime_HU_High_X451" SG_ 474 HuCcmRearBlwrConfigAck 0;
BA_ "GenSigTimeoutTime_HU_B" SG_ 474 HuCcmRearBlwrConfigAck 0;
BA_ "GenSigTimeoutTime_HU_A" SG_ 474 HuCcmRearBlwrConfigAck 0;
BA_ "GenSigTimeoutMsg_HU_Mid_X451" SG_ 474 HuCcmRearBlwrConfigAck 0;
BA_ "GenSigTimeoutMsg_HU_High_X451" SG_ 474 HuCcmRearBlwrConfigAck 0;
BA_ "GenSigTimeoutMsg_HU_B" SG_ 474 HuCcmRearBlwrConfigAck 0;
BA_ "GenSigTimeoutMsg_HU_A" SG_ 474 HuCcmRearBlwrConfigAck 0;
BA_ "GenSigSendType" SG_ 474 HuCcmRearBlwrConfigAck 1;
BA_ "GenSigTimeoutMsg_HU_High_X445" SG_ 474 HuCcmRearBlwrConfigAck 0;
BA_ "GenSigTimeoutMsg_HU_Mid_X445" SG_ 474 HuCcmRearBlwrConfigAck 0;
BA_ "GenSigTimeoutTime_HU_High_X445" SG_ 474 HuCcmRearBlwrConfigAck 0;
BA_ "GenSigTimeoutTime_HU_Mid_X445" SG_ 474 HuCcmRearBlwrConfigAck 0;
BA_ "GenSigTimeoutMsg_IVI" SG_ 474 HuCcmRearBlwrConfigAck 0;
BA_ "GenSigTimeoutTime_IVI" SG_ 474 HuCcmRearBlwrConfigAck 0;
BA_ "GenSigTimeoutTime_HU_Mid_X451" SG_ 474 HuCcmEconConfigAck 0;
BA_ "GenSigTimeoutTime_HU_High_X451" SG_ 474 HuCcmEconConfigAck 0;
BA_ "GenSigTimeoutTime_HU_B" SG_ 474 HuCcmEconConfigAck 0;
BA_ "GenSigTimeoutTime_HU_A" SG_ 474 HuCcmEconConfigAck 0;
BA_ "GenSigTimeoutMsg_HU_Mid_X451" SG_ 474 HuCcmEconConfigAck 0;
BA_ "GenSigTimeoutMsg_HU_High_X451" SG_ 474 HuCcmEconConfigAck 0;
BA_ "GenSigTimeoutMsg_HU_B" SG_ 474 HuCcmEconConfigAck 0;
BA_ "GenSigTimeoutMsg_HU_A" SG_ 474 HuCcmEconConfigAck 0;
BA_ "GenSigSendType" SG_ 474 HuCcmEconConfigAck 1;
BA_ "GenSigTimeoutMsg_HU_High_X445" SG_ 474 HuCcmEconConfigAck 0;
BA_ "GenSigTimeoutMsg_HU_Mid_X445" SG_ 474 HuCcmEconConfigAck 0;
BA_ "GenSigTimeoutTime_HU_High_X445" SG_ 474 HuCcmEconConfigAck 0;
BA_ "GenSigTimeoutTime_HU_Mid_X445" SG_ 474 HuCcmEconConfigAck 0;
BA_ "GenSigTimeoutMsg_IVI" SG_ 474 HuCcmEconConfigAck 0;
BA_ "GenSigTimeoutTime_IVI" SG_ 474 HuCcmEconConfigAck 0;
BA_ "GenSigTimeoutTime_HU_Mid_X451" SG_ 474 HuCcmExpressCoolConfigAck 0;
BA_ "GenSigTimeoutTime_HU_High_X451" SG_ 474 HuCcmExpressCoolConfigAck 0;
BA_ "GenSigTimeoutTime_HU_B" SG_ 474 HuCcmExpressCoolConfigAck 0;
BA_ "GenSigTimeoutTime_HU_A" SG_ 474 HuCcmExpressCoolConfigAck 0;
BA_ "GenSigTimeoutMsg_HU_Mid_X451" SG_ 474 HuCcmExpressCoolConfigAck 0;
BA_ "GenSigTimeoutMsg_HU_High_X451" SG_ 474 HuCcmExpressCoolConfigAck 0;
BA_ "GenSigTimeoutMsg_HU_B" SG_ 474 HuCcmExpressCoolConfigAck 0;
BA_ "GenSigTimeoutMsg_HU_A" SG_ 474 HuCcmExpressCoolConfigAck 0;
BA_ "GenSigSendType" SG_ 474 HuCcmExpressCoolConfigAck 1;
BA_ "GenSigTimeoutMsg_HU_High_X445" SG_ 474 HuCcmExpressCoolConfigAck 0;
BA_ "GenSigTimeoutMsg_HU_Mid_X445" SG_ 474 HuCcmExpressCoolConfigAck 0;
BA_ "GenSigTimeoutTime_HU_High_X445" SG_ 474 HuCcmExpressCoolConfigAck 0;
BA_ "GenSigTimeoutTime_HU_Mid_X445" SG_ 474 HuCcmExpressCoolConfigAck 0;
BA_ "GenSigTimeoutMsg_IVI" SG_ 474 HuCcmExpressCoolConfigAck 0;
BA_ "GenSigTimeoutTime_IVI" SG_ 474 HuCcmExpressCoolConfigAck 0;
BA_ "GenSigTimeoutTime_HU_Mid_X451" SG_ 474 HuCCmLowFanSpdConfigValueAck 0;
BA_ "GenSigTimeoutTime_HU_High_X451" SG_ 474 HuCCmLowFanSpdConfigValueAck 0;
BA_ "GenSigTimeoutTime_HU_B" SG_ 474 HuCCmLowFanSpdConfigValueAck 0;
BA_ "GenSigTimeoutTime_HU_A" SG_ 474 HuCCmLowFanSpdConfigValueAck 0;
BA_ "GenSigTimeoutMsg_HU_Mid_X451" SG_ 474 HuCCmLowFanSpdConfigValueAck 0;
BA_ "GenSigTimeoutMsg_HU_High_X451" SG_ 474 HuCCmLowFanSpdConfigValueAck 0;
BA_ "GenSigTimeoutMsg_HU_B" SG_ 474 HuCCmLowFanSpdConfigValueAck 0;
BA_ "GenSigTimeoutMsg_HU_A" SG_ 474 HuCCmLowFanSpdConfigValueAck 0;
BA_ "GenSigSendType" SG_ 474 HuCCmLowFanSpdConfigValueAck 1;
BA_ "GenSigTimeoutMsg_HU_High_X445" SG_ 474 HuCCmLowFanSpdConfigValueAck 0;
BA_ "GenSigTimeoutMsg_HU_Mid_X445" SG_ 474 HuCCmLowFanSpdConfigValueAck 0;
BA_ "GenSigTimeoutTime_HU_High_X445" SG_ 474 HuCCmLowFanSpdConfigValueAck 0;
BA_ "GenSigTimeoutTime_HU_Mid_X445" SG_ 474 HuCCmLowFanSpdConfigValueAck 0;
BA_ "GenSigTimeoutMsg_IVI" SG_ 474 HuCCmLowFanSpdConfigValueAck 0;
BA_ "GenSigTimeoutTime_IVI" SG_ 474 HuCCmLowFanSpdConfigValueAck 0;
BA_ "GenSigTimeoutTime_HU_Mid_X451" SG_ 474 HuCCmHiFanSpdConfigValueAck 0;
BA_ "GenSigTimeoutTime_HU_High_X451" SG_ 474 HuCCmHiFanSpdConfigValueAck 0;
BA_ "GenSigTimeoutTime_HU_B" SG_ 474 HuCCmHiFanSpdConfigValueAck 0;
BA_ "GenSigTimeoutTime_HU_A" SG_ 474 HuCCmHiFanSpdConfigValueAck 0;
BA_ "GenSigTimeoutMsg_HU_Mid_X451" SG_ 474 HuCCmHiFanSpdConfigValueAck 0;
BA_ "GenSigTimeoutMsg_HU_High_X451" SG_ 474 HuCCmHiFanSpdConfigValueAck 0;
BA_ "GenSigTimeoutMsg_HU_B" SG_ 474 HuCCmHiFanSpdConfigValueAck 0;
BA_ "GenSigTimeoutMsg_HU_A" SG_ 474 HuCCmHiFanSpdConfigValueAck 0;
BA_ "GenSigSendType" SG_ 474 HuCCmHiFanSpdConfigValueAck 1;
BA_ "GenSigTimeoutMsg_HU_High_X445" SG_ 474 HuCCmHiFanSpdConfigValueAck 0;
BA_ "GenSigTimeoutMsg_HU_Mid_X445" SG_ 474 HuCCmHiFanSpdConfigValueAck 0;
BA_ "GenSigTimeoutTime_HU_High_X445" SG_ 474 HuCCmHiFanSpdConfigValueAck 0;
BA_ "GenSigTimeoutTime_HU_Mid_X445" SG_ 474 HuCCmHiFanSpdConfigValueAck 0;
BA_ "GenSigTimeoutMsg_IVI" SG_ 474 HuCCmHiFanSpdConfigValueAck 0;
BA_ "GenSigTimeoutTime_IVI" SG_ 474 HuCCmHiFanSpdConfigValueAck 0;
BA_ "GenSigTimeoutTime_HU_Mid_X451" SG_ 474 HuCCmLowTempConfigValueAck 0;
BA_ "GenSigTimeoutTime_HU_High_X451" SG_ 474 HuCCmLowTempConfigValueAck 0;
BA_ "GenSigTimeoutTime_HU_B" SG_ 474 HuCCmLowTempConfigValueAck 0;
BA_ "GenSigTimeoutTime_HU_A" SG_ 474 HuCCmLowTempConfigValueAck 0;
BA_ "GenSigTimeoutMsg_HU_Mid_X451" SG_ 474 HuCCmLowTempConfigValueAck 0;
BA_ "GenSigTimeoutMsg_HU_High_X451" SG_ 474 HuCCmLowTempConfigValueAck 0;
BA_ "GenSigTimeoutMsg_HU_B" SG_ 474 HuCCmLowTempConfigValueAck 0;
BA_ "GenSigTimeoutMsg_HU_A" SG_ 474 HuCCmLowTempConfigValueAck 0;
BA_ "GenSigSendType" SG_ 474 HuCCmLowTempConfigValueAck 1;
BA_ "GenSigTimeoutMsg_HU_High_X445" SG_ 474 HuCCmLowTempConfigValueAck 0;
BA_ "GenSigTimeoutMsg_HU_Mid_X445" SG_ 474 HuCCmLowTempConfigValueAck 0;
BA_ "GenSigTimeoutTime_HU_High_X445" SG_ 474 HuCCmLowTempConfigValueAck 0;
BA_ "GenSigTimeoutTime_HU_Mid_X445" SG_ 474 HuCCmLowTempConfigValueAck 0;
BA_ "GenSigTimeoutMsg_IVI" SG_ 474 HuCCmLowTempConfigValueAck 0;
BA_ "GenSigTimeoutTime_IVI" SG_ 474 HuCCmLowTempConfigValueAck 0;
BA_ "GenSigTimeoutTime_HU_Mid_X451" SG_ 474 HuCCmFanControlDuringVRAck 0;
BA_ "GenSigTimeoutTime_HU_High_X451" SG_ 474 HuCCmFanControlDuringVRAck 0;
BA_ "GenSigTimeoutTime_HU_B" SG_ 474 HuCCmFanControlDuringVRAck 0;
BA_ "GenSigTimeoutTime_HU_A" SG_ 474 HuCCmFanControlDuringVRAck 0;
BA_ "GenSigTimeoutMsg_HU_Mid_X451" SG_ 474 HuCCmFanControlDuringVRAck 0;
BA_ "GenSigTimeoutMsg_HU_High_X451" SG_ 474 HuCCmFanControlDuringVRAck 0;
BA_ "GenSigTimeoutMsg_HU_B" SG_ 474 HuCCmFanControlDuringVRAck 0;
BA_ "GenSigTimeoutMsg_HU_A" SG_ 474 HuCCmFanControlDuringVRAck 0;
BA_ "GenSigStartValue" SG_ 474 HuCCmFanControlDuringVRAck 1;
BA_ "GenSigSendType" SG_ 474 HuCCmFanControlDuringVRAck 1;
BA_ "GenSigTimeoutMsg_HU_High_X445" SG_ 474 HuCCmFanControlDuringVRAck 0;
BA_ "GenSigTimeoutMsg_HU_Mid_X445" SG_ 474 HuCCmFanControlDuringVRAck 0;
BA_ "GenSigTimeoutTime_HU_High_X445" SG_ 474 HuCCmFanControlDuringVRAck 0;
BA_ "GenSigTimeoutTime_HU_Mid_X445" SG_ 474 HuCCmFanControlDuringVRAck 0;
BA_ "GenSigTimeoutMsg_IVI" SG_ 474 HuCCmFanControlDuringVRAck 0;
BA_ "GenSigTimeoutTime_IVI" SG_ 474 HuCCmFanControlDuringVRAck 0;
BA_ "GenSigTimeoutTime_HU_Mid_X451" SG_ 474 HuCCmHiTempConfigValueAck 0;
BA_ "GenSigTimeoutTime_HU_High_X451" SG_ 474 HuCCmHiTempConfigValueAck 0;
BA_ "GenSigTimeoutTime_HU_B" SG_ 474 HuCCmHiTempConfigValueAck 0;
BA_ "GenSigTimeoutTime_HU_A" SG_ 474 HuCCmHiTempConfigValueAck 0;
BA_ "GenSigTimeoutMsg_HU_Mid_X451" SG_ 474 HuCCmHiTempConfigValueAck 0;
BA_ "GenSigTimeoutMsg_HU_High_X451" SG_ 474 HuCCmHiTempConfigValueAck 0;
BA_ "GenSigTimeoutMsg_HU_B" SG_ 474 HuCCmHiTempConfigValueAck 0;
BA_ "GenSigTimeoutMsg_HU_A" SG_ 474 HuCCmHiTempConfigValueAck 0;
BA_ "GenSigSendType" SG_ 474 HuCCmHiTempConfigValueAck 1;
BA_ "GenSigTimeoutMsg_HU_High_X445" SG_ 474 HuCCmHiTempConfigValueAck 0;
BA_ "GenSigTimeoutMsg_HU_Mid_X445" SG_ 474 HuCCmHiTempConfigValueAck 0;
BA_ "GenSigTimeoutTime_HU_High_X445" SG_ 474 HuCCmHiTempConfigValueAck 0;
BA_ "GenSigTimeoutTime_HU_Mid_X445" SG_ 474 HuCCmHiTempConfigValueAck 0;
BA_ "GenSigTimeoutMsg_IVI" SG_ 474 HuCCmHiTempConfigValueAck 0;
BA_ "GenSigTimeoutTime_IVI" SG_ 474 HuCCmHiTempConfigValueAck 0;
BA_ "GenSigTimeoutTime_HU_Mid_X451" SG_ 475 HuIcAlertFeatureTypeAck 0;
BA_ "GenSigTimeoutTime_HU_High_X451" SG_ 475 HuIcAlertFeatureTypeAck 0;
BA_ "GenSigTimeoutTime_HU_B" SG_ 475 HuIcAlertFeatureTypeAck 0;
BA_ "GenSigTimeoutTime_HU_A" SG_ 475 HuIcAlertFeatureTypeAck 0;
BA_ "GenSigTimeoutMsg_HU_Mid_X451" SG_ 475 HuIcAlertFeatureTypeAck 0;
BA_ "GenSigTimeoutMsg_HU_High_X451" SG_ 475 HuIcAlertFeatureTypeAck 0;
BA_ "GenSigTimeoutMsg_HU_B" SG_ 475 HuIcAlertFeatureTypeAck 0;
BA_ "GenSigTimeoutMsg_HU_A" SG_ 475 HuIcAlertFeatureTypeAck 0;
BA_ "GenSigSendType" SG_ 475 HuIcAlertFeatureTypeAck 1;
BA_ "GenSigTimeoutMsg_HU_High_X445" SG_ 475 HuIcAlertFeatureTypeAck 0;
BA_ "GenSigTimeoutMsg_HU_Mid_X445" SG_ 475 HuIcAlertFeatureTypeAck 0;
BA_ "GenSigTimeoutTime_HU_High_X445" SG_ 475 HuIcAlertFeatureTypeAck 0;
BA_ "GenSigTimeoutTime_HU_Mid_X445" SG_ 475 HuIcAlertFeatureTypeAck 0;
BA_ "GenSigTimeoutMsg_IVI" SG_ 475 HuIcAlertFeatureTypeAck 0;
BA_ "GenSigTimeoutTime_IVI" SG_ 475 HuIcAlertFeatureTypeAck 0;
BA_ "GenSigTimeoutTime_HU_Mid_X451" SG_ 475 HuIcAlertFeaturePresenceAck 0;
BA_ "GenSigTimeoutTime_HU_High_X451" SG_ 475 HuIcAlertFeaturePresenceAck 0;
BA_ "GenSigTimeoutTime_HU_B" SG_ 475 HuIcAlertFeaturePresenceAck 0;
BA_ "GenSigTimeoutTime_HU_A" SG_ 475 HuIcAlertFeaturePresenceAck 0;
BA_ "GenSigTimeoutMsg_HU_Mid_X451" SG_ 475 HuIcAlertFeaturePresenceAck 0;
BA_ "GenSigTimeoutMsg_HU_High_X451" SG_ 475 HuIcAlertFeaturePresenceAck 0;
BA_ "GenSigTimeoutMsg_HU_B" SG_ 475 HuIcAlertFeaturePresenceAck 0;
BA_ "GenSigTimeoutMsg_HU_A" SG_ 475 HuIcAlertFeaturePresenceAck 0;
BA_ "GenSigSendType" SG_ 475 HuIcAlertFeaturePresenceAck 1;
BA_ "GenSigTimeoutMsg_HU_High_X445" SG_ 475 HuIcAlertFeaturePresenceAck 0;
BA_ "GenSigTimeoutMsg_HU_Mid_X445" SG_ 475 HuIcAlertFeaturePresenceAck 0;
BA_ "GenSigTimeoutTime_HU_High_X445" SG_ 475 HuIcAlertFeaturePresenceAck 0;
BA_ "GenSigTimeoutTime_HU_Mid_X445" SG_ 475 HuIcAlertFeaturePresenceAck 0;
BA_ "GenSigTimeoutMsg_IVI" SG_ 475 HuIcAlertFeaturePresenceAck 0;
BA_ "GenSigTimeoutTime_IVI" SG_ 475 HuIcAlertFeaturePresenceAck 0;
BA_ "GenSigTimeoutTime_HU_Mid_X451" SG_ 476 HuIcVoiceAlertFeaturePresence 0;
BA_ "GenSigTimeoutTime_HU_High_X451" SG_ 476 HuIcVoiceAlertFeaturePresence 0;
BA_ "GenSigTimeoutTime_HU_B" SG_ 476 HuIcVoiceAlertFeaturePresence 0;
BA_ "GenSigTimeoutTime_HU_A" SG_ 476 HuIcVoiceAlertFeaturePresence 0;
BA_ "GenSigTimeoutMsg_HU_Mid_X451" SG_ 476 HuIcVoiceAlertFeaturePresence 0;
BA_ "GenSigTimeoutMsg_HU_High_X451" SG_ 476 HuIcVoiceAlertFeaturePresence 0;
BA_ "GenSigTimeoutMsg_HU_B" SG_ 476 HuIcVoiceAlertFeaturePresence 0;
BA_ "GenSigTimeoutMsg_HU_A" SG_ 476 HuIcVoiceAlertFeaturePresence 0;
BA_ "GenSigSendType" SG_ 476 HuIcVoiceAlertFeaturePresence 1;
BA_ "GenSigTimeoutMsg_HU_High_X445" SG_ 476 HuIcVoiceAlertFeaturePresence 0;
BA_ "GenSigTimeoutMsg_HU_Mid_X445" SG_ 476 HuIcVoiceAlertFeaturePresence 0;
BA_ "GenSigTimeoutTime_HU_High_X445" SG_ 476 HuIcVoiceAlertFeaturePresence 0;
BA_ "GenSigTimeoutTime_HU_Mid_X445" SG_ 476 HuIcVoiceAlertFeaturePresence 0;
BA_ "GenSigTimeoutMsg_IVI" SG_ 476 HuIcVoiceAlertFeaturePresence 0;
BA_ "GenSigTimeoutTime_IVI" SG_ 476 HuIcVoiceAlertFeaturePresence 0;
BA_ "GenSigTimeoutTime_HU_Mid_X451" SG_ 476 HuIcVoiceAlertSelectionState 0;
BA_ "GenSigTimeoutTime_HU_High_X451" SG_ 476 HuIcVoiceAlertSelectionState 0;
BA_ "GenSigTimeoutTime_HU_B" SG_ 476 HuIcVoiceAlertSelectionState 0;
BA_ "GenSigTimeoutTime_HU_A" SG_ 476 HuIcVoiceAlertSelectionState 0;
BA_ "GenSigTimeoutMsg_HU_Mid_X451" SG_ 476 HuIcVoiceAlertSelectionState 0;
BA_ "GenSigTimeoutMsg_HU_High_X451" SG_ 476 HuIcVoiceAlertSelectionState 0;
BA_ "GenSigTimeoutMsg_HU_B" SG_ 476 HuIcVoiceAlertSelectionState 0;
BA_ "GenSigTimeoutMsg_HU_A" SG_ 476 HuIcVoiceAlertSelectionState 0;
BA_ "GenSigSendType" SG_ 476 HuIcVoiceAlertSelectionState 1;
BA_ "GenSigTimeoutMsg_HU_High_X445" SG_ 476 HuIcVoiceAlertSelectionState 0;
BA_ "GenSigTimeoutMsg_HU_Mid_X445" SG_ 476 HuIcVoiceAlertSelectionState 0;
BA_ "GenSigTimeoutTime_HU_High_X445" SG_ 476 HuIcVoiceAlertSelectionState 0;
BA_ "GenSigTimeoutTime_HU_Mid_X445" SG_ 476 HuIcVoiceAlertSelectionState 0;
BA_ "GenSigTimeoutMsg_IVI" SG_ 476 HuIcVoiceAlertSelectionState 0;
BA_ "GenSigTimeoutTime_IVI" SG_ 476 HuIcVoiceAlertSelectionState 0;
BA_ "GenSigTimeoutTime_HU_Mid_X451" SG_ 476 HuIcTextAlertSelectionState 0;
BA_ "GenSigTimeoutTime_HU_High_X451" SG_ 476 HuIcTextAlertSelectionState 0;
BA_ "GenSigTimeoutTime_HU_B" SG_ 476 HuIcTextAlertSelectionState 0;
BA_ "GenSigTimeoutTime_HU_A" SG_ 476 HuIcTextAlertSelectionState 0;
BA_ "GenSigTimeoutMsg_HU_Mid_X451" SG_ 476 HuIcTextAlertSelectionState 0;
BA_ "GenSigTimeoutMsg_HU_High_X451" SG_ 476 HuIcTextAlertSelectionState 0;
BA_ "GenSigTimeoutMsg_HU_B" SG_ 476 HuIcTextAlertSelectionState 0;
BA_ "GenSigTimeoutMsg_HU_A" SG_ 476 HuIcTextAlertSelectionState 0;
BA_ "GenSigSendType" SG_ 476 HuIcTextAlertSelectionState 1;
BA_ "GenSigTimeoutMsg_HU_High_X445" SG_ 476 HuIcTextAlertSelectionState 0;
BA_ "GenSigTimeoutMsg_HU_Mid_X445" SG_ 476 HuIcTextAlertSelectionState 0;
BA_ "GenSigTimeoutTime_HU_High_X445" SG_ 476 HuIcTextAlertSelectionState 0;
BA_ "GenSigTimeoutTime_HU_Mid_X445" SG_ 476 HuIcTextAlertSelectionState 0;
BA_ "GenSigTimeoutMsg_IVI" SG_ 476 HuIcTextAlertSelectionState 0;
BA_ "GenSigTimeoutTime_IVI" SG_ 476 HuIcTextAlertSelectionState 0;
BA_ "GenSigTimeoutTime_HU_Mid_X451" SG_ 477 IcHuVoiceAlertSelectionState 0;
BA_ "GenSigTimeoutTime_HU_High_X451" SG_ 477 IcHuVoiceAlertSelectionState 0;
BA_ "GenSigTimeoutTime_HU_B" SG_ 477 IcHuVoiceAlertSelectionState 0;
BA_ "GenSigTimeoutTime_HU_A" SG_ 477 IcHuVoiceAlertSelectionState 0;
BA_ "GenSigTimeoutMsg_HU_Mid_X451" SG_ 477 IcHuVoiceAlertSelectionState 0;
BA_ "GenSigTimeoutMsg_HU_High_X451" SG_ 477 IcHuVoiceAlertSelectionState 0;
BA_ "GenSigTimeoutMsg_HU_B" SG_ 477 IcHuVoiceAlertSelectionState 0;
BA_ "GenSigTimeoutMsg_HU_A" SG_ 477 IcHuVoiceAlertSelectionState 0;
BA_ "GenSigSendType" SG_ 477 IcHuVoiceAlertSelectionState 1;
BA_ "GenSigTimeoutMsg_HU_High_X445" SG_ 477 IcHuVoiceAlertSelectionState 0;
BA_ "GenSigTimeoutMsg_HU_Mid_X445" SG_ 477 IcHuVoiceAlertSelectionState 0;
BA_ "GenSigTimeoutTime_HU_High_X445" SG_ 477 IcHuVoiceAlertSelectionState 0;
BA_ "GenSigTimeoutTime_HU_Mid_X445" SG_ 477 IcHuVoiceAlertSelectionState 0;
BA_ "GenSigTimeoutMsg_IVI" SG_ 477 IcHuVoiceAlertSelectionState 0;
BA_ "GenSigTimeoutTime_IVI" SG_ 477 IcHuVoiceAlertSelectionState 0;
BA_ "GenSigTimeoutTime_HU_Mid_X451" SG_ 477 IcHuAlertFeatureType 0;
BA_ "GenSigTimeoutTime_HU_High_X451" SG_ 477 IcHuAlertFeatureType 0;
BA_ "GenSigTimeoutTime_HU_B" SG_ 477 IcHuAlertFeatureType 0;
BA_ "GenSigTimeoutTime_HU_A" SG_ 477 IcHuAlertFeatureType 0;
BA_ "GenSigTimeoutMsg_HU_Mid_X451" SG_ 477 IcHuAlertFeatureType 0;
BA_ "GenSigTimeoutMsg_HU_High_X451" SG_ 477 IcHuAlertFeatureType 0;
BA_ "GenSigTimeoutMsg_HU_B" SG_ 477 IcHuAlertFeatureType 0;
BA_ "GenSigTimeoutMsg_HU_A" SG_ 477 IcHuAlertFeatureType 0;
BA_ "GenSigSendType" SG_ 477 IcHuAlertFeatureType 1;
BA_ "GenSigTimeoutMsg_HU_High_X445" SG_ 477 IcHuAlertFeatureType 0;
BA_ "GenSigTimeoutMsg_HU_Mid_X445" SG_ 477 IcHuAlertFeatureType 0;
BA_ "GenSigTimeoutTime_HU_High_X445" SG_ 477 IcHuAlertFeatureType 0;
BA_ "GenSigTimeoutTime_HU_Mid_X445" SG_ 477 IcHuAlertFeatureType 0;
BA_ "GenSigTimeoutMsg_IVI" SG_ 477 IcHuAlertFeatureType 0;
BA_ "GenSigTimeoutTime_IVI" SG_ 477 IcHuAlertFeatureType 0;
BA_ "GenSigTimeoutTime_HU_Mid_X451" SG_ 477 IcHuAlertFeaturePresence 0;
BA_ "GenSigTimeoutTime_HU_High_X451" SG_ 477 IcHuAlertFeaturePresence 0;
BA_ "GenSigTimeoutTime_HU_B" SG_ 477 IcHuAlertFeaturePresence 0;
BA_ "GenSigTimeoutTime_HU_A" SG_ 477 IcHuAlertFeaturePresence 0;
BA_ "GenSigTimeoutMsg_HU_Mid_X451" SG_ 477 IcHuAlertFeaturePresence 0;
BA_ "GenSigTimeoutMsg_HU_High_X451" SG_ 477 IcHuAlertFeaturePresence 0;
BA_ "GenSigTimeoutMsg_HU_B" SG_ 477 IcHuAlertFeaturePresence 0;
BA_ "GenSigTimeoutMsg_HU_A" SG_ 477 IcHuAlertFeaturePresence 0;
BA_ "GenSigSendType" SG_ 477 IcHuAlertFeaturePresence 1;
BA_ "GenSigTimeoutMsg_HU_High_X445" SG_ 477 IcHuAlertFeaturePresence 0;
BA_ "GenSigTimeoutMsg_HU_Mid_X445" SG_ 477 IcHuAlertFeaturePresence 0;
BA_ "GenSigTimeoutTime_HU_High_X445" SG_ 477 IcHuAlertFeaturePresence 0;
BA_ "GenSigTimeoutTime_HU_Mid_X445" SG_ 477 IcHuAlertFeaturePresence 0;
BA_ "GenSigTimeoutMsg_IVI" SG_ 477 IcHuAlertFeaturePresence 0;
BA_ "GenSigTimeoutTime_IVI" SG_ 477 IcHuAlertFeaturePresence 0;
BA_ "GenSigTimeoutTime_HU_Mid_X451" SG_ 478 IcHuVoiceAlertFeaturePresenceAck 0;
BA_ "GenSigTimeoutTime_HU_High_X451" SG_ 478 IcHuVoiceAlertFeaturePresenceAck 0;
BA_ "GenSigTimeoutTime_HU_B" SG_ 478 IcHuVoiceAlertFeaturePresenceAck 0;
BA_ "GenSigTimeoutTime_HU_A" SG_ 478 IcHuVoiceAlertFeaturePresenceAck 0;
BA_ "GenSigTimeoutMsg_HU_Mid_X451" SG_ 478 IcHuVoiceAlertFeaturePresenceAck 0;
BA_ "GenSigTimeoutMsg_HU_High_X451" SG_ 478 IcHuVoiceAlertFeaturePresenceAck 0;
BA_ "GenSigTimeoutMsg_HU_B" SG_ 478 IcHuVoiceAlertFeaturePresenceAck 0;
BA_ "GenSigTimeoutMsg_HU_A" SG_ 478 IcHuVoiceAlertFeaturePresenceAck 0;
BA_ "GenSigSendType" SG_ 478 IcHuVoiceAlertFeaturePresenceAck 1;
BA_ "GenSigTimeoutMsg_HU_High_X445" SG_ 478 IcHuVoiceAlertFeaturePresenceAck 0;
BA_ "GenSigTimeoutMsg_HU_Mid_X445" SG_ 478 IcHuVoiceAlertFeaturePresenceAck 0;
BA_ "GenSigTimeoutTime_HU_High_X445" SG_ 478 IcHuVoiceAlertFeaturePresenceAck 0;
BA_ "GenSigTimeoutTime_HU_Mid_X445" SG_ 478 IcHuVoiceAlertFeaturePresenceAck 0;
BA_ "GenSigTimeoutMsg_IVI" SG_ 478 IcHuVoiceAlertFeaturePresenceAck 0;
BA_ "GenSigTimeoutTime_IVI" SG_ 478 IcHuVoiceAlertFeaturePresenceAck 0;
BA_ "GenSigTimeoutTime_HU_Mid_X451" SG_ 478 IcHuVoiceAlertSelectionStateAck 0;
BA_ "GenSigTimeoutTime_HU_High_X451" SG_ 478 IcHuVoiceAlertSelectionStateAck 0;
BA_ "GenSigTimeoutTime_HU_B" SG_ 478 IcHuVoiceAlertSelectionStateAck 0;
BA_ "GenSigTimeoutTime_HU_A" SG_ 478 IcHuVoiceAlertSelectionStateAck 0;
BA_ "GenSigTimeoutMsg_HU_Mid_X451" SG_ 478 IcHuVoiceAlertSelectionStateAck 0;
BA_ "GenSigTimeoutMsg_HU_High_X451" SG_ 478 IcHuVoiceAlertSelectionStateAck 0;
BA_ "GenSigTimeoutMsg_HU_B" SG_ 478 IcHuVoiceAlertSelectionStateAck 0;
BA_ "GenSigTimeoutMsg_HU_A" SG_ 478 IcHuVoiceAlertSelectionStateAck 0;
BA_ "GenSigSendType" SG_ 478 IcHuVoiceAlertSelectionStateAck 1;
BA_ "GenSigTimeoutMsg_HU_High_X445" SG_ 478 IcHuVoiceAlertSelectionStateAck 0;
BA_ "GenSigTimeoutMsg_HU_Mid_X445" SG_ 478 IcHuVoiceAlertSelectionStateAck 0;
BA_ "GenSigTimeoutTime_HU_High_X445" SG_ 478 IcHuVoiceAlertSelectionStateAck 0;
BA_ "GenSigTimeoutTime_HU_Mid_X445" SG_ 478 IcHuVoiceAlertSelectionStateAck 0;
BA_ "GenSigTimeoutMsg_IVI" SG_ 478 IcHuVoiceAlertSelectionStateAck 0;
BA_ "GenSigTimeoutTime_IVI" SG_ 478 IcHuVoiceAlertSelectionStateAck 0;
BA_ "GenSigTimeoutTime_HU_Mid_X451" SG_ 478 IcHuTextAlertSelectionStateAck 0;
BA_ "GenSigTimeoutTime_HU_High_X451" SG_ 478 IcHuTextAlertSelectionStateAck 0;
BA_ "GenSigTimeoutTime_HU_B" SG_ 478 IcHuTextAlertSelectionStateAck 0;
BA_ "GenSigTimeoutTime_HU_A" SG_ 478 IcHuTextAlertSelectionStateAck 0;
BA_ "GenSigTimeoutMsg_HU_Mid_X451" SG_ 478 IcHuTextAlertSelectionStateAck 0;
BA_ "GenSigTimeoutMsg_HU_High_X451" SG_ 478 IcHuTextAlertSelectionStateAck 0;
BA_ "GenSigTimeoutMsg_HU_B" SG_ 478 IcHuTextAlertSelectionStateAck 0;
BA_ "GenSigTimeoutMsg_HU_A" SG_ 478 IcHuTextAlertSelectionStateAck 0;
BA_ "GenSigSendType" SG_ 478 IcHuTextAlertSelectionStateAck 1;
BA_ "GenSigTimeoutMsg_HU_High_X445" SG_ 478 IcHuTextAlertSelectionStateAck 0;
BA_ "GenSigTimeoutMsg_HU_Mid_X445" SG_ 478 IcHuTextAlertSelectionStateAck 0;
BA_ "GenSigTimeoutTime_HU_High_X445" SG_ 478 IcHuTextAlertSelectionStateAck 0;
BA_ "GenSigTimeoutTime_HU_Mid_X445" SG_ 478 IcHuTextAlertSelectionStateAck 0;
BA_ "GenSigTimeoutMsg_IVI" SG_ 478 IcHuTextAlertSelectionStateAck 0;
BA_ "GenSigTimeoutTime_IVI" SG_ 478 IcHuTextAlertSelectionStateAck 0;
BA_ "GenSigTimeoutTime_HU_Mid_X451" SG_ 479 IcHuDriveproConfigAck 0;
BA_ "GenSigTimeoutTime_HU_High_X451" SG_ 479 IcHuDriveproConfigAck 0;
BA_ "GenSigTimeoutTime_HU_B" SG_ 479 IcHuDriveproConfigAck 0;
BA_ "GenSigTimeoutTime_HU_A" SG_ 479 IcHuDriveproConfigAck 0;
BA_ "GenSigTimeoutMsg_HU_Mid_X451" SG_ 479 IcHuDriveproConfigAck 0;
BA_ "GenSigTimeoutMsg_HU_High_X451" SG_ 479 IcHuDriveproConfigAck 0;
BA_ "GenSigTimeoutMsg_HU_B" SG_ 479 IcHuDriveproConfigAck 0;
BA_ "GenSigTimeoutMsg_HU_A" SG_ 479 IcHuDriveproConfigAck 0;
BA_ "GenSigSendType" SG_ 479 IcHuDriveproConfigAck 1;
BA_ "GenSigTimeoutMsg_HU_High_X445" SG_ 479 IcHuDriveproConfigAck 0;
BA_ "GenSigTimeoutMsg_HU_Mid_X445" SG_ 479 IcHuDriveproConfigAck 0;
BA_ "GenSigTimeoutTime_HU_High_X445" SG_ 479 IcHuDriveproConfigAck 0;
BA_ "GenSigTimeoutTime_HU_Mid_X445" SG_ 479 IcHuDriveproConfigAck 0;
BA_ "GenSigTimeoutMsg_IVI" SG_ 479 IcHuDriveproConfigAck 0;
BA_ "GenSigTimeoutTime_IVI" SG_ 479 IcHuDriveproConfigAck 0;
BA_ "GenSigTimeoutTime_HU_Mid_X451" SG_ 479 IcHuDriveProConfigAckEventStatus 0;
BA_ "GenSigTimeoutTime_HU_High_X451" SG_ 479 IcHuDriveProConfigAckEventStatus 0;
BA_ "GenSigTimeoutTime_HU_B" SG_ 479 IcHuDriveProConfigAckEventStatus 0;
BA_ "GenSigTimeoutTime_HU_A" SG_ 479 IcHuDriveProConfigAckEventStatus 0;
BA_ "GenSigTimeoutMsg_HU_Mid_X451" SG_ 479 IcHuDriveProConfigAckEventStatus 0;
BA_ "GenSigTimeoutMsg_HU_High_X451" SG_ 479 IcHuDriveProConfigAckEventStatus 0;
BA_ "GenSigTimeoutMsg_HU_B" SG_ 479 IcHuDriveProConfigAckEventStatus 0;
BA_ "GenSigTimeoutMsg_HU_A" SG_ 479 IcHuDriveProConfigAckEventStatus 0;
BA_ "GenSigSendType" SG_ 479 IcHuDriveProConfigAckEventStatus 1;
BA_ "GenSigTimeoutMsg_HU_High_X445" SG_ 479 IcHuDriveProConfigAckEventStatus 0;
BA_ "GenSigTimeoutMsg_HU_Mid_X445" SG_ 479 IcHuDriveProConfigAckEventStatus 0;
BA_ "GenSigTimeoutTime_HU_High_X445" SG_ 479 IcHuDriveProConfigAckEventStatus 0;
BA_ "GenSigTimeoutTime_HU_Mid_X445" SG_ 479 IcHuDriveProConfigAckEventStatus 0;
BA_ "GenSigTimeoutMsg_IVI" SG_ 479 IcHuDriveProConfigAckEventStatus 0;
BA_ "GenSigTimeoutTime_IVI" SG_ 479 IcHuDriveProConfigAckEventStatus 0;
BA_ "GenSigTimeoutTime_HU_Mid_X451" SG_ 479 IcHuTripAReset 0;
BA_ "GenSigTimeoutTime_HU_High_X451" SG_ 479 IcHuTripAReset 0;
BA_ "GenSigTimeoutTime_HU_B" SG_ 479 IcHuTripAReset 0;
BA_ "GenSigTimeoutTime_HU_A" SG_ 479 IcHuTripAReset 0;
BA_ "GenSigTimeoutMsg_HU_Mid_X451" SG_ 479 IcHuTripAReset 0;
BA_ "GenSigTimeoutMsg_HU_High_X451" SG_ 479 IcHuTripAReset 0;
BA_ "GenSigTimeoutMsg_HU_B" SG_ 479 IcHuTripAReset 0;
BA_ "GenSigTimeoutMsg_HU_A" SG_ 479 IcHuTripAReset 0;
BA_ "GenSigSendType" SG_ 479 IcHuTripAReset 1;
BA_ "GenSigTimeoutMsg_HU_High_X445" SG_ 479 IcHuTripAReset 0;
BA_ "GenSigTimeoutMsg_HU_Mid_X445" SG_ 479 IcHuTripAReset 0;
BA_ "GenSigTimeoutTime_HU_High_X445" SG_ 479 IcHuTripAReset 0;
BA_ "GenSigTimeoutTime_HU_Mid_X445" SG_ 479 IcHuTripAReset 0;
BA_ "GenSigTimeoutMsg_IVI" SG_ 479 IcHuTripAReset 0;
BA_ "GenSigTimeoutTime_IVI" SG_ 479 IcHuTripAReset 0;
BA_ "GenSigTimeoutTime_HU_Mid_X451" SG_ 479 IcHuTripAResetAck 0;
BA_ "GenSigTimeoutTime_HU_High_X451" SG_ 479 IcHuTripAResetAck 0;
BA_ "GenSigTimeoutTime_HU_B" SG_ 479 IcHuTripAResetAck 0;
BA_ "GenSigTimeoutTime_HU_A" SG_ 479 IcHuTripAResetAck 0;
BA_ "GenSigTimeoutMsg_HU_Mid_X451" SG_ 479 IcHuTripAResetAck 0;
BA_ "GenSigTimeoutMsg_HU_High_X451" SG_ 479 IcHuTripAResetAck 0;
BA_ "GenSigTimeoutMsg_HU_B" SG_ 479 IcHuTripAResetAck 0;
BA_ "GenSigTimeoutMsg_HU_A" SG_ 479 IcHuTripAResetAck 0;
BA_ "GenSigSendType" SG_ 479 IcHuTripAResetAck 1;
BA_ "GenSigTimeoutMsg_HU_High_X445" SG_ 479 IcHuTripAResetAck 0;
BA_ "GenSigTimeoutMsg_HU_Mid_X445" SG_ 479 IcHuTripAResetAck 0;
BA_ "GenSigTimeoutTime_HU_High_X445" SG_ 479 IcHuTripAResetAck 0;
BA_ "GenSigTimeoutTime_HU_Mid_X445" SG_ 479 IcHuTripAResetAck 0;
BA_ "GenSigTimeoutMsg_IVI" SG_ 479 IcHuTripAResetAck 0;
BA_ "GenSigTimeoutTime_IVI" SG_ 479 IcHuTripAResetAck 0;
BA_ "GenSigTimeoutTime_HU_Mid_X451" SG_ 479 IcHuTripBReset 0;
BA_ "GenSigTimeoutTime_HU_High_X451" SG_ 479 IcHuTripBReset 0;
BA_ "GenSigTimeoutTime_HU_B" SG_ 479 IcHuTripBReset 0;
BA_ "GenSigTimeoutTime_HU_A" SG_ 479 IcHuTripBReset 0;
BA_ "GenSigTimeoutMsg_HU_Mid_X451" SG_ 479 IcHuTripBReset 0;
BA_ "GenSigTimeoutMsg_HU_High_X451" SG_ 479 IcHuTripBReset 0;
BA_ "GenSigTimeoutMsg_HU_B" SG_ 479 IcHuTripBReset 0;
BA_ "GenSigTimeoutMsg_HU_A" SG_ 479 IcHuTripBReset 0;
BA_ "GenSigSendType" SG_ 479 IcHuTripBReset 1;
BA_ "GenSigTimeoutMsg_HU_High_X445" SG_ 479 IcHuTripBReset 0;
BA_ "GenSigTimeoutMsg_HU_Mid_X445" SG_ 479 IcHuTripBReset 0;
BA_ "GenSigTimeoutTime_HU_High_X445" SG_ 479 IcHuTripBReset 0;
BA_ "GenSigTimeoutTime_HU_Mid_X445" SG_ 479 IcHuTripBReset 0;
BA_ "GenSigTimeoutMsg_IVI" SG_ 479 IcHuTripBReset 0;
BA_ "GenSigTimeoutTime_IVI" SG_ 479 IcHuTripBReset 0;
BA_ "GenSigTimeoutTime_HU_Mid_X451" SG_ 479 IcHuTripBResetAck 0;
BA_ "GenSigTimeoutTime_HU_High_X451" SG_ 479 IcHuTripBResetAck 0;
BA_ "GenSigTimeoutTime_HU_B" SG_ 479 IcHuTripBResetAck 0;
BA_ "GenSigTimeoutTime_HU_A" SG_ 479 IcHuTripBResetAck 0;
BA_ "GenSigTimeoutMsg_HU_Mid_X451" SG_ 479 IcHuTripBResetAck 0;
BA_ "GenSigTimeoutMsg_HU_High_X451" SG_ 479 IcHuTripBResetAck 0;
BA_ "GenSigTimeoutMsg_HU_B" SG_ 479 IcHuTripBResetAck 0;
BA_ "GenSigTimeoutMsg_HU_A" SG_ 479 IcHuTripBResetAck 0;
BA_ "GenSigSendType" SG_ 479 IcHuTripBResetAck 1;
BA_ "GenSigTimeoutMsg_HU_High_X445" SG_ 479 IcHuTripBResetAck 0;
BA_ "GenSigTimeoutMsg_HU_Mid_X445" SG_ 479 IcHuTripBResetAck 0;
BA_ "GenSigTimeoutTime_HU_High_X445" SG_ 479 IcHuTripBResetAck 0;
BA_ "GenSigTimeoutTime_HU_Mid_X445" SG_ 479 IcHuTripBResetAck 0;
BA_ "GenSigTimeoutMsg_IVI" SG_ 479 IcHuTripBResetAck 0;
BA_ "GenSigTimeoutTime_IVI" SG_ 479 IcHuTripBResetAck 0;
BA_ "GenSigTimeoutTime_HU_Mid_X451" SG_ 479 IcHuResetAllAck 0;
BA_ "GenSigTimeoutTime_HU_High_X451" SG_ 479 IcHuResetAllAck 0;
BA_ "GenSigTimeoutTime_HU_B" SG_ 479 IcHuResetAllAck 0;
BA_ "GenSigTimeoutTime_HU_A" SG_ 479 IcHuResetAllAck 0;
BA_ "GenSigTimeoutMsg_HU_Mid_X451" SG_ 479 IcHuResetAllAck 0;
BA_ "GenSigTimeoutMsg_HU_High_X451" SG_ 479 IcHuResetAllAck 0;
BA_ "GenSigTimeoutMsg_HU_B" SG_ 479 IcHuResetAllAck 0;
BA_ "GenSigTimeoutMsg_HU_A" SG_ 479 IcHuResetAllAck 0;
BA_ "GenSigSendType" SG_ 479 IcHuResetAllAck 1;
BA_ "GenSigTimeoutMsg_HU_High_X445" SG_ 479 IcHuResetAllAck 0;
BA_ "GenSigTimeoutMsg_HU_Mid_X445" SG_ 479 IcHuResetAllAck 0;
BA_ "GenSigTimeoutTime_HU_High_X445" SG_ 479 IcHuResetAllAck 0;
BA_ "GenSigTimeoutTime_HU_Mid_X445" SG_ 479 IcHuResetAllAck 0;
BA_ "GenSigTimeoutMsg_IVI" SG_ 479 IcHuResetAllAck 0;
BA_ "GenSigTimeoutTime_IVI" SG_ 479 IcHuResetAllAck 0;
BA_ "GenSigTimeoutTime_HU_Mid_X451" SG_ 479 IcHuTripResetAckEventStatus 0;
BA_ "GenSigTimeoutTime_HU_High_X451" SG_ 479 IcHuTripResetAckEventStatus 0;
BA_ "GenSigTimeoutTime_HU_B" SG_ 479 IcHuTripResetAckEventStatus 0;
BA_ "GenSigTimeoutTime_HU_A" SG_ 479 IcHuTripResetAckEventStatus 0;
BA_ "GenSigTimeoutMsg_HU_Mid_X451" SG_ 479 IcHuTripResetAckEventStatus 0;
BA_ "GenSigTimeoutMsg_HU_High_X451" SG_ 479 IcHuTripResetAckEventStatus 0;
BA_ "GenSigTimeoutMsg_HU_B" SG_ 479 IcHuTripResetAckEventStatus 0;
BA_ "GenSigTimeoutMsg_HU_A" SG_ 479 IcHuTripResetAckEventStatus 0;
BA_ "GenSigSendType" SG_ 479 IcHuTripResetAckEventStatus 1;
BA_ "GenSigTimeoutMsg_HU_High_X445" SG_ 479 IcHuTripResetAckEventStatus 0;
BA_ "GenSigTimeoutMsg_HU_Mid_X445" SG_ 479 IcHuTripResetAckEventStatus 0;
BA_ "GenSigTimeoutTime_HU_High_X445" SG_ 479 IcHuTripResetAckEventStatus 0;
BA_ "GenSigTimeoutTime_HU_Mid_X445" SG_ 479 IcHuTripResetAckEventStatus 0;
BA_ "GenSigTimeoutMsg_IVI" SG_ 479 IcHuTripResetAckEventStatus 0;
BA_ "GenSigTimeoutTime_IVI" SG_ 479 IcHuTripResetAckEventStatus 0;
BA_ "GenSigTimeoutTime_HU_Mid_X451" SG_ 479 IcHuTripResetEventStatus 0;
BA_ "GenSigTimeoutTime_HU_High_X451" SG_ 479 IcHuTripResetEventStatus 0;
BA_ "GenSigTimeoutTime_HU_B" SG_ 479 IcHuTripResetEventStatus 0;
BA_ "GenSigTimeoutTime_HU_A" SG_ 479 IcHuTripResetEventStatus 0;
BA_ "GenSigTimeoutMsg_HU_Mid_X451" SG_ 479 IcHuTripResetEventStatus 0;
BA_ "GenSigTimeoutMsg_HU_High_X451" SG_ 479 IcHuTripResetEventStatus 0;
BA_ "GenSigTimeoutMsg_HU_B" SG_ 479 IcHuTripResetEventStatus 0;
BA_ "GenSigTimeoutMsg_HU_A" SG_ 479 IcHuTripResetEventStatus 0;
BA_ "GenSigSendType" SG_ 479 IcHuTripResetEventStatus 1;
BA_ "GenSigTimeoutMsg_HU_High_X445" SG_ 479 IcHuTripResetEventStatus 0;
BA_ "GenSigTimeoutMsg_HU_Mid_X445" SG_ 479 IcHuTripResetEventStatus 0;
BA_ "GenSigTimeoutTime_HU_High_X445" SG_ 479 IcHuTripResetEventStatus 0;
BA_ "GenSigTimeoutTime_HU_Mid_X445" SG_ 479 IcHuTripResetEventStatus 0;
BA_ "GenSigTimeoutMsg_IVI" SG_ 479 IcHuTripResetEventStatus 0;
BA_ "GenSigTimeoutTime_IVI" SG_ 479 IcHuTripResetEventStatus 0;
BA_ "GenSigTimeoutTime_HU_Mid_X451" SG_ 479 IcHuOverallTripResetAck 0;
BA_ "GenSigTimeoutTime_HU_High_X451" SG_ 479 IcHuOverallTripResetAck 0;
BA_ "GenSigTimeoutTime_HU_B" SG_ 479 IcHuOverallTripResetAck 0;
BA_ "GenSigTimeoutTime_HU_A" SG_ 479 IcHuOverallTripResetAck 0;
BA_ "GenSigTimeoutMsg_HU_Mid_X451" SG_ 479 IcHuOverallTripResetAck 0;
BA_ "GenSigTimeoutMsg_HU_High_X451" SG_ 479 IcHuOverallTripResetAck 0;
BA_ "GenSigTimeoutMsg_HU_B" SG_ 479 IcHuOverallTripResetAck 0;
BA_ "GenSigTimeoutMsg_HU_A" SG_ 479 IcHuOverallTripResetAck 0;
BA_ "GenSigSendType" SG_ 479 IcHuOverallTripResetAck 1;
BA_ "GenSigTimeoutMsg_HU_High_X445" SG_ 479 IcHuOverallTripResetAck 0;
BA_ "GenSigTimeoutMsg_HU_Mid_X445" SG_ 479 IcHuOverallTripResetAck 0;
BA_ "GenSigTimeoutTime_HU_High_X445" SG_ 479 IcHuOverallTripResetAck 0;
BA_ "GenSigTimeoutTime_HU_Mid_X445" SG_ 479 IcHuOverallTripResetAck 0;
BA_ "GenSigTimeoutMsg_IVI" SG_ 479 IcHuOverallTripResetAck 0;
BA_ "GenSigTimeoutTime_IVI" SG_ 479 IcHuOverallTripResetAck 0;
BA_ "GenSigTimeoutTime_HU_Mid_X451" SG_ 479 IcHuOverallTripReset 0;
BA_ "GenSigTimeoutTime_HU_High_X451" SG_ 479 IcHuOverallTripReset 0;
BA_ "GenSigTimeoutTime_HU_B" SG_ 479 IcHuOverallTripReset 0;
BA_ "GenSigTimeoutTime_HU_A" SG_ 479 IcHuOverallTripReset 0;
BA_ "GenSigTimeoutMsg_HU_Mid_X451" SG_ 479 IcHuOverallTripReset 0;
BA_ "GenSigTimeoutMsg_HU_High_X451" SG_ 479 IcHuOverallTripReset 0;
BA_ "GenSigTimeoutMsg_HU_B" SG_ 479 IcHuOverallTripReset 0;
BA_ "GenSigTimeoutMsg_HU_A" SG_ 479 IcHuOverallTripReset 0;
BA_ "GenSigSendType" SG_ 479 IcHuOverallTripReset 1;
BA_ "GenSigTimeoutMsg_HU_High_X445" SG_ 479 IcHuOverallTripReset 0;
BA_ "GenSigTimeoutMsg_HU_Mid_X445" SG_ 479 IcHuOverallTripReset 0;
BA_ "GenSigTimeoutTime_HU_High_X445" SG_ 479 IcHuOverallTripReset 0;
BA_ "GenSigTimeoutTime_HU_Mid_X445" SG_ 479 IcHuOverallTripReset 0;
BA_ "GenSigTimeoutMsg_IVI" SG_ 479 IcHuOverallTripReset 0;
BA_ "GenSigTimeoutTime_IVI" SG_ 479 IcHuOverallTripReset 0;
BA_ "GenSigTimeoutTime_HU_Mid_X451" SG_ 479 IcHuResetAll 0;
BA_ "GenSigTimeoutTime_HU_High_X451" SG_ 479 IcHuResetAll 0;
BA_ "GenSigTimeoutTime_HU_B" SG_ 479 IcHuResetAll 0;
BA_ "GenSigTimeoutTime_HU_A" SG_ 479 IcHuResetAll 0;
BA_ "GenSigTimeoutMsg_HU_Mid_X451" SG_ 479 IcHuResetAll 0;
BA_ "GenSigTimeoutMsg_HU_High_X451" SG_ 479 IcHuResetAll 0;
BA_ "GenSigTimeoutMsg_HU_B" SG_ 479 IcHuResetAll 0;
BA_ "GenSigTimeoutMsg_HU_A" SG_ 479 IcHuResetAll 0;
BA_ "GenSigSendType" SG_ 479 IcHuResetAll 1;
BA_ "GenSigTimeoutMsg_HU_High_X445" SG_ 479 IcHuResetAll 0;
BA_ "GenSigTimeoutMsg_HU_Mid_X445" SG_ 479 IcHuResetAll 0;
BA_ "GenSigTimeoutTime_HU_High_X445" SG_ 479 IcHuResetAll 0;
BA_ "GenSigTimeoutTime_HU_Mid_X445" SG_ 479 IcHuResetAll 0;
BA_ "GenSigTimeoutMsg_IVI" SG_ 479 IcHuResetAll 0;
BA_ "GenSigTimeoutTime_IVI" SG_ 479 IcHuResetAll 0;
BA_ "GenSigTimeoutTime_HU_Mid_X451" SG_ 490 VInInfoToIPC 0;
BA_ "GenSigTimeoutTime_HU_High_X451" SG_ 490 VInInfoToIPC 0;
BA_ "GenSigTimeoutTime_HU_B" SG_ 490 VInInfoToIPC 0;
BA_ "GenSigTimeoutTime_HU_A" SG_ 490 VInInfoToIPC 0;
BA_ "GenSigTimeoutMsg_HU_Mid_X451" SG_ 490 VInInfoToIPC 0;
BA_ "GenSigTimeoutMsg_HU_High_X451" SG_ 490 VInInfoToIPC 0;
BA_ "GenSigTimeoutMsg_HU_B" SG_ 490 VInInfoToIPC 0;
BA_ "GenSigTimeoutMsg_HU_A" SG_ 490 VInInfoToIPC 0;
BA_ "GenSigSendType" SG_ 490 VInInfoToIPC 2;
BA_ "GenSigTimeoutMsg_HU_High_X445" SG_ 490 VInInfoToIPC 0;
BA_ "GenSigTimeoutMsg_HU_Mid_X445" SG_ 490 VInInfoToIPC 0;
BA_ "GenSigTimeoutTime_HU_High_X445" SG_ 490 VInInfoToIPC 0;
BA_ "GenSigTimeoutTime_HU_Mid_X445" SG_ 490 VInInfoToIPC 0;
BA_ "GenSigTimeoutMsg_IVI" SG_ 490 VInInfoToIPC 0;
BA_ "GenSigTimeoutTime_IVI" SG_ 490 VInInfoToIPC 0;
BA_ "GenSigTimeoutTime_HU_Mid_X451" SG_ 497 HuCcmRearBlwrOnOffReq 0;
BA_ "GenSigTimeoutTime_HU_High_X451" SG_ 497 HuCcmRearBlwrOnOffReq 0;
BA_ "GenSigTimeoutTime_HU_B" SG_ 497 HuCcmRearBlwrOnOffReq 0;
BA_ "GenSigTimeoutTime_HU_A" SG_ 497 HuCcmRearBlwrOnOffReq 0;
BA_ "GenSigTimeoutMsg_HU_Mid_X451" SG_ 497 HuCcmRearBlwrOnOffReq 0;
BA_ "GenSigTimeoutMsg_HU_High_X451" SG_ 497 HuCcmRearBlwrOnOffReq 0;
BA_ "GenSigTimeoutMsg_HU_B" SG_ 497 HuCcmRearBlwrOnOffReq 0;
BA_ "GenSigTimeoutMsg_HU_A" SG_ 497 HuCcmRearBlwrOnOffReq 0;
BA_ "GenSigSendType" SG_ 497 HuCcmRearBlwrOnOffReq 1;
BA_ "GenSigTimeoutMsg_HU_High_X445" SG_ 497 HuCcmRearBlwrOnOffReq 0;
BA_ "GenSigTimeoutMsg_HU_Mid_X445" SG_ 497 HuCcmRearBlwrOnOffReq 0;
BA_ "GenSigTimeoutTime_HU_High_X445" SG_ 497 HuCcmRearBlwrOnOffReq 0;
BA_ "GenSigTimeoutTime_HU_Mid_X445" SG_ 497 HuCcmRearBlwrOnOffReq 0;
BA_ "GenSigTimeoutMsg_IVI" SG_ 497 HuCcmRearBlwrOnOffReq 0;
BA_ "GenSigTimeoutTime_IVI" SG_ 497 HuCcmRearBlwrOnOffReq 0;
BA_ "GenSigTimeoutTime_HU_Mid_X451" SG_ 497 HuCcmExpressCoolSwitchReq 0;
BA_ "GenSigTimeoutTime_HU_High_X451" SG_ 497 HuCcmExpressCoolSwitchReq 0;
BA_ "GenSigTimeoutTime_HU_B" SG_ 497 HuCcmExpressCoolSwitchReq 0;
BA_ "GenSigTimeoutTime_HU_A" SG_ 497 HuCcmExpressCoolSwitchReq 0;
BA_ "GenSigTimeoutMsg_HU_Mid_X451" SG_ 497 HuCcmExpressCoolSwitchReq 0;
BA_ "GenSigTimeoutMsg_HU_High_X451" SG_ 497 HuCcmExpressCoolSwitchReq 0;
BA_ "GenSigTimeoutMsg_HU_B" SG_ 497 HuCcmExpressCoolSwitchReq 0;
BA_ "GenSigTimeoutMsg_HU_A" SG_ 497 HuCcmExpressCoolSwitchReq 0;
BA_ "GenSigSendType" SG_ 497 HuCcmExpressCoolSwitchReq 1;
BA_ "GenSigTimeoutMsg_HU_High_X445" SG_ 497 HuCcmExpressCoolSwitchReq 0;
BA_ "GenSigTimeoutMsg_HU_Mid_X445" SG_ 497 HuCcmExpressCoolSwitchReq 0;
BA_ "GenSigTimeoutTime_HU_High_X445" SG_ 497 HuCcmExpressCoolSwitchReq 0;
BA_ "GenSigTimeoutTime_HU_Mid_X445" SG_ 497 HuCcmExpressCoolSwitchReq 0;
BA_ "GenSigTimeoutMsg_IVI" SG_ 497 HuCcmExpressCoolSwitchReq 0;
BA_ "GenSigTimeoutTime_IVI" SG_ 497 HuCcmExpressCoolSwitchReq 0;
BA_ "GenSigTimeoutTime_HU_Mid_X451" SG_ 497 HuCCmFanSpdReq 0;
BA_ "GenSigTimeoutTime_HU_High_X451" SG_ 497 HuCCmFanSpdReq 0;
BA_ "GenSigTimeoutTime_HU_B" SG_ 497 HuCCmFanSpdReq 0;
BA_ "GenSigTimeoutTime_HU_A" SG_ 497 HuCCmFanSpdReq 0;
BA_ "GenSigTimeoutMsg_HU_Mid_X451" SG_ 497 HuCCmFanSpdReq 0;
BA_ "GenSigTimeoutMsg_HU_High_X451" SG_ 497 HuCCmFanSpdReq 0;
BA_ "GenSigTimeoutMsg_HU_B" SG_ 497 HuCCmFanSpdReq 0;
BA_ "GenSigTimeoutMsg_HU_A" SG_ 497 HuCCmFanSpdReq 0;
BA_ "GenSigSendType" SG_ 497 HuCCmFanSpdReq 1;
BA_ "GenSigTimeoutMsg_HU_High_X445" SG_ 497 HuCCmFanSpdReq 0;
BA_ "GenSigTimeoutMsg_HU_Mid_X445" SG_ 497 HuCCmFanSpdReq 0;
BA_ "GenSigTimeoutTime_HU_High_X445" SG_ 497 HuCCmFanSpdReq 0;
BA_ "GenSigTimeoutTime_HU_Mid_X445" SG_ 497 HuCCmFanSpdReq 0;
BA_ "GenSigTimeoutMsg_IVI" SG_ 497 HuCCmFanSpdReq 0;
BA_ "GenSigTimeoutTime_IVI" SG_ 497 HuCCmFanSpdReq 0;
BA_ "GenSigTimeoutTime_HU_Mid_X451" SG_ 497 HuCCmDistribReq 0;
BA_ "GenSigTimeoutTime_HU_High_X451" SG_ 497 HuCCmDistribReq 0;
BA_ "GenSigTimeoutTime_HU_B" SG_ 497 HuCCmDistribReq 0;
BA_ "GenSigTimeoutTime_HU_A" SG_ 497 HuCCmDistribReq 0;
BA_ "GenSigTimeoutMsg_HU_Mid_X451" SG_ 497 HuCCmDistribReq 0;
BA_ "GenSigTimeoutMsg_HU_High_X451" SG_ 497 HuCCmDistribReq 0;
BA_ "GenSigTimeoutMsg_HU_B" SG_ 497 HuCCmDistribReq 0;
BA_ "GenSigTimeoutMsg_HU_A" SG_ 497 HuCCmDistribReq 0;
BA_ "GenSigSendType" SG_ 497 HuCCmDistribReq 1;
BA_ "GenSigTimeoutMsg_HU_High_X445" SG_ 497 HuCCmDistribReq 0;
BA_ "GenSigTimeoutMsg_HU_Mid_X445" SG_ 497 HuCCmDistribReq 0;
BA_ "GenSigTimeoutTime_HU_High_X445" SG_ 497 HuCCmDistribReq 0;
BA_ "GenSigTimeoutTime_HU_Mid_X445" SG_ 497 HuCCmDistribReq 0;
BA_ "GenSigTimeoutMsg_IVI" SG_ 497 HuCCmDistribReq 0;
BA_ "GenSigTimeoutTime_IVI" SG_ 497 HuCCmDistribReq 0;
BA_ "GenSigTimeoutTime_HU_Mid_X451" SG_ 497 HuCCmDualModeReq 0;
BA_ "GenSigTimeoutTime_HU_High_X451" SG_ 497 HuCCmDualModeReq 0;
BA_ "GenSigTimeoutTime_HU_B" SG_ 497 HuCCmDualModeReq 0;
BA_ "GenSigTimeoutTime_HU_A" SG_ 497 HuCCmDualModeReq 0;
BA_ "GenSigTimeoutMsg_HU_Mid_X451" SG_ 497 HuCCmDualModeReq 0;
BA_ "GenSigTimeoutMsg_HU_High_X451" SG_ 497 HuCCmDualModeReq 0;
BA_ "GenSigTimeoutMsg_HU_B" SG_ 497 HuCCmDualModeReq 0;
BA_ "GenSigTimeoutMsg_HU_A" SG_ 497 HuCCmDualModeReq 0;
BA_ "GenSigSendType" SG_ 497 HuCCmDualModeReq 1;
BA_ "GenSigTimeoutMsg_HU_High_X445" SG_ 497 HuCCmDualModeReq 0;
BA_ "GenSigTimeoutMsg_HU_Mid_X445" SG_ 497 HuCCmDualModeReq 0;
BA_ "GenSigTimeoutTime_HU_High_X445" SG_ 497 HuCCmDualModeReq 0;
BA_ "GenSigTimeoutTime_HU_Mid_X445" SG_ 497 HuCCmDualModeReq 0;
BA_ "GenSigTimeoutMsg_IVI" SG_ 497 HuCCmDualModeReq 0;
BA_ "GenSigTimeoutTime_IVI" SG_ 497 HuCCmDualModeReq 0;
BA_ "GenSigTimeoutTime_HU_Mid_X451" SG_ 497 HuCCmTempReqPass 0;
BA_ "GenSigTimeoutTime_HU_High_X451" SG_ 497 HuCCmTempReqPass 0;
BA_ "GenSigTimeoutTime_HU_B" SG_ 497 HuCCmTempReqPass 0;
BA_ "GenSigTimeoutTime_HU_A" SG_ 497 HuCCmTempReqPass 0;
BA_ "GenSigTimeoutMsg_HU_Mid_X451" SG_ 497 HuCCmTempReqPass 0;
BA_ "GenSigTimeoutMsg_HU_High_X451" SG_ 497 HuCCmTempReqPass 0;
BA_ "GenSigTimeoutMsg_HU_B" SG_ 497 HuCCmTempReqPass 0;
BA_ "GenSigTimeoutMsg_HU_A" SG_ 497 HuCCmTempReqPass 0;
BA_ "GenSigSendType" SG_ 497 HuCCmTempReqPass 1;
BA_ "GenSigTimeoutMsg_HU_High_X445" SG_ 497 HuCCmTempReqPass 0;
BA_ "GenSigTimeoutMsg_HU_Mid_X445" SG_ 497 HuCCmTempReqPass 0;
BA_ "GenSigTimeoutTime_HU_High_X445" SG_ 497 HuCCmTempReqPass 0;
BA_ "GenSigTimeoutTime_HU_Mid_X445" SG_ 497 HuCCmTempReqPass 0;
BA_ "GenSigTimeoutMsg_IVI" SG_ 497 HuCCmTempReqPass 0;
BA_ "GenSigTimeoutTime_IVI" SG_ 497 HuCCmTempReqPass 0;
BA_ "GenSigTimeoutTime_HU_Mid_X451" SG_ 497 HuCCmFreshAirRecircReq 0;
BA_ "GenSigTimeoutTime_HU_High_X451" SG_ 497 HuCCmFreshAirRecircReq 0;
BA_ "GenSigTimeoutTime_HU_B" SG_ 497 HuCCmFreshAirRecircReq 0;
BA_ "GenSigTimeoutTime_HU_A" SG_ 497 HuCCmFreshAirRecircReq 0;
BA_ "GenSigTimeoutMsg_HU_Mid_X451" SG_ 497 HuCCmFreshAirRecircReq 0;
BA_ "GenSigTimeoutMsg_HU_High_X451" SG_ 497 HuCCmFreshAirRecircReq 0;
BA_ "GenSigTimeoutMsg_HU_B" SG_ 497 HuCCmFreshAirRecircReq 0;
BA_ "GenSigTimeoutMsg_HU_A" SG_ 497 HuCCmFreshAirRecircReq 0;
BA_ "GenSigSendType" SG_ 497 HuCCmFreshAirRecircReq 1;
BA_ "GenSigTimeoutMsg_HU_High_X445" SG_ 497 HuCCmFreshAirRecircReq 0;
BA_ "GenSigTimeoutMsg_HU_Mid_X445" SG_ 497 HuCCmFreshAirRecircReq 0;
BA_ "GenSigTimeoutTime_HU_High_X445" SG_ 497 HuCCmFreshAirRecircReq 0;
BA_ "GenSigTimeoutTime_HU_Mid_X445" SG_ 497 HuCCmFreshAirRecircReq 0;
BA_ "GenSigTimeoutMsg_IVI" SG_ 497 HuCCmFreshAirRecircReq 0;
BA_ "GenSigTimeoutTime_IVI" SG_ 497 HuCCmFreshAirRecircReq 0;
BA_ "GenSigTimeoutTime_HU_Mid_X451" SG_ 497 HuCCmAutoReq 0;
BA_ "GenSigTimeoutTime_HU_High_X451" SG_ 497 HuCCmAutoReq 0;
BA_ "GenSigTimeoutTime_HU_B" SG_ 497 HuCCmAutoReq 0;
BA_ "GenSigTimeoutTime_HU_A" SG_ 497 HuCCmAutoReq 0;
BA_ "GenSigTimeoutMsg_HU_Mid_X451" SG_ 497 HuCCmAutoReq 0;
BA_ "GenSigTimeoutMsg_HU_High_X451" SG_ 497 HuCCmAutoReq 0;
BA_ "GenSigTimeoutMsg_HU_B" SG_ 497 HuCCmAutoReq 0;
BA_ "GenSigTimeoutMsg_HU_A" SG_ 497 HuCCmAutoReq 0;
BA_ "GenSigSendType" SG_ 497 HuCCmAutoReq 1;
BA_ "GenSigTimeoutMsg_HU_High_X445" SG_ 497 HuCCmAutoReq 0;
BA_ "GenSigTimeoutMsg_HU_Mid_X445" SG_ 497 HuCCmAutoReq 0;
BA_ "GenSigTimeoutTime_HU_High_X445" SG_ 497 HuCCmAutoReq 0;
BA_ "GenSigTimeoutTime_HU_Mid_X445" SG_ 497 HuCCmAutoReq 0;
BA_ "GenSigTimeoutMsg_IVI" SG_ 497 HuCCmAutoReq 0;
BA_ "GenSigTimeoutTime_IVI" SG_ 497 HuCCmAutoReq 0;
BA_ "GenSigTimeoutTime_HU_Mid_X451" SG_ 497 HuCCmTempReq 0;
BA_ "GenSigTimeoutTime_HU_High_X451" SG_ 497 HuCCmTempReq 0;
BA_ "GenSigTimeoutTime_HU_B" SG_ 497 HuCCmTempReq 0;
BA_ "GenSigTimeoutTime_HU_A" SG_ 497 HuCCmTempReq 0;
BA_ "GenSigTimeoutMsg_HU_Mid_X451" SG_ 497 HuCCmTempReq 0;
BA_ "GenSigTimeoutMsg_HU_High_X451" SG_ 497 HuCCmTempReq 0;
BA_ "GenSigTimeoutMsg_HU_B" SG_ 497 HuCCmTempReq 0;
BA_ "GenSigTimeoutMsg_HU_A" SG_ 497 HuCCmTempReq 0;
BA_ "GenSigSendType" SG_ 497 HuCCmTempReq 1;
BA_ "GenSigTimeoutMsg_HU_High_X445" SG_ 497 HuCCmTempReq 0;
BA_ "GenSigTimeoutMsg_HU_Mid_X445" SG_ 497 HuCCmTempReq 0;
BA_ "GenSigTimeoutTime_HU_High_X445" SG_ 497 HuCCmTempReq 0;
BA_ "GenSigTimeoutTime_HU_Mid_X445" SG_ 497 HuCCmTempReq 0;
BA_ "GenSigTimeoutMsg_IVI" SG_ 497 HuCCmTempReq 0;
BA_ "GenSigTimeoutTime_IVI" SG_ 497 HuCCmTempReq 0;
BA_ "GenSigTimeoutTime_HU_Mid_X451" SG_ 497 HuCCmEconModeReq 0;
BA_ "GenSigTimeoutTime_HU_High_X451" SG_ 497 HuCCmEconModeReq 0;
BA_ "GenSigTimeoutTime_HU_B" SG_ 497 HuCCmEconModeReq 0;
BA_ "GenSigTimeoutTime_HU_A" SG_ 497 HuCCmEconModeReq 0;
BA_ "GenSigTimeoutMsg_HU_Mid_X451" SG_ 497 HuCCmEconModeReq 0;
BA_ "GenSigTimeoutMsg_HU_High_X451" SG_ 497 HuCCmEconModeReq 0;
BA_ "GenSigTimeoutMsg_HU_B" SG_ 497 HuCCmEconModeReq 0;
BA_ "GenSigTimeoutMsg_HU_A" SG_ 497 HuCCmEconModeReq 0;
BA_ "GenSigSendType" SG_ 497 HuCCmEconModeReq 1;
BA_ "GenSigTimeoutMsg_HU_High_X445" SG_ 497 HuCCmEconModeReq 0;
BA_ "GenSigTimeoutMsg_HU_Mid_X445" SG_ 497 HuCCmEconModeReq 0;
BA_ "GenSigTimeoutTime_HU_High_X445" SG_ 497 HuCCmEconModeReq 0;
BA_ "GenSigTimeoutTime_HU_Mid_X445" SG_ 497 HuCCmEconModeReq 0;
BA_ "GenSigTimeoutMsg_IVI" SG_ 497 HuCCmEconModeReq 0;
BA_ "GenSigTimeoutTime_IVI" SG_ 497 HuCCmEconModeReq 0;
BA_ "GenSigTimeoutTime_HU_Mid_X451" SG_ 497 HuCCmMaxDefrstReq 0;
BA_ "GenSigTimeoutTime_HU_High_X451" SG_ 497 HuCCmMaxDefrstReq 0;
BA_ "GenSigTimeoutTime_HU_B" SG_ 497 HuCCmMaxDefrstReq 0;
BA_ "GenSigTimeoutTime_HU_A" SG_ 497 HuCCmMaxDefrstReq 0;
BA_ "GenSigTimeoutMsg_HU_Mid_X451" SG_ 497 HuCCmMaxDefrstReq 0;
BA_ "GenSigTimeoutMsg_HU_High_X451" SG_ 497 HuCCmMaxDefrstReq 0;
BA_ "GenSigTimeoutMsg_HU_B" SG_ 497 HuCCmMaxDefrstReq 0;
BA_ "GenSigTimeoutMsg_HU_A" SG_ 497 HuCCmMaxDefrstReq 0;
BA_ "GenSigSendType" SG_ 497 HuCCmMaxDefrstReq 1;
BA_ "GenSigTimeoutMsg_HU_High_X445" SG_ 497 HuCCmMaxDefrstReq 0;
BA_ "GenSigTimeoutMsg_HU_Mid_X445" SG_ 497 HuCCmMaxDefrstReq 0;
BA_ "GenSigTimeoutTime_HU_High_X445" SG_ 497 HuCCmMaxDefrstReq 0;
BA_ "GenSigTimeoutTime_HU_Mid_X445" SG_ 497 HuCCmMaxDefrstReq 0;
BA_ "GenSigTimeoutMsg_IVI" SG_ 497 HuCCmMaxDefrstReq 0;
BA_ "GenSigTimeoutTime_IVI" SG_ 497 HuCCmMaxDefrstReq 0;
BA_ "GenSigTimeoutTime_HU_Mid_X451" SG_ 497 HuCCmRearDefogReq 0;
BA_ "GenSigTimeoutTime_HU_High_X451" SG_ 497 HuCCmRearDefogReq 0;
BA_ "GenSigTimeoutTime_HU_B" SG_ 497 HuCCmRearDefogReq 0;
BA_ "GenSigTimeoutTime_HU_A" SG_ 497 HuCCmRearDefogReq 0;
BA_ "GenSigTimeoutMsg_HU_Mid_X451" SG_ 497 HuCCmRearDefogReq 0;
BA_ "GenSigTimeoutMsg_HU_High_X451" SG_ 497 HuCCmRearDefogReq 0;
BA_ "GenSigTimeoutMsg_HU_B" SG_ 497 HuCCmRearDefogReq 0;
BA_ "GenSigTimeoutMsg_HU_A" SG_ 497 HuCCmRearDefogReq 0;
BA_ "GenSigSendType" SG_ 497 HuCCmRearDefogReq 1;
BA_ "GenSigTimeoutMsg_HU_High_X445" SG_ 497 HuCCmRearDefogReq 0;
BA_ "GenSigTimeoutMsg_HU_Mid_X445" SG_ 497 HuCCmRearDefogReq 0;
BA_ "GenSigTimeoutTime_HU_High_X445" SG_ 497 HuCCmRearDefogReq 0;
BA_ "GenSigTimeoutTime_HU_Mid_X445" SG_ 497 HuCCmRearDefogReq 0;
BA_ "GenSigTimeoutMsg_IVI" SG_ 497 HuCCmRearDefogReq 0;
BA_ "GenSigTimeoutTime_IVI" SG_ 497 HuCCmRearDefogReq 0;
BA_ "GenSigTimeoutTime_HU_Mid_X451" SG_ 497 HuCCmTempReqDrvr 0;
BA_ "GenSigTimeoutTime_HU_High_X451" SG_ 497 HuCCmTempReqDrvr 0;
BA_ "GenSigTimeoutTime_HU_B" SG_ 497 HuCCmTempReqDrvr 0;
BA_ "GenSigTimeoutTime_HU_A" SG_ 497 HuCCmTempReqDrvr 0;
BA_ "GenSigTimeoutMsg_HU_Mid_X451" SG_ 497 HuCCmTempReqDrvr 0;
BA_ "GenSigTimeoutMsg_HU_High_X451" SG_ 497 HuCCmTempReqDrvr 0;
BA_ "GenSigTimeoutMsg_HU_B" SG_ 497 HuCCmTempReqDrvr 0;
BA_ "GenSigTimeoutMsg_HU_A" SG_ 497 HuCCmTempReqDrvr 0;
BA_ "GenSigSendType" SG_ 497 HuCCmTempReqDrvr 1;
BA_ "GenSigTimeoutMsg_HU_High_X445" SG_ 497 HuCCmTempReqDrvr 0;
BA_ "GenSigTimeoutMsg_HU_Mid_X445" SG_ 497 HuCCmTempReqDrvr 0;
BA_ "GenSigTimeoutTime_HU_High_X445" SG_ 497 HuCCmTempReqDrvr 0;
BA_ "GenSigTimeoutTime_HU_Mid_X445" SG_ 497 HuCCmTempReqDrvr 0;
BA_ "GenSigTimeoutMsg_IVI" SG_ 497 HuCCmTempReqDrvr 0;
BA_ "GenSigTimeoutTime_IVI" SG_ 497 HuCCmTempReqDrvr 0;
BA_ "GenSigTimeoutTime_HU_Mid_X451" SG_ 497 HuCCmAirConCompReq 0;
BA_ "GenSigTimeoutTime_HU_High_X451" SG_ 497 HuCCmAirConCompReq 0;
BA_ "GenSigTimeoutTime_HU_B" SG_ 497 HuCCmAirConCompReq 0;
BA_ "GenSigTimeoutTime_HU_A" SG_ 497 HuCCmAirConCompReq 0;
BA_ "GenSigTimeoutMsg_HU_Mid_X451" SG_ 497 HuCCmAirConCompReq 0;
BA_ "GenSigTimeoutMsg_HU_High_X451" SG_ 497 HuCCmAirConCompReq 0;
BA_ "GenSigTimeoutMsg_HU_B" SG_ 497 HuCCmAirConCompReq 0;
BA_ "GenSigTimeoutMsg_HU_A" SG_ 497 HuCCmAirConCompReq 0;
BA_ "GenSigSendType" SG_ 497 HuCCmAirConCompReq 1;
BA_ "GenSigTimeoutMsg_HU_High_X445" SG_ 497 HuCCmAirConCompReq 0;
BA_ "GenSigTimeoutMsg_HU_Mid_X445" SG_ 497 HuCCmAirConCompReq 0;
BA_ "GenSigTimeoutTime_HU_High_X445" SG_ 497 HuCCmAirConCompReq 0;
BA_ "GenSigTimeoutTime_HU_Mid_X445" SG_ 497 HuCCmAirConCompReq 0;
BA_ "GenSigTimeoutMsg_IVI" SG_ 497 HuCCmAirConCompReq 0;
BA_ "GenSigTimeoutTime_IVI" SG_ 497 HuCCmAirConCompReq 0;
BA_ "GenSigTimeoutTime_HU_Mid_X451" SG_ 497 HuCCmHVAcOFFReq 0;
BA_ "GenSigTimeoutTime_HU_High_X451" SG_ 497 HuCCmHVAcOFFReq 0;
BA_ "GenSigTimeoutTime_HU_B" SG_ 497 HuCCmHVAcOFFReq 0;
BA_ "GenSigTimeoutTime_HU_A" SG_ 497 HuCCmHVAcOFFReq 0;
BA_ "GenSigTimeoutMsg_HU_Mid_X451" SG_ 497 HuCCmHVAcOFFReq 0;
BA_ "GenSigTimeoutMsg_HU_High_X451" SG_ 497 HuCCmHVAcOFFReq 0;
BA_ "GenSigTimeoutMsg_HU_B" SG_ 497 HuCCmHVAcOFFReq 0;
BA_ "GenSigTimeoutMsg_HU_A" SG_ 497 HuCCmHVAcOFFReq 0;
BA_ "GenSigSendType" SG_ 497 HuCCmHVAcOFFReq 1;
BA_ "GenSigTimeoutMsg_HU_High_X445" SG_ 497 HuCCmHVAcOFFReq 0;
BA_ "GenSigTimeoutMsg_HU_Mid_X445" SG_ 497 HuCCmHVAcOFFReq 0;
BA_ "GenSigTimeoutTime_HU_High_X445" SG_ 497 HuCCmHVAcOFFReq 0;
BA_ "GenSigTimeoutTime_HU_Mid_X445" SG_ 497 HuCCmHVAcOFFReq 0;
BA_ "GenSigTimeoutMsg_IVI" SG_ 497 HuCCmHVAcOFFReq 0;
BA_ "GenSigTimeoutTime_IVI" SG_ 497 HuCCmHVAcOFFReq 0;
BA_ "GenSigTimeoutTime_HU_Mid_X451" SG_ 497 HuCCmQueryFlag 0;
BA_ "GenSigTimeoutTime_HU_High_X451" SG_ 497 HuCCmQueryFlag 0;
BA_ "GenSigTimeoutTime_HU_B" SG_ 497 HuCCmQueryFlag 0;
BA_ "GenSigTimeoutTime_HU_A" SG_ 497 HuCCmQueryFlag 0;
BA_ "GenSigTimeoutMsg_HU_Mid_X451" SG_ 497 HuCCmQueryFlag 0;
BA_ "GenSigTimeoutMsg_HU_High_X451" SG_ 497 HuCCmQueryFlag 0;
BA_ "GenSigTimeoutMsg_HU_B" SG_ 497 HuCCmQueryFlag 0;
BA_ "GenSigTimeoutMsg_HU_A" SG_ 497 HuCCmQueryFlag 0;
BA_ "GenSigSendType" SG_ 497 HuCCmQueryFlag 1;
BA_ "GenSigTimeoutMsg_HU_High_X445" SG_ 497 HuCCmQueryFlag 0;
BA_ "GenSigTimeoutMsg_HU_Mid_X445" SG_ 497 HuCCmQueryFlag 0;
BA_ "GenSigTimeoutTime_HU_High_X445" SG_ 497 HuCCmQueryFlag 0;
BA_ "GenSigTimeoutTime_HU_Mid_X445" SG_ 497 HuCCmQueryFlag 0;
BA_ "GenSigTimeoutMsg_IVI" SG_ 497 HuCCmQueryFlag 0;
BA_ "GenSigTimeoutTime_IVI" SG_ 497 HuCCmQueryFlag 0;
BA_ "GenSigTimeoutTime_HU_Mid_X451" SG_ 497 HuCCmUserInterventionStatusFlag 0;
BA_ "GenSigTimeoutTime_HU_High_X451" SG_ 497 HuCCmUserInterventionStatusFlag 0;
BA_ "GenSigTimeoutTime_HU_B" SG_ 497 HuCCmUserInterventionStatusFlag 0;
BA_ "GenSigTimeoutTime_HU_A" SG_ 497 HuCCmUserInterventionStatusFlag 0;
BA_ "GenSigTimeoutMsg_HU_Mid_X451" SG_ 497 HuCCmUserInterventionStatusFlag 0;
BA_ "GenSigTimeoutMsg_HU_High_X451" SG_ 497 HuCCmUserInterventionStatusFlag 0;
BA_ "GenSigTimeoutMsg_HU_B" SG_ 497 HuCCmUserInterventionStatusFlag 0;
BA_ "GenSigTimeoutMsg_HU_A" SG_ 497 HuCCmUserInterventionStatusFlag 0;
BA_ "GenSigSendType" SG_ 497 HuCCmUserInterventionStatusFlag 1;
BA_ "GenSigTimeoutMsg_HU_High_X445" SG_ 497 HuCCmUserInterventionStatusFlag 0;
BA_ "GenSigTimeoutMsg_HU_Mid_X445" SG_ 497 HuCCmUserInterventionStatusFlag 0;
BA_ "GenSigTimeoutTime_HU_High_X445" SG_ 497 HuCCmUserInterventionStatusFlag 0;
BA_ "GenSigTimeoutTime_HU_Mid_X445" SG_ 497 HuCCmUserInterventionStatusFlag 0;
BA_ "GenSigTimeoutMsg_IVI" SG_ 497 HuCCmUserInterventionStatusFlag 0;
BA_ "GenSigTimeoutTime_IVI" SG_ 497 HuCCmUserInterventionStatusFlag 0;
VAL_ 454 IcHuTempUnitSet 1 "Fahrenheit" 0 "Celcius" ;
VAL_ 454 IcHuDistUnitSet 1 "Miles" 0 "Km" ;
VAL_ 454 IcHuClockMode 1 "24 Hour Mode" 0 "12 Hour Mode" ;
VAL_ 454 IcHuMonthInfo 15 "Reserved for future use." 14 "Reserved for future use." 13 "Reserved for future use." 12 "December" 11 "November" 10 "October" 9 "September" 8 "August" 7 "July" 6 "June" 5 "May" 4 "April" 3 "March" 2 "February" 1 "January" 0 "Unused" ;
VAL_ 454 IcLangSettings 31 "Reserved for future use" 30 "Reserved for future use" 29 "Reserved for future use" 28 "Reserved for future use" 27 "Reserved for future use" 26 "Reserved for future use" 25 "Reserved for future use" 24 "Reserved for future use" 23 "Reserved for future use" 22 "Reserved for future use" 21 "Reserved for future use" 20 "Reserved for future use" 19 "Reserved for future use" 18 "Reserved for future use" 17 "Reserved for future use" 16 "Reserved for future use" 15 "Reserved for future use" 14 "Reserved for future use" 13 "Albanian" 12 "Czech" 11 "Russian" 10 "Ukranian" 9 "Arabic" 8 "Turkish" 7 "Portugese" 6 "German" 5 "French" 4 "Polish" 3 "Italian" 2 "Spanish" 1 "UK English" 0 "Indian English" ;
VAL_ 459 BCmAntitheftFeatureState 1 "BCM Antitheft feature Activated" 0 "BCM Antitheft feature Deactivated" ;
VAL_ 459 BCmAntitheftKeyConfirmation 3 "Pairing not required" 2 "Pairing initiated" 1 "Pairing Successful" 0 "Pairing Unsuccessful" ;
VAL_ 459 BcmHuCkdState 1 "CKD vehicle" 0 "Non-CKD vehicle" ;
VAL_ 460 HuAntitheftFeatureState 1 "HU Antitheft feature activated" 0 "HU Antitheft feature Deactivated" ;
VAL_ 460 HuBcmQueryInfo 3 "Reserved for future use" 2 "Reserved for future use" 1 "HU request the BCM to resend values" 0 "No Query requested from HU to BCM" ;
VAL_ 464 HuIcDriveproConfig 3 "Reserved" 2 "Reserved" 1 "DrivePro Present" 0 "DrivePro Not Present" ;
VAL_ 464 HuIcDriveProConfigEventStatus 1 "Config Event" 0 "No Event" ;
VAL_ 464 HuIcTripAReset 1 "Yes" 0 "No" ;
VAL_ 464 HuIcTripAResetAck 1 "Yes" 0 "No" ;
VAL_ 464 HuIcTripBReset 1 "Yes" 0 "No" ;
VAL_ 464 HuIcTripBResetAck 1 "Yes" 0 "No" ;
VAL_ 464 HuIcResetAll 1 "Yes" 0 "No" ;
VAL_ 464 HuIcTripResetAckEventStatus 1 "ResetAck Event" 0 "No Event" ;
VAL_ 464 HuIcTripResetEventStatus 1 "Reset Event" 0 "No Event" ;
VAL_ 464 HuIcOverallTripReset 1 "Yes" 0 "No" ;
VAL_ 464 HuIcOverallTripResetAck 1 "Yes" 0 "No" ;
VAL_ 464 HuIcResetAllAck 1 "Yes" 0 "No" ;
VAL_ 466 HuPDcVehicleImageAck 7 "Vehicle Image 8" 6 "Vehicle Image 7" 5 "Vehicle Image6" 4 "Vehicle Image 5" 3 "Vehicle Image4" 2 "Vehicle Image 3" 1 "Vehicle Image 2" 0 "Vehicle Image 1" ;
VAL_ 466 PDcLowSpeedActivationReq 1 "active" 0 "Inactive" ;
VAL_ 466 PDcRearToneReq 15 "Reserved for future use." 14 "Reserved for future use." 13 "Reserved for future use." 12 "Reserved for future use." 11 "Reserved for future use." 10 "Reserved for future use." 9 "Reserved for future use." 8 "Reserved for future use." 7 "Reserved for future use." 6 "Reserved for future use." 5 "Reserved for future use." 4 "Reserved for future use." 3 "Reserved for future use." 2 "Tone 3" 1 "Tone 2" 0 "Tone 1" ;
VAL_ 466 HuPDcFrontAudioMuteStateAck 1 "Mute" 0 "Unmute" ;
VAL_ 466 HuPDcRearNoOfSensAck 7 "Reserved for future" 6 "Reserved for future" 5 "Reserved for future" 4 "Reserved for future" 3 "Reserved for future" 2 "4 Sensors" 1 "3 Sensors" 0 "2 Sensors" ;
VAL_ 466 PDcFrontAudioMuteReq 1 "Mute" 0 "Unmute" ;
VAL_ 466 HuPDcReqType 7 "reserved" 6 "reserved" 5 "HUPDCconfig Ack" 4 "setting update" 3 "config query" 2 "factory setting Req" 1 "HU_PDC Deactivate Req" 0 "HU_PDC Activate Req" ;
VAL_ 466 HuPDcRearToneAck 15 "Reserved for future use." 14 "Reserved for future use." 13 "Reserved for future use." 12 "Reserved for future use." 11 "Reserved for future use." 10 "Reserved for future use." 9 "Reserved for future use." 8 "Reserved for future use." 7 "Reserved for future use." 6 "Reserved for future use." 5 "Reserved for future use." 4 "Reserved for future use." 3 "Reserved for future use." 2 "Tone 3" 1 "Tone 2" 0 "Tone 1" ;
VAL_ 466 HuPDcFrontToneAck 15 "Reserved for future use." 14 "Reserved for future use." 13 "Reserved for future use." 12 "Reserved for future use." 11 "Reserved for future use." 10 "Reserved for future use." 9 "Reserved for future use." 8 "Reserved for future use." 7 "Reserved for future use." 6 "Reserved for future use." 5 "Reserved for future use." 4 "Reserved for future use." 3 "Reserved for future use." 2 "Tone 3" 1 "Tone 2" 0 "Tone 1		" ;
VAL_ 466 HuPDcFrontNoOfSensAck 7 "Reserved for future use." 6 "Reserved for future use." 5 "Reserved for future use." 4 "Reserved for future use." 3 "Reserved for future use." 2 "4 Sensors" 1 "3 Sensors" 0 "2 Sensors" ;
VAL_ 466 PDcFrontToneReq 15 "Reserved for future use." 14 "Reserved for future use." 13 "Reserved for future use." 12 "Reserved for future use." 11 "Reserved for future use." 10 "Reserved for future use." 9 "Reserved for future use" 8 "Reserved for future use" 7 "Reserved for future use" 6 "Reserved for future use" 5 "Reserved for future use" 4 "Reserved for future use" 3 "Reserved for future use" 2 "Tone 3" 1 "Tone 2" 0 "Tone 1" ;
VAL_ 466 HuPDCFrontActivationStateAck 1 "Active" 0 "Inactive" ;
VAL_ 466 PDcFrontActivationStateReq 1 "Active" 0 "Inactive" ;
VAL_ 466 HuPDCLowSpeedActivationAck 1 "Active" 0 "Inactive" ;
VAL_ 466 RVcOverlayTypeAck 1 "Dynamic Overlay" 0 "Static Overlay" ;
VAL_ 466 RVcImageRotationTypeAck 1 "180 degree rotation" 0 "No rotation" ;
VAL_ 469 HuIcTempUnitSet 1 "Fahrenheit" 0 "Celcius" ;
VAL_ 469 HuIcDistUnitSet 1 "Miles" 0 "Km" ;
VAL_ 469 HuIcFuelUnitSet 3 "SNA" 2 "mpg" 1 "ltr/100km" 0 "Km/hr" ;
VAL_ 469 HuIcClockMode 1 "24 Hour Mode" 0 "12 Hour Mode" ;
VAL_ 469 QueryIcHuUnitSetInfo 1 " Query" 0 "No Query" ;
VAL_ 469 HuIcRtcTypeNew 1 "No RTC" 0 "RTC" ;
VAL_ 469 HuIcMonthInfo 15 "Reserved for future use." 14 "Reserved for future use." 13 "Reserved for future use." 12 "December" 11 "November" 10 "October" 9 "September" 8 "August" 7 "July" 6 "June" 5 "May" 4 "April" 3 "March" 2 "February" 1 "January" 0 "Unused" ;
VAL_ 469 HuLangSettings 31 "Reserved for future use" 30 "Reserved for future use" 29 "Reserved for future use" 28 "Reserved for future use" 27 "Reserved for future use" 26 "Reserved for future use" 25 "Reserved for future use" 24 "Reserved for future use" 23 "Reserved for future use" 22 "Reserved for future use" 21 "Reserved for future use" 20 "Reserved for future use" 19 "Reserved for future use" 18 "Reserved for future use" 17 "Reserved for future use" 16 "Reserved for future use" 15 "Reserved for future use" 14 "Reserved for future use" 13 "Albanian" 12 "Czech" 11 "Russian" 10 "Ukranian" 9 "Arabic" 8 "Turkish" 7 "Portugese" 6 "German" 5 "French" 4 "Polish" 3 "Italian" 2 "Spanish" 1 "UK English" 0 "Indian English" ;
VAL_ 469 HuIcRtcType 1 "RTC" 0 "No RTC" ;
VAL_ 470 HuIcTempUnitSetAck 1 "Fahrenheit" 0 "Celcius" ;
VAL_ 470 HuIcFuelUnitSetAck 3 "SNA" 2 "mpg" 1 "ltr/100km" 0 "Km/hr" ;
VAL_ 470 HuIcDistUnitSetAck 1 "Miles" 0 "Km" ;
VAL_ 472 CcmHuAutoConfig 1 " Auto switch in HU Available" 0 " Auto switch in HU Not Available" ;
VAL_ 472 CcmHuHvacOffConfig 1 " HVAC OFF switch in HU Available" 0 " HVAC OFF switch in HU Not Available" ;
VAL_ 472 CCmHuRearDefogConfig 1 "Rear Defogger feature Available" 0 "Rear Defogger feature Not Available" ;
VAL_ 472 CCmHuColorThemeConfig 1 "Color Theme feature Available" 0 "Color Themer feature Not Available" ;
VAL_ 472 CCmHuAutoDefogConfig 1 "Auto Defog feature Available" 0 "Auto Defog feature Not Available" ;
VAL_ 472 CcmHuRearBlwrConfig 1 "Rear Blower feature Available" 0 "Rear Blower feature Not Available" ;
VAL_ 472 CCmHuEconConfig 1 "ECON Cooling feature Not Available" 0 "ECON Cooling feature Available" ;
VAL_ 472 CCmHuExpressCoolConfig 1 "Express Cooling feature Available" 0 "Express Cooling feature Not Available" ;
VAL_ 472 CCmHuLowFanSpdConfigValue 15 "Reserved" 14 "Reserved" 13 "Reserved" 12 "Reserved" 11 "Reserved" 10 "Reserved" 9 "Reserved" 8 "Speed 8" 7 "Speed 7" 6 "Speed 6" 5 "Speed 5" 4 "Speed 4" 3 "Speed 3" 2 "Speed 2" 1 "Speed 1" 0 "Speed 0" ;
VAL_ 472 CCmHuHiFanSpdConfigValue 15 "Reserved" 14 "Reserved" 13 "Reserved" 12 "Reserved" 11 "Reserved" 10 "Reserved" 9 "Reserved" 8 "Speed 8" 7 "Speed 7" 6 "Speed 6" 5 "Speed 5" 4 "Speed 4" 3 "Speed 3" 2 "Speed 2" 1 "Speed 1" 0 "Speed 0" ;
VAL_ 472 CCmHuLowTempConfigValue 31 "HI" 30 "Reserved" 29 "30 Deg C" 28 "29.5 Deg C" 27 "29 Deg C" 26 "28.5 Deg C" 25 "28 Deg C" 24 "27.5 Deg C" 23 "27 Deg C" 22 "26.5 Deg C" 21 "26 Deg C" 20 "25.5 Deg C" 19 "25 Deg C" 18 "24.5 Deg C" 17 "24 Deg C" 16 "23.5 Deg C" 15 "23 Deg C" 14 "22.5 Deg C" 13 "22 Deg C" 12 "21.5 Deg C" 11 "21 Deg C" 10 "20.5 Deg C" 9 "20 Deg C" 8 "19.5 Deg C" 7 "19 Deg C" 6 "18.5 Deg C" 5 "18 Deg C" 4 "17.5 Deg C" 3 "17 Deg C" 2 "16.5 Deg C" 1 "16 Deg C" 0 "LO" ;
VAL_ 472 CCmHuHiTempConfigValue 31 "HI" 30 "Reserved" 29 "30 Deg C" 28 "29.5 Deg C" 27 "29 Deg C" 26 "28.5 Deg C" 25 "28 Deg C" 24 "27.5 Deg C" 23 "27 Deg C" 22 "26.5 Deg C" 21 "26 Deg C" 20 "25.5 Deg C" 19 "25 Deg C" 18 "24.5 Deg C" 17 "24 Deg C" 16 "23.5 Deg C" 15 "23 Deg C" 14 "22.5 Deg C" 13 "22 Deg C" 12 "21.5 Deg C" 11 "21 Deg C" 10 "20.5 Deg C" 9 "20 Deg C" 8 "19.5 Deg C" 7 "19 Deg C" 6 "18.5 Deg C" 5 "18 Deg C" 4 "17.5 Deg C" 3 "17 Deg C" 2 "16.5 Deg C" 1 "16 Deg C" 0 "LO" ;
VAL_ 474 HuCcmAutoConfigAck 1 "Auto switch available configuration acknowledgement" 0 "Auto switch Not available configuration acknowledgement" ;
VAL_ 474 HuCcmHvacOffConfigAck 1 "HVAC OFF switch  available configuration acknowledgement" 0 "HVAC OFF switch Not available configuration acknowledgement" ;
VAL_ 474 HuCcmAutoDefogConfigAck 1 "Auto Defog feature available configuration acknowledgement" 0 "Auto Defog feature Not available configuration acknowledgement" ;
VAL_ 474 HuCcmColorThemeConfigAck 1 "Color Theme feature available configuration acknowledgement" 0 "Color Theme feature Not available configuration acknowledgement" ;
VAL_ 474 HuCcmRearDefogConfigAck 1 "Rear Defogger feature available configuration acknowledgement" 0 "Rear Defogger feature Not available configuration acknowledgement" ;
VAL_ 474 HuCcmRearBlwrConfigAck 1 "Rear Blower feature  available configuration acknowledgement" 0 "Rear Blower feature Not available configuration acknowledgement" ;
VAL_ 474 HuCcmEconConfigAck 1 "ECON feature Not available configuration acknowledgement" 0 "ECON feature available configuration acknowledgement" ;
VAL_ 474 HuCcmExpressCoolConfigAck 1 "Express Cooling feature Available configuration acknowledgement" 0 "Express Cooling feature Not Available configuration acknowledgement" ;
VAL_ 474 HuCCmLowFanSpdConfigValueAck 15 "Reserved" 14 "Reserved" 13 "Reserved" 12 "Reserved" 11 "Reserved" 10 "Reserved" 9 "Reserved" 8 "Speed 8" 7 "Speed 7" 6 "Speed 6" 5 "Speed 5" 4 "Speed 4" 3 "Speed 3" 2 "Speed 2" 1 "Speed 1" 0 "Speed 0" ;
VAL_ 474 HuCCmHiFanSpdConfigValueAck 15 "Reserved" 14 "Reserved" 13 "Reserved" 12 "Reserved" 11 "Reserved" 10 "Reserved" 9 "Reserved" 8 "Speed 8" 7 "Speed 7" 6 "Speed 6" 5 "Speed 5" 4 "Speed 4" 3 "Speed 3" 2 "Speed 2" 1 "Speed 1" 0 "Speed 0" ;
VAL_ 474 HuCCmLowTempConfigValueAck 31 "HI" 30 "Reserved" 29 "30 Deg C" 28 "29.5 Deg C" 27 "29 Deg C" 26 "28.5 Deg C" 25 "28 Deg C" 24 "27.5 Deg C" 23 "27 Deg C" 22 "26.5 Deg C" 21 "26 Deg C" 20 "25.5 Deg C" 19 "25 Deg C" 18 "24.5 Deg C" 17 "24 Deg C" 16 "23.5 Deg C" 15 "23 Deg C" 14 "22.5 Deg C" 13 "22 Deg C" 12 "21.5 Deg C" 11 "21 Deg C" 10 "20.5 Deg C" 9 "20 Deg C" 8 "19.5 Deg C" 7 "19 Deg C" 6 "18.5 Deg C" 5 "18 Deg C" 4 "17.5 Deg C" 3 "17 Deg C" 2 "16.5 Deg C" 1 "16 Deg C" 0 "LO" ;
VAL_ 474 HuCCmFanControlDuringVRAck 3 "Reserved" 2 "Available" 1 "Not Available" 0 "Reserved" ;
VAL_ 474 HuCCmHiTempConfigValueAck 31 "HI" 30 "Reserved" 29 "30 Deg C" 28 "29.5 Deg C" 27 "29 Deg C" 26 "28.5 Deg C" 25 "28 Deg C" 24 "27.5 Deg C" 23 "27 Deg C" 22 "26.5 Deg C" 21 "26 Deg C" 20 "25.5 Deg C" 19 "25 Deg C" 18 "24.5 Deg C" 17 "24 Deg C" 16 "23.5 Deg C" 15 "23 Deg C" 14 "22.5 Deg C" 13 "22 Deg C" 12 "21.5 Deg C" 11 "21 Deg C" 10 "20.5 Deg C" 9 "20 Deg C" 8 "19.5 Deg C" 7 "19 Deg C" 6 "18.5 Deg C" 5 "18 Deg C" 4 "17.5 Deg C" 3 "17 Deg C" 2 "16.5 Deg C" 1 "16 Deg C" 0 "LO" ;
VAL_ 475 HuIcAlertFeatureTypeAck 3 "Reserved" 2 "Reserved" 1 "Voice & Text" 0 "Text Only" ;
VAL_ 475 HuIcAlertFeaturePresenceAck 1 "Present" 0 "Not Present" ;
VAL_ 476 HuIcVoiceAlertFeaturePresence 1 "Present" 0 "Not Present" ;
VAL_ 476 HuIcVoiceAlertSelectionState 1 "Enabled" 0 "Disabled" ;
VAL_ 476 HuIcTextAlertSelectionState 1 "Enabled" 0 "Disabled" ;
VAL_ 477 IcHuVoiceAlertSelectionState 1 "Enabled" 0 "Disabled" ;
VAL_ 477 IcHuAlertFeatureType 3 "Reserved" 2 "Reserved" 1 "Voice & Text" 0 "Text Only" ;
VAL_ 477 IcHuAlertFeaturePresence 1 "Present" 0 "Not Present" ;
VAL_ 478 IcHuVoiceAlertFeaturePresenceAck 1 "Present" 0 "Not Present" ;
VAL_ 478 IcHuVoiceAlertSelectionStateAck 1 "Enabled" 0 "Disabled" ;
VAL_ 478 IcHuTextAlertSelectionStateAck 1 "Enabled" 0 "Disabled" ;
VAL_ 479 IcHuDriveproConfigAck 3 "Reserved" 2 "Reserved" 1 "DrivePro Present" 0 "DrivePro Not Present" ;
VAL_ 479 IcHuDriveProConfigAckEventStatus 1 "Config Ack Event" 0 "No Event" ;
VAL_ 479 IcHuTripAReset 1 "Yes" 0 "No" ;
VAL_ 479 IcHuTripAResetAck 1 "Yes" 0 "No" ;
VAL_ 479 IcHuTripBReset 1 "Yes" 0 "No" ;
VAL_ 479 IcHuTripBResetAck 1 "Yes" 0 "No" ;
VAL_ 479 IcHuResetAllAck 1 "Yes" 0 "No" ;
VAL_ 479 IcHuTripResetAckEventStatus 1 "ResetAck Event" 0 "No Event" ;
VAL_ 479 IcHuTripResetEventStatus 1 "Reset Event" 0 "No Event" ;
VAL_ 479 IcHuOverallTripResetAck 1 "Yes" 0 "No" ;
VAL_ 479 IcHuOverallTripReset 1 "Yes" 0 "No" ;
VAL_ 479 IcHuResetAll 1 "Yes" 0 "No" ;
VAL_ 497 HuCcmRearBlwrOnOffReq 1 "Rear Blower ON" 0 "Rear Blower OFF" ;
VAL_ 497 HuCcmExpressCoolSwitchReq 1 "Express Cool  ON" 0 "Express Cool  OFF" ;
VAL_ 497 HuCCmFanSpdReq 15 "Reserved" 14 "Reserved" 13 "Reserved" 12 "Reserved" 11 "Reserved" 10 "Reserved" 9 "Reserved" 8 "Reserved" 7 "Speed 7" 6 "Speed 6" 5 "Speed 5" 4 "Speed 4" 3 "Speed 3" 2 "Speed 2" 1 "Speed 1" 0 "Speed0(only for FATC dual)/unused (ETC and FATC)" ;
VAL_ 497 HuCCmDistribReq 7 "Reserved" 6 "Reserved" 5 "DefrostMode Status" 4 "LegDefrostMode Status" 3 "LegMode Status" 2 "Chest-LegMode Status" 1 "ChestModeStatus" 0 "Reserved" ;
VAL_ 497 HuCCmDualModeReq 1 "Dual Mode ON" 0 "Dual Mode OFF" ;
VAL_ 497 HuCCmTempReqPass 31 "HI" 30 "Reserved" 29 "30 Deg C" 28 "29.5 Deg C" 27 "29 Deg C" 26 "28.5 Deg C" 25 "28 Deg C" 24 "27.5 Deg C" 23 "27 Deg C" 22 "26.5 Deg C" 21 "26 Deg C" 20 "25.5 Deg C" 19 "25 Deg C" 18 "24.5 Deg C" 17 "24 Deg C" 16 "23.5 Deg C" 15 "23 Deg C" 14 "22.5 Deg C" 13 "22 Deg C" 12 "21.5 Deg C" 11 "21 Deg C" 10 "20.5 Deg C" 9 "20 Deg C" 8 "19.5 Deg C" 7 "19 Deg C" 6 "18.5 Deg C" 5 "18 Deg C" 4 "17.5 Deg C" 3 "17 Deg C" 2 "16.5 Deg C" 1 "16 Deg C" 0 "LO" ;
VAL_ 497 HuCCmFreshAirRecircReq 3 "Reserved" 2 "Fresh Air ON" 1 "Recirculation with AQS (applicable for dual zone FATC)" 0 "Recirculation ON" ;
VAL_ 497 HuCCmAutoReq 1 "Auto ON" 0 "Auto OFF" ;
VAL_ 497 HuCCmTempReq 31 "HI" 30 "Reserved" 29 "30 Deg C" 28 "29.5 Deg C" 27 "29 Deg C" 26 "28.5 Deg C" 25 "28 Deg C" 24 "27.5 Deg C" 23 "27 Deg C" 22 "26.5 Deg C" 21 "26 Deg C" 20 "25.5 Deg C" 19 "25 Deg C" 18 "24.5 Deg C" 17 "24 Deg C" 16 "23.5 Deg C" 15 "23 Deg C" 14 "22.5 Deg C" 13 "22 Deg C" 12 "21.5 Deg C" 11 "21 Deg C" 10 "20.5 Deg C" 9 "20 Deg C" 8 "19.5 Deg C" 7 "19 Deg C" 6 "18.5 Deg C" 5 "18 Deg C" 4 "17.5 Deg C" 3 "17 Deg C" 2 "16.5 Deg C" 1 "16 Deg C" 0 "LO" ;
VAL_ 497 HuCCmEconModeReq 1 "Economy ON" 0 "Economy OFF" ;
VAL_ 497 HuCCmMaxDefrstReq 1 "Max defrost ON" 0 "Max defrost OFF" ;
VAL_ 497 HuCCmRearDefogReq 1 "Rear defog is ON" 0 "Rear defog is OFF" ;
VAL_ 497 HuCCmTempReqDrvr 31 "HI" 30 "Reserved" 29 "30 Deg C" 28 "29.5 Deg C" 27 "29 Deg C" 26 "28.5 Deg C" 25 "28 Deg C" 24 "27.5 Deg C" 23 "27 Deg C" 22 "26.5 Deg C" 21 "26 Deg C" 20 "25.5 Deg C" 19 "25 Deg C" 18 "24.5 Deg C" 17 "24 Deg C" 16 "23.5 Deg C" 15 "23 Deg C" 14 "22.5 Deg C" 13 "22 Deg C" 12 "21.5 Deg C" 11 "21 Deg C" 10 "20.5 Deg C" 9 "20 Deg C" 8 "19.5 Deg C" 7 "19 Deg C" 6 "18.5 Deg C" 5 "18 Deg C" 4 "17.5 Deg C" 3 "17 Deg C" 2 "16.5 Deg C" 1 "16 Deg C" 0 "LO" ;
VAL_ 497 HuCCmAirConCompReq 1 "AC is ON" 0 "AC is OFF" ;
VAL_ 497 HuCCmHVAcOFFReq 1 "Control panel ON" 0 "Control panel OFF" ;
VAL_ 497 HuCCmQueryFlag 1 "Query" 0 "No Query" ;
VAL_ 497 HuCCmUserInterventionStatusFlag 31 "Reserved" 30 "Reserved" 29 "Reserved" 28 "Reserved" 27 "Reserved" 26 "Reserved" 25 "Reserved" 24 "Reserved" 23 "Reserved" 22 "Reserved" 21 "Reserved" 20 "Reserved" 19 "Ionizer Flag" 18 "Rear Blower Flag" 17 "FL Seat Ventilation Flag		

" 16 "FR Seat Ventilation Flag		

" 15 "AI Prediction Flag		

" 14 "Express Cool Flag" 13 "Rear defog Flag" 12 "Temperature Wheel  flag" 11 "Dual button flag" 10 "Fan speed wheel flag" 9 "Temperature Wheel driver flag" 8 "Temperature Wheel Passenger flag" 7 "Distribution button flag" 6 "Recirculation button flag" 5 "Maxdefrost button flag" 4 "Off button flag" 3 "Auto button flag" 2 "Econ button flag" 1 "AC Button flag" 0 "HuCCmUserInterventionStatusFlagClear" ;
